[part 12 of 22: package /Cluster]
AUTOSAR XML (schema 4-3-0)
package /Cluster  (continued)
  can cluster E3V_K2CANFD: baudrate=500000, protocol-name=CAN, protocol-version=2.0, bus-off-recovery={bor-counter-l-1-to-l-2=1, bor-time-l-1=0.05, bor-time-l-2=0.2}, can-fd-baudrate=500000  (continued)
    can physical channel CHNL: comm-connectors=CN_E3V_K2CANFD  (continued)
      frame ZV_01_XIX_E3V_K2CANFD: id 0x184, to SAM, frame-length=8, can-addressing-mode=STANDARD, can-frame-rx-behavior=CAN-FD, can-frame-tx-behavior=CAN-FD
        pdu ZV_01_XIX_E3V_K2CANFD: length=8, transmission-mode-false-timing={cyclic-timing={time-offset=0.0, time-period=1.0}, event-controlled-timing={number-of-repetitions=5, repetition-period=0.02}}, transmission-mode-true-timing=cyclic-timing={time-offset=0.0, time-period=0.02}, unused-bit-pattern=0
          transmission-mode-conditions:
            {data-filter={data-filter-type=MASKED-NEW-DIFFERS-X, mask=1, x=0}, i-signal-in-i-pdu=ZV_01_XIX_E3V_K2CANFD/ZV_FT_verriegeln}
            {data-filter={data-filter-type=MASKED-NEW-DIFFERS-X, mask=1, x=0}, i-signal-in-i-pdu=ZV_01_XIX_E3V_K2CANFD/ZV_FT_entriegeln}
            {data-filter={data-filter-type=MASKED-NEW-DIFFERS-X, mask=1, x=0}, i-signal-in-i-pdu=ZV_01_XIX_E3V_K2CANFD/ZV_BT_verriegeln}
            {data-filter={data-filter-type=MASKED-NEW-DIFFERS-X, mask=1, x=0}, i-signal-in-i-pdu=ZV_01_XIX_E3V_K2CANFD/ZV_BT_entriegeln}
            {data-filter={data-filter-type=MASKED-NEW-DIFFERS-X, mask=1, x=0}, i-signal-in-i-pdu=ZV_01_XIX_E3V_K2CANFD/ZV_HFS_verriegeln}
            {data-filter={data-filter-type=MASKED-NEW-DIFFERS-X, mask=1, x=0}, i-signal-in-i-pdu=ZV_01_XIX_E3V_K2CANFD/ZV_HFS_entriegeln}
            {data-filter={data-filter-type=MASKED-NEW-DIFFERS-X, mask=1, x=0}, i-signal-in-i-pdu=ZV_01_XIX_E3V_K2CANFD/ZV_HBFS_verriegeln}
            {data-filter={data-filter-type=MASKED-NEW-DIFFERS-X, mask=1, x=0}, i-signal-in-i-pdu=ZV_01_XIX_E3V_K2CANFD/ZV_HBFS_entriegeln}
            {data-filter={data-filter-type=MASKED-NEW-DIFFERS-X, mask=1, x=0}, i-signal-in-i-pdu=ZV_01_XIX_E3V_K2CANFD/ZV_zentral_safen}
            {data-filter={data-filter-type=MASKED-NEW-DIFFERS-X, mask=1, x=0}, i-signal-in-i-pdu=ZV_01_XIX_E3V_K2CANFD/ZV_zentral_entsafen}
            {data-filter={data-filter-type=MASKED-NEW-DIFFERS-X, mask=1, x=0}, i-signal-in-i-pdu=ZV_01_XIX_E3V_K2CANFD/ZV_Spg_Anklappen}
            {data-filter={data-filter-type=MASKED-NEW-DIFFERS-X, mask=1, x=0}, i-signal-in-i-pdu=ZV_Softtouch_betaetigt}
            {data-filter={data-filter-type=MASKED-NEW-DIFFERS-X, mask=1, x=0}, i-signal-in-i-pdu=ZV_01_XIX_E3V_K2CANFD/ZV_LED_Steuerung}
            {data-filter={data-filter-type=MASKED-NEW-DIFFERS-X, mask=1, x=0}, i-signal-in-i-pdu=ZV_01_XIX_E3V_K2CANFD/ZV_LED_Uebernahme}
            {data-filter={data-filter-type=MASKED-NEW-DIFFERS-X, mask=1, x=0}, i-signal-in-i-pdu=ZV_auf_FT}
            {data-filter={data-filter-type=MASKED-NEW-DIFFERS-X, mask=1, x=0}, i-signal-in-i-pdu=ZV_zu_FT}
            {data-filter={data-filter-type=MASKED-NEW-DIFFERS-X, mask=1, x=0}, i-signal-in-i-pdu=ZV_auf_BT}
            {data-filter={data-filter-type=MASKED-NEW-DIFFERS-X, mask=1, x=0}, i-signal-in-i-pdu=ZV_zu_BT}
            {data-filter={data-filter-type=MASKED-NEW-DIFFERS-X, mask=1, x=0}, i-signal-in-i-pdu=ZV_auf_Kessy}
            {data-filter={data-filter-type=MASKED-NEW-DIFFERS-X, mask=1, x=0}, i-signal-in-i-pdu=ZV_zu_Kessy}
            {data-filter={data-filter-type=MASKED-NEW-DIFFERS-X, mask=1, x=0}, i-signal-in-i-pdu=ZV_01_XIX_E3V_K2CANFD/ZV_auf_Funk}
            {data-filter={data-filter-type=MASKED-NEW-DIFFERS-X, mask=1, x=0}, i-signal-in-i-pdu=ZV_zu_Funk}
            {data-filter={data-filter-type=MASKED-NEW-DIFFERS-X, mask=1, x=0}, i-signal-in-i-pdu=VIP_Sensor_betaetigt}
            {data-filter={data-filter-type=MASKED-NEW-DIFFERS-X, mask=1, x=0}, i-signal-in-i-pdu=ZV_01_XIX_E3V_K2CANFD/ZV_zu_Zeitl_Nachverr}
            {data-filter={data-filter-type=MASKED-NEW-DIFFERS-X, mask=1, x=0}, i-signal-in-i-pdu=ZV_HSK_entriegeln}
            {data-filter={data-filter-type=MASKED-NEW-DIFFERS-X, mask=1, x=0}, i-signal-in-i-pdu=ZV_HSK_verriegeln}
            {data-filter={data-filter-type=MASKED-NEW-DIFFERS-X, mask=1, x=0}, i-signal-in-i-pdu=ZV_Verdeck_zu}
            {data-filter={data-filter-type=MASKED-NEW-DIFFERS-X, mask=1, x=0}, i-signal-in-i-pdu=ZV_Verdeck_auf}
            {data-filter={data-filter-type=MASKED-NEW-DIFFERS-X, mask=1, x=0}, i-signal-in-i-pdu=FH_FT_hoch}
            {data-filter={data-filter-type=MASKED-NEW-DIFFERS-X, mask=1, x=0}, i-signal-in-i-pdu=FH_FT_tief}
            {data-filter={data-filter-type=MASKED-NEW-DIFFERS-X, mask=1, x=0}, i-signal-in-i-pdu=FH_BT_hoch}
            {data-filter={data-filter-type=MASKED-NEW-DIFFERS-X, mask=1, x=0}, i-signal-in-i-pdu=FH_BT_tief}
            {data-filter={data-filter-type=MASKED-NEW-DIFFERS-X, mask=1, x=0}, i-signal-in-i-pdu=FH_HFS_hoch}
            {data-filter={data-filter-type=MASKED-NEW-DIFFERS-X, mask=1, x=0}, i-signal-in-i-pdu=FH_HFS_tief}
            {data-filter={data-filter-type=MASKED-NEW-DIFFERS-X, mask=1, x=0}, i-signal-in-i-pdu=FH_HBFS_hoch}
            {data-filter={data-filter-type=MASKED-NEW-DIFFERS-X, mask=1, x=0}, i-signal-in-i-pdu=FH_HBFS_tief}
            {data-filter={data-filter-type=MASKED-NEW-DIFFERS-X, mask=65535, x=0}, i-signal-in-i-pdu=ZV_01_XIX_E3V_K2CANFD/ZV_Signatur}
            {data-filter={data-filter-type=MASKED-NEW-DIFFERS-X, mask=1, x=0}, i-signal-in-i-pdu=ZV_entriegeln_Anf}
            {data-filter={data-filter-type=MASKED-NEW-DIFFERS-X, mask=1, x=0}, i-signal-in-i-pdu=ZV_01_XIX_E3V_K2CANFD/ZV_auto_Ansteuerung}
          signal ZV_01_CRC_XIX_ZV_01_XIX_E3V_K2CANFD: start 0, 8 bit, little-endian, data-type-policy=OVERRIDE, i-signal-type=PRIMITIVE, init-value=0, base-type=BT_ZV_01_CRC, compu {phys=raw for raw 0..255}, range phys 0..255, raw 0..255, transfer-property=PENDING  # Für MLB: "Berechnung siehe Lastenheft "Kommunikationsabsicherung für FlexRay und CAN"" Ab MQB und MLBevo: "Berechnung siehe Lastenheft "End-to-End Kommunikationsabsicherung"" Endwerte siehe Begleitdokument "S-PDU Kennungsfolgen"
          signal ZV_01_BZ_XIX_ZV_01_XIX_E3V_K2CANFD: start 8, 4 bit, little-endian, data-type-policy=OVERRIDE, i-signal-type=PRIMITIVE, init-value=0, base-type=BT_ZV_01_BZ, compu {phys=raw for raw 0..15}, range phys 0..15, raw 0..15, transfer-property=PENDING
          signal ZV_FT_verriegeln_XIX_ZV_01_XIX_E3V_K2CANFD: start 12, 1 bit, little-endian, data-type-policy=OVERRIDE, i-signal-type=PRIMITIVE, init-value=0, base-type=BT_ZV_FT_verriegeln, compu {0=Cx0_FT_nicht_verriegeln (CM_ZV_FT_verriegeln_Cx0_FT_nicht_verriegeln), 1=Cx1_FT_verriegeln (CM_ZV_FT_verriegeln_Cx1_FT_verriegeln)}, range raw 0..1, transfer-property=PENDING  # Verriegelungsanforderung ZV für FT
          signal ZV_FT_entriegeln_XIX_ZV_01_XIX_E3V_K2CANFD: start 13, 1 bit, little-endian, data-type-policy=OVERRIDE, i-signal-type=PRIMITIVE, init-value=0, base-type=BT_ZV_FT_entriegeln, compu {0=Cx0_FT_nicht_entriegeln (CM_ZV_FT_entriegeln_Cx0_FT_nicht_entriegeln), 1=Cx1_FT_entriegeln (CM_ZV_FT_entriegeln_Cx1_FT_entriegeln)}, range raw 0..1, transfer-property=PENDING  # Entriegelungsanforderung ZV für FT
          signal ZV_BT_verriegeln_XIX_ZV_01_XIX_E3V_K2CANFD: start 14, 1 bit, little-endian, data-type-policy=OVERRIDE, i-signal-type=PRIMITIVE, init-value=0, base-type=BT_ZV_BT_verriegeln, compu {0=Cx0_BT_nicht_verriegeln (CM_ZV_BT_verriegeln_Cx0_BT_nicht_verriegeln), 1=Cx1_BT_verriegeln (CM_ZV_BT_verriegeln_Cx1_BT_verriegeln)}, range raw 0..1, transfer-property=PENDING  # Verriegelungsanforderung ZV für BT
          signal ZV_BT_entriegeln_XIX_ZV_01_XIX_E3V_K2CANFD: start 15, 1 bit, little-endian, data-type-policy=OVERRIDE, i-signal-type=PRIMITIVE, init-value=0, base-type=BT_ZV_BT_entriegeln, compu {0=Cx0_BT_nicht_entriegeln (CM_ZV_BT_entriegeln_Cx0_BT_nicht_entriegeln), 1=Cx1_BT_ist_zu_entriegeln (CM_ZV_BT_entriegeln_Cx1_BT_ist_zu_entriegeln)}, range raw 0..1, transfer-property=PENDING  # Beifahrertür entriegeln (Anforderung ZV)
          signal ZV_HFS_verriegeln_XIX_ZV_01_XIX_E3V_K2CANFD: start 16, 1 bit, little-endian, data-type-policy=OVERRIDE, i-signal-type=PRIMITIVE, init-value=0, base-type=BT_ZV_HFS_verriegeln, compu {0=Cx0_inaktiv (CM_ZV_HFS_verriegeln_Cx0_inaktiv), 1=Cx1_aktiv (CM_ZV_HFS_verriegeln_Cx1_aktiv)}, range raw 0..1, transfer-property=PENDING, to SAM(timeout 5 s)  # Verriegelungsanforderung ZV für HFS
          signal ZV_HFS_entriegeln_XIX_ZV_01_XIX_E3V_K2CANFD: start 17, 1 bit, little-endian, data-type-policy=OVERRIDE, i-signal-type=PRIMITIVE, init-value=0, base-type=BT_ZV_HFS_entriegeln, compu {0=Cx0_inaktiv (CM_ZV_HFS_entriegeln_Cx0_inaktiv), 1=Cx1_aktiv (CM_ZV_HFS_entriegeln_Cx1_aktiv)}, range raw 0..1, transfer-property=PENDING, to SAM(timeout 5 s)  # Entriegelungsanforderung ZV für HFS
          signal ZV_HBFS_verriegeln_XIX_ZV_01_XIX_E3V_K2CANFD: start 18, 1 bit, little-endian, data-type-policy=OVERRIDE, i-signal-type=PRIMITIVE, init-value=0, base-type=BT_ZV_HBFS_verriegeln, compu {0=Cx0_inaktiv (CM_ZV_HBFS_verriegeln_Cx0_inaktiv), 1=Cx1_aktiv (CM_ZV_HBFS_verriegeln_Cx1_aktiv)}, range raw 0..1, transfer-property=PENDING, to SAM(timeout 5 s)  # Verriegelungsanforderung ZV für HBFS
          signal ZV_HBFS_entriegeln_XIX_ZV_01_XIX_E3V_K2CANFD: start 19, 1 bit, little-endian, data-type-policy=OVERRIDE, i-signal-type=PRIMITIVE, init-value=0, base-type=BT_ZV_HBFS_entriegeln, compu {0=Cx0_inaktiv (CM_ZV_HBFS_entriegeln_Cx0_inaktiv), 1=Cx1_aktiv (CM_ZV_HBFS_entriegeln_Cx1_aktiv)}, range raw 0..1, transfer-property=PENDING, to SAM(timeout 5 s)  # Entriegelungsanforderung ZV für HBFS
          signal ZV_zentral_safen_XIX_ZV_01_XIX_E3V_K2CANFD: start 20, 1 bit, little-endian, data-type-policy=OVERRIDE, i-signal-type=PRIMITIVE, init-value=0, base-type=BT_ZV_zentral_safen, compu {0=Cx0_nicht_safen (CM_ZV_zentral_safen_Cx0_nicht_safen), 1=Cx1_Befehl_zentral_safen (CM_ZV_zentral_safen_Cx1_Befehl_zentral_safen)}, range raw 0..1, transfer-property=PENDING, to SAM(timeout 5 s)  # Zentral safen
          signal ZV_zentral_entsafen_XIX_ZV_01_XIX_E3V_K2CANFD: start 21, 1 bit, little-endian, data-type-policy=OVERRIDE, i-signal-type=PRIMITIVE, init-value=0, base-type=BT_ZV_zentral_entsafen, compu {0=Cx0_Init (CM_ZV_zentral_entsafen_Cx0_Init), 1=Cx1_Befehl_zentral_entsafen (CM_ZV_zentral_entsafen_Cx1_Befehl_zentral_entsafen)}, range raw 0..1, transfer-property=PENDING, to SAM(timeout 5 s)  # Zentral entsafen
          signal ZV_Spg_Anklappen_XIX_ZV_01_XIX_E3V_K2CANFD: start 22, 1 bit, little-endian, data-type-policy=OVERRIDE, i-signal-type=PRIMITIVE, init-value=0, base-type=BT_ZV_Spg_Anklappen, compu {0=Cx0_inaktiv (CM_ZV_Spg_Anklappen_Cx0_inaktiv), 1=Cx1_aktiv (CM_ZV_Spg_Anklappen_Cx1_aktiv)}, range raw 0..1, transfer-property=PENDING  # Anforderung über ZV: Spiegel sind anzuklappen
          signal ZV_Softtouch_betaetigt_XIX_ZV_01_XIX_E3V_K2CANFD: start 23, 1 bit, little-endian, data-type-policy=OVERRIDE, i-signal-type=PRIMITIVE, init-value=0, base-type=BT_ZV_Softtouch_betaetigt, compu {0=Cx0_Softtouch_nicht_betaetigt (CM_ZV_Softtouch_betaetigt_Cx0_Softtouch_nicht_betaetigt), 1=Cx1_Softtouch_betaetigt (CM_ZV_Softtouch_betaetigt_Cx1_Softtouch_betaetigt)}, range raw 0..1, transfer-property=PENDING  # Betätigung Softtouch
          signal ZV_LED_Steuerung_XIX_ZV_01_XIX_E3V_K2CANFD: start 24, 1 bit, little-endian, data-type-policy=OVERRIDE, i-signal-type=PRIMITIVE, init-value=0, base-type=BT_ZV_LED_Steuerung, compu {0=Cx0_LED_aus (CM_ZV_LED_Steuerung_Cx0_LED_aus), 1=Cx1_LED_ein (CM_ZV_LED_Steuerung_Cx1_LED_ein)}, range raw 0..1, transfer-property=PENDING  # Ansteuerung der LED's in den Tueren; BAF gilt nicht für dieses Bit
          signal ZV_LED_Uebernahme_XIX_ZV_01_XIX_E3V_K2CANFD: start 25, 1 bit, little-endian, data-type-policy=OVERRIDE, i-signal-type=PRIMITIVE, init-value=0, base-type=BT_ZV_LED_Uebernahme, compu {0=Cx0_Init (CM_ZV_LED_Uebernahme_Cx0_Init), 1=Cx1_TSG_uebernimmt_LED_Steuerung (CM_ZV_LED_Uebernahme_Cx1_TSG_uebernimmt_LED_Steuerung)}, range raw 0..1, transfer-property=PENDING  # Uebernahme der LED Steuerung durch das TSG FT
          signal ZV_auf_FT_XIX_ZV_01_XIX_E3V_K2CANFD: start 26, 1 bit, little-endian, data-type-policy=OVERRIDE, i-signal-type=PRIMITIVE, init-value=0, base-type=BT_ZV_auf_FT, compu {0=Cx0_nicht_betaetigt (CM_ZV_auf_FT_Cx0_nicht_betaetigt), 1=Cx1_betaetigt (CM_ZV_auf_FT_Cx1_betaetigt)}, range raw 0..1, transfer-property=PENDING, to SAM(timeout 5 s)  # ZV Schliessstelle
          signal ZV_zu_FT_XIX_ZV_01_XIX_E3V_K2CANFD: start 27, 1 bit, little-endian, data-type-policy=OVERRIDE, i-signal-type=PRIMITIVE, init-value=0, base-type=BT_ZV_zu_FT, compu {0=Cx0_nicht_betaetigt (CM_ZV_zu_FT_Cx0_nicht_betaetigt), 1=Cx1_betaetigt (CM_ZV_zu_FT_Cx1_betaetigt)}, range raw 0..1, transfer-property=PENDING  # ZV Schliessstelle
          signal ZV_auf_BT_XIX_ZV_01_XIX_E3V_K2CANFD: start 28, 1 bit, little-endian, data-type-policy=OVERRIDE, i-signal-type=PRIMITIVE, init-value=0, base-type=BT_ZV_auf_BT, compu {0=Cx0_nicht_betaetigt (CM_ZV_auf_BT_Cx0_nicht_betaetigt), 1=Cx1_betaetigt (CM_ZV_auf_BT_Cx1_betaetigt)}, range raw 0..1, transfer-property=PENDING, to SAM(timeout 5 s)  # ZV Schliessstelle
          signal ZV_zu_BT_XIX_ZV_01_XIX_E3V_K2CANFD: start 29, 1 bit, little-endian, data-type-policy=OVERRIDE, i-signal-type=PRIMITIVE, init-value=0, base-type=BT_ZV_zu_BT, compu {0=Cx0_nicht_betaetigt (CM_ZV_zu_BT_Cx0_nicht_betaetigt), 1=Cx1_betaetigt (CM_ZV_zu_BT_Cx1_betaetigt)}, range raw 0..1, transfer-property=PENDING  # ZV Schliessstelle
          signal ZV_auf_Kessy_XIX_ZV_01_XIX_E3V_K2CANFD: start 30, 1 bit, little-endian, data-type-policy=OVERRIDE, i-signal-type=PRIMITIVE, init-value=0, base-type=BT_ZV_auf_Kessy, transfer-property=PENDING, to SAM(timeout 5 s)  # ZV Schliessstelle
          signal ZV_zu_Kessy_XIX_ZV_01_XIX_E3V_K2CANFD: start 31, 1 bit, little-endian, data-type-policy=OVERRIDE, i-signal-type=PRIMITIVE, init-value=0, base-type=BT_ZV_zu_Kessy, transfer-property=PENDING, to SAM(timeout 5 s)  # ZV Schliessstelle
          signal ZV_auf_Funk_XIX_ZV_01_XIX_E3V_K2CANFD: start 32, 1 bit, little-endian, data-type-policy=OVERRIDE, i-signal-type=PRIMITIVE, init-value=0, base-type=BT_ZV_auf_Funk, compu {0=Cx0_nicht_betaetigt (CM_ZV_auf_Funk_Cx0_nicht_betaetigt), 1=Cx1_betaetigt (CM_ZV_auf_Funk_Cx1_betaetigt)}, range raw 0..1, transfer-property=PENDING, to SAM(timeout 5 s)  # ZV Schliessstelle
          signal ZV_zu_Funk_XIX_ZV_01_XIX_E3V_K2CANFD: start 33, 1 bit, little-endian, data-type-policy=OVERRIDE, i-signal-type=PRIMITIVE, init-value=0, base-type=BT_ZV_zu_Funk, compu {0=Cx0_nicht_betaetigt (CM_ZV_zu_Funk_Cx0_nicht_betaetigt), 1=Cx1_betaetigt (CM_ZV_zu_Funk_Cx1_betaetigt)}, range raw 0..1, transfer-property=PENDING, to SAM(timeout 5 s)  # ZV Schliessstelle
          signal VIP_Sensor_betaetigt_XIX_ZV_01_XIX_E3V_K2CANFD: start 34, 1 bit, little-endian, data-type-policy=OVERRIDE, i-signal-type=PRIMITIVE, init-value=0, base-type=BT_VIP_Sensor_betaetigt, compu {0=Cx0_Heckentr_VIP_nicht_angefordert (CM_VIP_Sensor_betaetigt_Cx0_Heckentr_VIP_nicht_angefordert), 1=Cx1_Heckentr_VIP_angefordert (CM_VIP_Sensor_betaetigt_Cx1_Heckentr_VIP_angefordert)}, range raw 0..1, transfer-property=PENDING, to SAM(timeout 5 s)  # Heckentriegelung durch die Bedienstelle Virtuelles Pedal(VIP) erkannt. Der VIP Sensor hat eine Fusskickbewegung erkannt und es wurde ein Kessy - Schlüssel im Heckaussenbereich erkannt.
          signal VIP_Freigabe_XIX_ZV_01_XIX_E3V_K2CANFD: start 35, 1 bit, little-endian, data-type-policy=OVERRIDE, i-signal-type=PRIMITIVE, init-value=0, base-type=BT_VIP_Freigabe, compu {0=Cx0_keine_Freigabe (CM_VIP_Freigabe_Cx0_keine_Freigabe), 1=Cx1_Freigabe (CM_VIP_Freigabe_Cx1_Freigabe)}, range raw 0..1, transfer-property=PENDING  # Vituelles Pedal ist über HMI freigeschaltet.
          signal ZV_zu_Zeitl_Nachverr_XIX_ZV_01_XIX_E3V_K2CANFD: start 36, 1 bit, little-endian, data-type-policy=OVERRIDE, i-signal-type=PRIMITIVE, init-value=0, base-type=BT_ZV_zu_Zeitl_Nachverr, compu {0=Cx0_Init (CM_ZV_zu_Zeitl_Nachverr_Cx0_Init), 1=Cx1_Nachverriegeln (CM_ZV_zu_Zeitl_Nachverr_Cx1_Nachverriegeln)}, range raw 0..1, transfer-property=PENDING  # ZV Schliessstelle
          signal ZV_HSK_entriegeln_XIX_ZV_01_XIX_E3V_K2CANFD: start 37, 1 bit, little-endian, data-type-policy=OVERRIDE, i-signal-type=PRIMITIVE, init-value=0, base-type=BT_ZV_HSK_entriegeln, compu {0=Cx0_Handschuhkasten_nicht_entriegeln (CM_ZV_HSK_entriegeln_Cx0_Handschuhkasten_nicht_entriegeln) (Handschuhkasten nicht entriegeln), 1=Cx1_Handschuhkasten_entriegeln (CM_ZV_HSK_entriegeln_Cx1_Handschuhkasten_entriegeln) (Handschuhkasten entriegeln)}, range raw 0..1, transfer-property=PENDING  # Anforderungssignal zur Ansteuerung des Handschuhkastenmotors in Richtung Entriegeln.
          signal ZV_HSK_verriegeln_XIX_ZV_01_XIX_E3V_K2CANFD: start 38, 1 bit, little-endian, data-type-policy=OVERRIDE, i-signal-type=PRIMITIVE, init-value=0, base-type=BT_ZV_HSK_verriegeln, compu {0=Cx0_Handschuhkasten_nicht_verriegeln (CM_ZV_HSK_verriegeln_Cx0_Handschuhkasten_nicht_verriegeln) (Handschuhkasten nicht verriegeln), 1=Cx1_Handschuhkasten_verriegelt (CM_ZV_HSK_verriegeln_Cx1_Handschuhkasten_verriegelt)}, range raw 0..1, transfer-property=PENDING  # Anforderungssignal zur Ansteuerung des Handschuhkastenmotors in Richtung Verriegeln.
          signal ZV_Verdeck_zu_XIX_ZV_01_XIX_E3V_K2CANFD: start 39, 1 bit, little-endian, data-type-policy=OVERRIDE, i-signal-type=PRIMITIVE, init-value=0, base-type=BT_ZV_Verdeck_zu, compu {0=Cx0_inaktiv (CM_ZV_Verdeck_zu_Cx0_inaktiv), 1=Cx1_aktiv (CM_ZV_Verdeck_zu_Cx1_aktiv)}, range raw 0..1, transfer-property=PENDING  # Anforderungssignal für ein Komfortschließen des Verdecks. Signal wird angefordert wenn SKontakt = 0 und eine Doppelbetätigung Schließzylinder_Zu oder Funkfernbedienung_Taste_zu innerhalb zwei Sekunden empfangen wird. Signal wird auch angefordert wenn SKontakt = 0 und das Verdeck sich in Zwischenposition befindet und eine Einfachbetätigung Schließzylinder_Zu oder Taste _Funkfernbedienung_Zu erkannt wird.
          signal ZV_Verdeck_auf_XIX_ZV_01_XIX_E3V_K2CANFD: start 40, 1 bit, little-endian, data-type-policy=OVERRIDE, i-signal-type=PRIMITIVE, init-value=0, base-type=BT_ZV_Verdeck_auf, compu {0=Cx0_inaktiv (CM_ZV_Verdeck_auf_Cx0_inaktiv), 1=Cx1_aktiv (CM_ZV_Verdeck_auf_Cx1_aktiv)}, range raw 0..1, transfer-property=PENDING  # Anforderungssignal für ein Komfortöffnen des Verdecks. Signal wird angefordert wenn SKontakt = 0 und eine Doppelbetätigung Schließzylinder_auf oder Funkfernbedienung_Taste_auf innerhalb zwei Sekunden empfangen wird. Signal wird auch angefordert wenn SKontakt = 0 und das Verdeck sich in Zwischenposition befindet und eine Einfachbetätigung Schließzylinder_Auf oder Taste _Funkfernbedienung_auf erkannt wird.
          signal FH_FT_hoch_XIX_ZV_01_XIX_E3V_K2CANFD: start 41, 1 bit, little-endian, data-type-policy=OVERRIDE, i-signal-type=PRIMITIVE, init-value=0, base-type=BT_FH_FT_hoch, compu {0=Cx0_keine_Anforderung (CM_FH_FT_hoch_Cx0_keine_Anforderung), 1=Cx1_FT_hoch (CM_FH_FT_hoch_Cx1_FT_hoch)}, range raw 0..1, transfer-property=PENDING  # Freigabeinformation fuer die FH-Komfortfunktion
          signal FH_FT_tief_XIX_ZV_01_XIX_E3V_K2CANFD: start 42, 1 bit, little-endian, data-type-policy=OVERRIDE, i-signal-type=PRIMITIVE, init-value=0, base-type=BT_FH_FT_tief, compu {0=Cx0_keine_Anforderung (CM_FH_FT_tief_Cx0_keine_Anforderung), 1=Cx1_FT_tief (CM_FH_FT_tief_Cx1_FT_tief)}, range raw 0..1, transfer-property=PENDING  # Freigabeinformation fuer die FH-Komfortfunktion
          signal FH_BT_hoch_XIX_ZV_01_XIX_E3V_K2CANFD: start 43, 1 bit, little-endian, data-type-policy=OVERRIDE, i-signal-type=PRIMITIVE, init-value=0, base-type=BT_FH_BT_hoch, compu {0=Cx0_keine_Anforderung (CM_FH_BT_hoch_Cx0_keine_Anforderung), 1=Cx1_BT_hoch (CM_FH_BT_hoch_Cx1_BT_hoch)}, range raw 0..1, transfer-property=PENDING  # Freigabeinformation fuer die FH-Komfortfunktion
          signal FH_BT_tief_XIX_ZV_01_XIX_E3V_K2CANFD: start 44, 1 bit, little-endian, data-type-policy=OVERRIDE, i-signal-type=PRIMITIVE, init-value=0, base-type=BT_FH_BT_tief, compu {0=Cx0_keine_Anforderung (CM_FH_BT_tief_Cx0_keine_Anforderung), 1=Cx1_BT_tief (CM_FH_BT_tief_Cx1_BT_tief)}, range raw 0..1, transfer-property=PENDING  # Freigabeinformation fuer die FH-Komfortfunktion
          signal FH_HFS_hoch_XIX_ZV_01_XIX_E3V_K2CANFD: start 45, 1 bit, little-endian, data-type-policy=OVERRIDE, i-signal-type=PRIMITIVE, init-value=0, base-type=BT_FH_HFS_hoch, compu {0=Cx0_inaktiv (CM_FH_HFS_hoch_Cx0_inaktiv), 1=Cx1_aktiv (CM_FH_HFS_hoch_Cx1_aktiv)}, range raw 0..1, transfer-property=PENDING, to SAM(timeout 5 s)  # Freigabeinformation fuer die FH-Komfortfunktion
          signal FH_HFS_tief_XIX_ZV_01_XIX_E3V_K2CANFD: start 46, 1 bit, little-endian, data-type-policy=OVERRIDE, i-signal-type=PRIMITIVE, init-value=0, base-type=BT_FH_HFS_tief, compu {0=Cx0_inaktiv (CM_FH_HFS_tief_Cx0_inaktiv), 1=Cx1_aktiv (CM_FH_HFS_tief_Cx1_aktiv)}, range raw 0..1, transfer-property=PENDING, to SAM(timeout 5 s)  # Freigabeinformation fuer die FH-Komfortfunktion
          signal FH_HBFS_hoch_XIX_ZV_01_XIX_E3V_K2CANFD: start 47, 1 bit, little-endian, data-type-policy=OVERRIDE, i-signal-type=PRIMITIVE, init-value=0, base-type=BT_FH_HBFS_hoch, compu {0=Cx0_inaktiv (CM_FH_HBFS_hoch_Cx0_inaktiv), 1=Cx1_aktiv (CM_FH_HBFS_hoch_Cx1_aktiv)}, range raw 0..1, transfer-property=PENDING, to SAM(timeout 5 s)  # Freigabeinformation fuer die FH-Komfortfunktion
          signal FH_HBFS_tief_XIX_ZV_01_XIX_E3V_K2CANFD: start 48, 1 bit, little-endian, data-type-policy=OVERRIDE, i-signal-type=PRIMITIVE, init-value=0, base-type=BT_FH_HBFS_tief, compu {0=Cx0_inaktiv (CM_FH_HBFS_tief_Cx0_inaktiv), 1=Cx1_aktiv (CM_FH_HBFS_tief_Cx1_aktiv)}, range raw 0..1, transfer-property=PENDING, to SAM(timeout 5 s)  # Freigabeinformation fuer die FH-Komfortfunktion
          signal BCM_Spg_Synchron_XIX_ZV_01_XIX_E3V_K2CANFD: start 49, 1 bit, little-endian, data-type-policy=OVERRIDE, i-signal-type=PRIMITIVE, init-value=0, base-type=BT_BCM_Spg_Synchron, compu {0=Cx0_inaktiv (CM_BCM_Spg_Synchron_Cx0_inaktiv), 1=Cx1_aktiv (CM_BCM_Spg_Synchron_Cx1_aktiv)}, range raw 0..1, transfer-property=PENDING  # Anforderung zur Aktivierung der synchronen Spiegelverstellung
          signal BCM_BF_Spg_Absenkung_XIX_ZV_01_XIX_E3V_K2CANFD: start 50, 1 bit, little-endian, data-type-policy=OVERRIDE, i-signal-type=PRIMITIVE, init-value=0, base-type=BT_BCM_BF_Spg_Absenkung, compu {0=Cx0_inaktiv (CM_BCM_BF_Spg_Absenkung_Cx0_inaktiv), 1=Cx1_aktiv (CM_BCM_BF_Spg_Absenkung_Cx1_aktiv)}, range raw 0..1, transfer-property=PENDING  # Spiegelabsenkung Beifahrerseite
          signal ZV_Signatur_XIX_ZV_01_XIX_E3V_K2CANFD: start 51, 11 bit, little-endian, data-type-policy=OVERRIDE, i-signal-type=PRIMITIVE, init-value=0, base-type=BT_ZV_Signatur, compu {phys=raw for raw 0..2047}, range phys 0..2047, raw 0..2047, transfer-property=PENDING  # Signatur der ZV
          signal ZV_entriegeln_Anf_XIX_ZV_01_XIX_E3V_K2CANFD: start 62, 1 bit, little-endian, data-type-policy=OVERRIDE, i-signal-type=PRIMITIVE, init-value=0, base-type=BT_ZV_entriegeln_Anf, compu {0=Cx0_nicht_betaetigt (CM_ZV_entriegeln_Anf_Cx0_nicht_betaetigt), 1=Cx1_betaetigt (CM_ZV_entriegeln_Anf_Cx1_betaetigt)}, range raw 0..1, transfer-property=PENDING  # Bei ZV Anforderung erfolgt die Entriegelung des Ladesteckers
          signal ZV_auto_Ansteuerung_XIX_ZV_01_XIX_E3V_K2CANFD: start 63, 1 bit, little-endian, data-type-policy=OVERRIDE, i-signal-type=PRIMITIVE, init-value=0, base-type=BT_ZV_auto_Ansteuerung, compu {0=Cx0_Kein_Autolock_Unlock (CM_ZV_auto_Ansteuerung_Cx0_Kein_Autolock_Unlock), 1=Cx1_Autolock_Unlock (CM_ZV_auto_Ansteuerung_Cx1_Autolock_Unlock)}, range raw 0..1, transfer-property=PENDING  # Kennung für die automatische Ansteuerung der Zentralverriegelung (Autolock/Autounlock)
      frame ZV_02_XIX_E3V_K2CANFD: id 0x583, to SAM, frame-length=8, can-addressing-mode=STANDARD, can-frame-rx-behavior=CAN-FD, can-frame-tx-behavior=CAN-FD
        pdu ZV_02_XIX_E3V_K2CANFD: length=8, minimum-delay=0.02, transmission-mode-false-timing={cyclic-timing={time-offset=0.0, time-period=0.2}, event-controlled-timing={number-of-repetitions=3, repetition-period=0.05}}, transmission-mode-true-timing={cyclic-timing={time-offset=0.0, time-period=0.05}, event-controlled-timing={number-of-repetitions=0, repetition-period=0.0}}, unused-bit-pattern=0
          transmission-mode-conditions:
            {data-filter={data-filter-type=MASKED-NEW-DIFFERS-X, mask=1, x=0}, i-signal-in-i-pdu=ZV_verriegeln_Anf}
            {data-filter={data-filter-type=MASKED-NEW-DIFFERS-X, mask=1, x=0}, i-signal-in-i-pdu=ZV_Anf_Challenge_Auth}
            {data-filter={data-filter-type=MASKED-NEW-DIFFERS-X, mask=1, x=0}, i-signal-in-i-pdu=ZV_eRWK_Umfeld_Pruefung}
            {data-filter={data-filter-type=MASKED-NEW-DIFFERS-X, mask=1, x=0}, i-signal-in-i-pdu=VIP_Sensor_STSG_HFS_betaetigt}
            {data-filter={data-filter-type=MASKED-NEW-DIFFERS-X, mask=1, x=0}, i-signal-in-i-pdu=VIP_Sensor_STSG_HBFS_betaetigt}
            {data-filter={data-filter-type=MASKED-NEW-DIFFERS-X, mask=1, x=0}, i-signal-in-i-pdu=FFB_HDF_Taste}
            {data-filter={data-filter-type=MASKED-NEW-DIFFERS-X, mask=1, x=0}, i-signal-in-i-pdu=FFB_Panik_Taste}
            {data-filter={data-filter-type=MASKED-NEW-DIFFERS-X, mask=1, x=0}, i-signal-in-i-pdu=FFB_Auf_Taste}
            {data-filter={data-filter-type=MASKED-NEW-DIFFERS-X, mask=1, x=0}, i-signal-in-i-pdu=FFB_Zu_Taste}
            {data-filter={data-filter-type=MASKED-NEW-DIFFERS-X, mask=1, x=0}, i-signal-in-i-pdu=FFB_CarFinder}
            {data-filter={data-filter-type=MASKED-NEW-DIFFERS-X, mask=1, x=0}, i-signal-in-i-pdu=FFB_Komfortoeffnen}
            {data-filter={data-filter-type=MASKED-NEW-DIFFERS-X, mask=1, x=0}, i-signal-in-i-pdu=FFB_Komfortschliessen}
            {data-filter={data-filter-type=MASKED-NEW-DIFFERS-X, mask=1, x=0}, i-signal-in-i-pdu=FBS_IDG_in_Reichweite}
          signal ZV_verriegeln_Anf_XIX_ZV_02_XIX_E3V_K2CANFD: start 0, 1 bit, little-endian, data-type-policy=OVERRIDE, i-signal-type=PRIMITIVE, init-value=0, base-type=BT_ZV_verriegeln_Anf, compu {0=Cx0_nicht_betaetigt (CM_ZV_verriegeln_Anf_Cx0_nicht_betaetigt), 1=Cx1_betaetigt (CM_ZV_verriegeln_Anf_Cx1_betaetigt)}, range raw 0..1, transfer-property=PENDING  # Gesammelte externe ZV-Verriegelungsanforderung des Kunden (z. B. zur Aktivierung der Anzeige des Ladezustands über Aussenlicht).
          signal ZV_STSG_HFS_Anf_XIX_ZV_02_XIX_E3V_K2CANFD: start 1, 1 bit, little-endian, data-type-policy=OVERRIDE, i-signal-type=PRIMITIVE, init-value=0, base-type=BT_ZV_STSG_HFS_Anf, compu {0=Cx0_keine_Anforderung (CM_ZV_STSG_HFS_Anf_Cx0_keine_Anforderung), 1=Cx1_Anforderung (CM_ZV_STSG_HFS_Anf_Cx1_Anforderung)}, range raw 0..1, transfer-property=TRIGGERED-ON-CHANGE-WITHOUT-REPETITION, to SAM(timeout 2 s)  # Die ZV fordert einen Lauf bzw. Stopp der Schiebetür an.
          signal ZV_STSG_HBFS_Anf_XIX_ZV_02_XIX_E3V_K2CANFD: start 2, 1 bit, little-endian, data-type-policy=OVERRIDE, i-signal-type=PRIMITIVE, init-value=0, base-type=BT_ZV_STSG_HBFS_Anf, compu {0=Cx0_keine_Anforderung (CM_ZV_STSG_HBFS_Anf_Cx0_keine_Anforderung), 1=Cx1_Anforderung (CM_ZV_STSG_HBFS_Anf_Cx1_Anforderung)}, range raw 0..1, transfer-property=TRIGGERED-ON-CHANGE-WITHOUT-REPETITION, to SAM(timeout 2 s)  # Die ZV fordert einen Lauf bzw. Stopp der Schiebetür an.
          signal ZV_Anf_Challenge_Auth_XIX_ZV_02_XIX_E3V_K2CANFD: start 3, 1 bit, little-endian, data-type-policy=OVERRIDE, i-signal-type=PRIMITIVE, init-value=0, base-type=BT_ZV_Anf_Challenge_Auth, compu {0=Cx0_nicht_aktiv (CM_ZV_Anf_Challenge_Auth_Cx0_nicht_aktiv), 1=Cx1_aktiv (CM_ZV_Anf_Challenge_Auth_Cx1_aktiv)}, range raw 0..1, transfer-property=PENDING, to SAM(timeout 2 s)  # Anforderung an alle beteiligten Steuergeräte die Challenge an den ZV-Master zu senden.
          signal ZV_eRWK_Umfeld_Pruefung_XIX_ZV_02_XIX_E3V_K2CANFD: start 6, 1 bit, little-endian, data-type-policy=OVERRIDE, i-signal-type=PRIMITIVE, init-value=0, base-type=BT_ZV_eRWK_Umfeld_Pruefung, compu {0=Cx0_nicht_aktiv (CM_ZV_eRWK_Umfeld_Pruefung_Cx0_nicht_aktiv), 1=Cx1_aktiv (CM_ZV_eRWK_Umfeld_Pruefung_Cx1_aktiv)}, range raw 0..1, transfer-property=PENDING  # Anforderung an PDC/PLA im eRWK-Modus eine Umfeldprüfung durchzuführen
          signal VIP_Sensor_STSG_HFS_betaetigt_XIX_ZV_02_XIX_E3V_K2CANFD: start 10, 1 bit, little-endian, data-type-policy=OVERRIDE, i-signal-type=PRIMITIVE, init-value=0, base-type=BT_VIP_Sensor_STSG_HFS_betaetigt, compu {0=Cx0_keine_VIP_Anforderung_STSG_HFS (CM_VIP_Sensor_STSG_HFS_betaetigt_Cx0_keine_VIP_Anforderung_STSG_HFS), 1=Cx1_VIP_Anforderung_STSG_HFS (CM_VIP_Sensor_STSG_HFS_betaetigt_Cx1_VIP_Anforderung_STSG_HFS)}, range raw 0..1, transfer-property=PENDING, to SAM(timeout 2 s)  # Schiebetürlauf HFS wurde durch VIP angefordert und als berechtigt eingestuft.
          signal VIP_Sensor_STSG_HBFS_betaetigt_XIX_ZV_02_XIX_E3V_K2CANFD: start 11, 1 bit, little-endian, data-type-policy=OVERRIDE, i-signal-type=PRIMITIVE, init-value=0, base-type=BT_VIP_Sensor_STSG_HBFS_betaetigt, compu {0=Cx0_keine_VIP_Anforderung_STSG_HBFS (CM_VIP_Sensor_STSG_HBFS_betaetigt_Cx0_keine_VIP_Anforderung_STSG_HBFS), 1=Cx1_VIP_Anforderung_STSG_HBFS (CM_VIP_Sensor_STSG_HBFS_betaetigt_Cx1_VIP_Anforderung_STSG_HBFS)}, range raw 0..1, transfer-property=PENDING, to SAM(timeout 2 s)  # Schiebetürlauf HBFS wurde durch VIP angefordert und als berechtigt eingestuft.
          signal BCM_FH_Freigabe_XIX_ZV_02_XIX_E3V_K2CANFD: start 12, 1 bit, little-endian, data-type-policy=OVERRIDE, i-signal-type=PRIMITIVE, init-value=0, base-type=BT_BCM_FH_Freigabe, compu {1=Cx1_Funktionsfreigabe_Fensterheber (CM_BCM_FH_Freigabe_Cx1_Funktionsfreigabe_Fensterheber) (Funktionsfreigabe Fensterheber)}, range raw 1, transfer-property=TRIGGERED-ON-CHANGE-WITHOUT-REPETITION, to SAM(timeout 2 s)  # Funktionsfreigabe Fensterheber
          signal BCM_Komfortfkt_Freigabe_XIX_ZV_02_XIX_E3V_K2CANFD: start 13, 1 bit, little-endian, data-type-policy=OVERRIDE, i-signal-type=PRIMITIVE, init-value=0, base-type=BT_BCM_Komfortfkt_Freigabe, compu {0=Cx0_Komfortfunktion_gesperrt (CM_BCM_Komfortfkt_Freigabe_Cx0_Komfortfunktion_gesperrt) (Komfortfunktion gesperrt), 1=Cx1_globale_Freigabe_der_Komfortfunktion_erteilt (CM_BCM_Komfortfkt_Freigabe_Cx1_globale_Freigabe_der_Komfortfunktion_erteilt) (globale Freigabe der Komfortfunktion erteilt)}, range raw 0..1, transfer-property=TRIGGERED-ON-CHANGE-WITHOUT-REPETITION, to SAM(timeout 2 s)  # globale Freigabe der Komfortfunktion
          signal BCM_HSK_Freigabe_XIX_ZV_02_XIX_E3V_K2CANFD: start 14, 1 bit, little-endian, data-type-policy=OVERRIDE, i-signal-type=PRIMITIVE, init-value=0, base-type=BT_BCM_HSK_Freigabe, compu {0=Cx0_erlauben (CM_BCM_HSK_Freigabe_Cx0_erlauben), 1=Cx1_sperren (CM_BCM_HSK_Freigabe_Cx1_sperren)}, range raw 0..1, transfer-property=TRIGGERED-ON-CHANGE-WITHOUT-REPETITION  # Handschuhkastenfreigabe
          signal BCM_Verdeck_Freigabe_XIX_ZV_02_XIX_E3V_K2CANFD: start 15, 1 bit, little-endian, data-type-policy=OVERRIDE, i-signal-type=PRIMITIVE, init-value=0, base-type=BT_BCM_Verdeck_Freigabe, compu {0=Cx0_Verdeckbetrieb_nicht_erlaubt (CM_BCM_Verdeck_Freigabe_Cx0_Verdeckbetrieb_nicht_erlaubt) (Verdeckbetrieb nicht erlaubt), 1=Cx1_Verdeckbetrieb_erlaubt (CM_BCM_Verdeck_Freigabe_Cx1_Verdeckbetrieb_erlaubt) (Verdeckbetrieb erlaubt)}, range raw 0..1, transfer-property=TRIGGERED-ON-CHANGE-WITHOUT-REPETITION  # Freigabe Verdeckbetrieb
          signal ZV_verriegelt_intern_ist_XIX_ZV_02_XIX_E3V_K2CANFD: start 16, 1 bit, little-endian, data-type-policy=OVERRIDE, i-signal-type=PRIMITIVE, init-value=0, base-type=BT_ZV_verriegelt_intern_ist, compu {1=Cx1_Fahrzeug_innen_verriegelt_Istzustand (CM_ZV_verriegelt_intern_ist_Cx1_Fahrzeug_innen_verriegelt_Istzustand) (Fahrzeug innen verriegelt; Istzustand)}, range raw 1, transfer-property=TRIGGERED-ON-CHANGE-WITHOUT-REPETITION, to SAM(timeout 2 s)  # Istzustand: Verriegelung Fahrzeug innen
          signal ZV_verriegelt_extern_ist_XIX_ZV_02_XIX_E3V_K2CANFD: start 17, 1 bit, little-endian, data-type-policy=OVERRIDE, i-signal-type=PRIMITIVE, init-value=0, base-type=BT_ZV_verriegelt_extern_ist, compu {1=Cx1_Fahrzeug_aussen_verriegelt_Istzustand (CM_ZV_verriegelt_extern_ist_Cx1_Fahrzeug_aussen_verriegelt_Istzustand)}, range raw 1, transfer-property=TRIGGERED-ON-CHANGE-WITHOUT-REPETITION, to SAM(timeout 2 s)  # Istzustand: Verriegelung Fahrzeug aussen
          signal ZV_verriegelt_intern_soll_XIX_ZV_02_XIX_E3V_K2CANFD: start 18, 1 bit, little-endian, data-type-policy=OVERRIDE, i-signal-type=PRIMITIVE, init-value=0, base-type=BT_ZV_verriegelt_intern_soll, compu {1=Cx1_Fahrzeug_verriegelt_intern_Sollzusstand (CM_ZV_verriegelt_intern_soll_Cx1_Fahrzeug_verriegelt_intern_Sollzusstand) (Fahrzeug verriegelt intern; Sollzusstand)}, range raw 1, transfer-property=TRIGGERED-ON-CHANGE-WITHOUT-REPETITION, to SAM(timeout 2 s)  # Sollzustand: Verriegelung Fahrzeug innen
          signal ZV_verriegelt_extern_soll_XIX_ZV_02_XIX_E3V_K2CANFD: start 19, 1 bit, little-endian, data-type-policy=OVERRIDE, i-signal-type=PRIMITIVE, init-value=0, base-type=BT_ZV_verriegelt_extern_soll, compu {1=Cx1_Fahrzeug_verriegelt_extern_Sollzusstand (CM_ZV_verriegelt_extern_soll_Cx1_Fahrzeug_verriegelt_extern_Sollzusstand) (Fahrzeug verriegelt extern; Sollzusstand)}, range raw 1, transfer-property=TRIGGERED-ON-CHANGE-WITHOUT-REPETITION, to SAM(timeout 2 s)  # Sollzustand: Verriegelung Fahrzeug aussen
          signal ZV_gesafet_extern_ist_XIX_ZV_02_XIX_E3V_K2CANFD: start 20, 1 bit, little-endian, data-type-policy=OVERRIDE, i-signal-type=PRIMITIVE, init-value=0, base-type=BT_ZV_gesafet_extern_ist, compu {1=Cx1_Fahrzeug_aussen_gesafet_Istzustand (CM_ZV_gesafet_extern_ist_Cx1_Fahrzeug_aussen_gesafet_Istzustand) (Fahrzeug aussen gesafet; Istzustand)}, range raw 1, transfer-property=TRIGGERED-ON-CHANGE-WITHOUT-REPETITION, to SAM(timeout 2 s)  # Istzustand: Fahrzeug aussen gesafet
          signal ZV_gesafet_extern_soll_XIX_ZV_02_XIX_E3V_K2CANFD: start 21, 1 bit, little-endian, data-type-policy=OVERRIDE, i-signal-type=PRIMITIVE, init-value=0, base-type=BT_ZV_gesafet_extern_soll, compu {1=Cx1_Fahrzeug_aussen_gesafet_Sollzustand (CM_ZV_gesafet_extern_soll_Cx1_Fahrzeug_aussen_gesafet_Sollzustand)}, range raw 1, transfer-property=TRIGGERED-ON-CHANGE-WITHOUT-REPETITION, to SAM(timeout 2 s)  # Sollzustand: Fahrzeug gesafet extern
          signal ZV_Einzeltuerentriegelung_XIX_ZV_02_XIX_E3V_K2CANFD: start 22, 1 bit, little-endian, data-type-policy=OVERRIDE, i-signal-type=PRIMITIVE, init-value=0, base-type=BT_ZV_Einzeltuerentriegelung, compu {1=Cx1_Fahrzeug_an_Einzeltuer_entriegelt (CM_ZV_Einzeltuerentriegelung_Cx1_Fahrzeug_an_Einzeltuer_entriegelt) (Fahrzeug an Einzeltuer entriegelt)}, range raw 1, transfer-property=TRIGGERED-ON-CHANGE-WITHOUT-REPETITION  # Einzeltürentriegelung ZV
          signal ZV_Heckeinzelentriegelung_XIX_ZV_02_XIX_E3V_K2CANFD: start 23, 1 bit, little-endian, data-type-policy=OVERRIDE, i-signal-type=PRIMITIVE, init-value=0, base-type=BT_ZV_Heckeinzelentriegelung, compu {1=Cx1_Heckdeckeleinzelentriegelung (CM_ZV_Heckeinzelentriegelung_Cx1_Heckdeckeleinzelentriegelung)}, range raw 1, transfer-property=TRIGGERED-ON-CHANGE-WITHOUT-REPETITION, to SAM(timeout 2 s)  # Heckdeckeleinzelentriegelung
          signal ZV_FT_offen_XIX_ZV_02_XIX_E3V_K2CANFD: start 24, 1 bit, little-endian, data-type-policy=OVERRIDE, i-signal-type=PRIMITIVE, init-value=0, base-type=BT_ZV_FT_offen, compu {0=Cx0_FT_geschlossen (CM_ZV_FT_offen_Cx0_FT_geschlossen), 1=Cx1_FT_geoeffnet (CM_ZV_FT_offen_Cx1_FT_geoeffnet)}, range raw 0..1, transfer-property=TRIGGERED-ON-CHANGE-WITHOUT-REPETITION, to SAM(timeout 2 s)  # gespiegeltes Bit FT_Tuer_geoeffnet TSG_FT_1 Botschaft
          signal ZV_BT_offen_XIX_ZV_02_XIX_E3V_K2CANFD: start 25, 1 bit, little-endian, data-type-policy=OVERRIDE, i-signal-type=PRIMITIVE, init-value=0, base-type=BT_ZV_BT_offen, compu {0=Cx0_BT_geschlossen (CM_ZV_BT_offen_Cx0_BT_geschlossen), 1=Cx1_BT_geoeffnet (CM_ZV_BT_offen_Cx1_BT_geoeffnet)}, range raw 0..1, transfer-property=TRIGGERED-ON-CHANGE-WITHOUT-REPETITION, to SAM(timeout 2 s)  # gespiegeltes Bit BT_Tuer_geoeffnet TSG_BT_1 Botschaft
          signal ZV_HFS_offen_XIX_ZV_02_XIX_E3V_K2CANFD: start 26, 1 bit, little-endian, data-type-policy=OVERRIDE, i-signal-type=PRIMITIVE, init-value=0, base-type=BT_ZV_HFS_offen, compu {0=Cx0_geschlossen (CM_ZV_HFS_offen_Cx0_geschlossen), 1=Cx1_offen (CM_ZV_HFS_offen_Cx1_offen)}, range raw 0..1, transfer-property=TRIGGERED-ON-CHANGE-WITHOUT-REPETITION, to SAM(timeout 2 s)  # gespiegeltes Bit HFS_Tuer_geoeffnet TSG_HFS_1 Botschaft
          signal ZV_HBFS_offen_XIX_ZV_02_XIX_E3V_K2CANFD: start 27, 1 bit, little-endian, data-type-policy=OVERRIDE, i-signal-type=PRIMITIVE, init-value=0, base-type=BT_ZV_HBFS_offen, compu {0=Cx0_geschlossen (CM_ZV_HBFS_offen_Cx0_geschlossen), 1=Cx1_offen (CM_ZV_HBFS_offen_Cx1_offen)}, range raw 0..1, transfer-property=TRIGGERED-ON-CHANGE-WITHOUT-REPETITION, to SAM(timeout 2 s)  # gespiegeltes Bit HBFS_Tuer_geoeffnet TSG_HBFS_1 Botschaft
          signal ZV_HD_offen_XIX_ZV_02_XIX_E3V_K2CANFD: start 28, 1 bit, little-endian, data-type-policy=OVERRIDE, i-signal-type=PRIMITIVE, init-value=0, base-type=BT_ZV_HD_offen, compu {1=Cx1_Heckdeckel_auf (CM_ZV_HD_offen_Cx1_Heckdeckel_auf)}, range raw 1, transfer-property=TRIGGERED-ON-CHANGE-WITHOUT-REPETITION, to SAM(timeout 2 s)  # Status Heckdeckel
          signal ZV_HS_offen_XIX_ZV_02_XIX_E3V_K2CANFD: start 29, 1 bit, little-endian, data-type-policy=OVERRIDE, i-signal-type=PRIMITIVE, init-value=0, base-type=BT_ZV_HS_offen, compu {0=Cx0_Heckscheibe_geschlossen (CM_ZV_HS_offen_Cx0_Heckscheibe_geschlossen), 1=Cx1_Heckscheibe_auf (CM_ZV_HS_offen_Cx1_Heckscheibe_auf) (Heckscheibe auf)}, range raw 0..1, transfer-property=TRIGGERED-ON-CHANGE-WITHOUT-REPETITION  # Status Heckscheibe
          signal IRUE_aktiv_XIX_ZV_02_XIX_E3V_K2CANFD: start 30, 1 bit, little-endian, data-type-policy=OVERRIDE, i-signal-type=PRIMITIVE, init-value=0, base-type=BT_IRUE_aktiv, compu {0=Cx0_unscharf (CM_IRUE_aktiv_Cx0_unscharf), 1=Cx1_scharf (CM_IRUE_aktiv_Cx1_scharf)}, range raw 0..1, transfer-property=TRIGGERED-ON-CHANGE-WITHOUT-REPETITION  # Status Innenraumüberwachung
          signal DWA_aktiv_XIX_ZV_02_XIX_E3V_K2CANFD: start 31, 1 bit, little-endian, data-type-policy=OVERRIDE, i-signal-type=PRIMITIVE, init-value=0, base-type=BT_DWA_aktiv, compu {0=Cx0_unscharf (CM_DWA_aktiv_Cx0_unscharf), 1=Cx1_scharf (CM_DWA_aktiv_Cx1_scharf)}, range raw 0..1, transfer-property=TRIGGERED-ON-CHANGE-WITHOUT-REPETITION  # Status DWA aktiv
          signal FFB_HDF_Taste_XIX_ZV_02_XIX_E3V_K2CANFD: start 34, 1 bit, little-endian, data-type-policy=OVERRIDE, i-signal-type=PRIMITIVE, init-value=0, base-type=BT_FFB_HDF_Taste, compu {0=Cx0_Taste_nicht_betaetigt (CM_FFB_HDF_Taste_Cx0_Taste_nicht_betaetigt), 1=Cx1_HDF_Taste_am_Funkschluessel_betaetigt (CM_FFB_HDF_Taste_Cx1_HDF_Taste_am_Funkschluessel_betaetigt)}, range raw 0..1, transfer-property=PENDING, to SAM(timeout 2 s)  # HDF Taste am Funkschluessel
          signal FFB_Panik_Taste_XIX_ZV_02_XIX_E3V_K2CANFD: start 35, 1 bit, little-endian, data-type-policy=OVERRIDE, i-signal-type=PRIMITIVE, init-value=0, base-type=BT_FFB_Panik_Taste, compu {0=Cx0_Taste_nicht_betaetigt (CM_FFB_Panik_Taste_Cx0_Taste_nicht_betaetigt), 1=Cx1_Panik_Taste_am_Funkschluessel_betaetigt (CM_FFB_Panik_Taste_Cx1_Panik_Taste_am_Funkschluessel_betaetigt)}, range raw 0..1, transfer-property=PENDING  # Panik Taste Funkschluessel
          signal FFB_Auf_Taste_XIX_ZV_02_XIX_E3V_K2CANFD: start 36, 1 bit, little-endian, data-type-policy=OVERRIDE, i-signal-type=PRIMITIVE, init-value=0, base-type=BT_FFB_Auf_Taste, compu {0=Cx0_Taste_nicht_betaetigt (CM_FFB_Auf_Taste_Cx0_Taste_nicht_betaetigt), 1=Cx1_Oeffnentaste_betaetigt (CM_FFB_Auf_Taste_Cx1_Oeffnentaste_betaetigt)}, range raw 0..1, transfer-property=PENDING  # Auf-Taste Funkschluessel
          signal FFB_Zu_Taste_XIX_ZV_02_XIX_E3V_K2CANFD: start 37, 1 bit, little-endian, data-type-policy=OVERRIDE, i-signal-type=PRIMITIVE, init-value=0, base-type=BT_FFB_Zu_Taste, compu {0=Cx0_Taste_nicht_betaetigt (CM_FFB_Zu_Taste_Cx0_Taste_nicht_betaetigt), 1=Cx1_Zu_Taste_am_Funkschluessel_betaetigt (CM_FFB_Zu_Taste_Cx1_Zu_Taste_am_Funkschluessel_betaetigt)}, range raw 0..1, transfer-property=PENDING  # Zu-Taste Funkschluessel
          signal FFB_CarFinder_XIX_ZV_02_XIX_E3V_K2CANFD: start 38, 1 bit, little-endian, data-type-policy=OVERRIDE, i-signal-type=PRIMITIVE, init-value=0, base-type=BT_FFB_CarFinder, compu {0=Cx0_nicht_aktiv (CM_FFB_CarFinder_Cx0_nicht_aktiv) (nicht aktiv), 1=Cx1_aktiv (CM_FFB_CarFinder_Cx1_aktiv)}, range raw 0..1, transfer-property=PENDING  # Car Finder Funktion (Blinken ohne zu entriegeln)
          signal FFB_Komfortoeffnen_XIX_ZV_02_XIX_E3V_K2CANFD: start 39, 1 bit, little-endian, data-type-policy=OVERRIDE, i-signal-type=PRIMITIVE, init-value=0, base-type=BT_FFB_Komfortoeffnen, compu {0=Cx0_kein_Komfortoeffnen_empfangen (CM_FFB_Komfortoeffnen_Cx0_kein_Komfortoeffnen_empfangen), 1=Cx1_Komfortoeffnen_ueber_Funk_empfangen (CM_FFB_Komfortoeffnen_Cx1_Komfortoeffnen_ueber_Funk_empfangen) (Komfortoeffnen ueber Funk empfangen)}, range raw 0..1, transfer-property=PENDING  # Komfortoeffnen Funk
          signal FFB_Komfortschliessen_XIX_ZV_02_XIX_E3V_K2CANFD: start 40, 1 bit, little-endian, data-type-policy=OVERRIDE, i-signal-type=PRIMITIVE, init-value=0, base-type=BT_FFB_Komfortschliessen, compu {0=Cx0_kein_Komfortschliessen_empfangen (CM_FFB_Komfortschliessen_Cx0_kein_Komfortschliessen_empfangen), 1=Cx1_Komfortschliessen_ueber_Funk_empfangen (CM_FFB_Komfortschliessen_Cx1_Komfortschliessen_ueber_Funk_empfangen) (Komfortschliessen ueber Funk empfangen)}, range raw 0..1, transfer-property=PENDING  # Komfortschliessen Funk
          signal FBS_IDG_in_Reichweite_XIX_ZV_02_XIX_E3V_K2CANFD: start 41, 1 bit, little-endian, data-type-policy=OVERRIDE, i-signal-type=PRIMITIVE, init-value=0, base-type=BT_FBS_IDG_in_Reichweite, compu {0=Cx0_ausser_Reichweite_bzw_nicht_ermittelbar (CM_FBS_IDG_in_Reichweite_Cx0_ausser_Reichweite_bzw_nicht_ermittelbar), 1=Cx1_innerhalb_Reichweite (CM_FBS_IDG_in_Reichweite_Cx1_innerhalb_Reichweite)}, range raw 0..1, transfer-property=PENDING  # Für elektrisch betätigte Türen und Klappen muss für eine Betätigung über Funk eine Reichweitenbegrenzung eingeführt werden. Diese Bit zeigt an, dass sich der Funkschlüssel innerhalb der geforderten Reichweite befindet
          signal ZV_Schluessel_Zugang_XIX_ZV_02_XIX_E3V_K2CANFD: start 42, 4 bit, little-endian, data-type-policy=OVERRIDE, i-signal-type=PRIMITIVE, init-value=0, base-type=BT_ZV_Schluessel_Zugang, compu {0=Cx0_kein_auth_Schluessel_erkannt (CM_ZV_Schluessel_Zugang_Cx0_kein_auth_Schluessel_erkannt), 1=Cx1_aktive_Funkschluessel_Nr_01 (CM_ZV_Schluessel_Zugang_Cx1_aktive_Funkschluessel_Nr_01), 2=Cx2_aktive_Funkschluessel_Nr_02 (CM_ZV_Schluessel_Zugang_Cx2_aktive_Funkschluessel_Nr_02), 3=Cx3_aktive_Funkschluessel_Nr_03 (CM_ZV_Schluessel_Zugang_Cx3_aktive_Funkschluessel_Nr_03), 4=Cx4_aktive_Funkschluessel_Nr_04 (CM_ZV_Schluessel_Zugang_Cx4_aktive_Funkschluessel_Nr_04), 5=Cx5_aktive_Funkschluessel_Nr_05 (CM_ZV_Schluessel_Zugang_Cx5_aktive_Funkschluessel_Nr_05), 6=Cx6_aktive_Funkschluessel_Nr_06 (CM_ZV_Schluessel_Zugang_Cx6_aktive_Funkschluessel_Nr_06), 7=Cx7_aktive_Funkschluessel_Nr_07 (CM_ZV_Schluessel_Zugang_Cx7_aktive_Funkschluessel_Nr_07), 8=Cx8_aktive_Funkschluessel_Nr_08 (CM_ZV_Schluessel_Zugang_Cx8_aktive_Funkschluessel_Nr_08), 9=Cx9_aktive_SmartDevice_Nr_09 (CM_ZV_Schluessel_Zugang_Cx9_aktive_SmartDevice_Nr_09), 10=Cxa_ungueltig_10 (CM_ZV_Schluessel_Zugang_Cxa_ungueltig_10), 11=Cxb_ungueltig_11 (CM_ZV_Schluessel_Zugang_Cxb_ungueltig_11), 12=Cxc_ungueltig_12 (CM_ZV_Schluessel_Zugang_Cxc_ungueltig_12), 13=Cxd_ungueltig_13 (CM_ZV_Schluessel_Zugang_Cxd_ungueltig_13), 14=Cxe_ungueltig_14 (CM_ZV_Schluessel_Zugang_Cxe_ungueltig_14), 15=Cxf_ungueltig_15 (CM_ZV_Schluessel_Zugang_Cxf_ungueltig_15)}, range raw 0..15, transfer-property=TRIGGERED-ON-CHANGE-WITHOUT-REPETITION, to SAM(timeout 2 s)  # aktuelle Funkschlüsselnummer
          signal ZV_SafeFunktion_aktiv_XIX_ZV_02_XIX_E3V_K2CANFD: start 46, 1 bit, little-endian, data-type-policy=OVERRIDE, i-signal-type=PRIMITIVE, init-value=0, base-type=BT_ZV_SafeFunktion_aktiv, compu {0=Cx0_inaktiv (CM_ZV_SafeFunktion_aktiv_Cx0_inaktiv), 1=Cx1_aktiv (CM_ZV_SafeFunktion_aktiv_Cx1_aktiv)}, range raw 0..1, transfer-property=TRIGGERED-ON-CHANGE-WITHOUT-REPETITION  # Statusübermittlung ob die Safe Funktion im Fzg. aktiv ist. Das Kombi benötigt das Signal, um den Text Safelock aktiv anzuzeigen.
          signal FBS_Warn_Schluessel_Batt_XIX_ZV_02_XIX_E3V_K2CANFD: start 47, 1 bit, little-endian, data-type-policy=OVERRIDE, i-signal-type=PRIMITIVE, init-value=0, base-type=BT_FBS_Warn_Schluessel_Batt, compu {0=Cx0_i_O (CM_FBS_Warn_Schluessel_Batt_Cx0_i_O) (i.O.), 1=Cx1_defekt (CM_FBS_Warn_Schluessel_Batt_Cx1_defekt)}, range raw 0..1, transfer-property=TRIGGERED-ON-CHANGE-WITHOUT-REPETITION  # Kombi Prio Warnung Schluessel Batterie "Bitte Schlüsselbatterie wechseln!"
          signal ZV_Oeffnungsmodus_XIX_ZV_02_XIX_E3V_K2CANFD: start 48, 2 bit, little-endian, data-type-policy=OVERRIDE, i-signal-type=PRIMITIVE, init-value=0, base-type=BT_ZV_Oeffnungsmodus, compu {0=Cx0_globale_Oeffnung (CM_ZV_Oeffnungsmodus_Cx0_globale_Oeffnung), 1=Cx1_ZV_mit_Einzeltuerentr (CM_ZV_Oeffnungsmodus_Cx1_ZV_mit_Einzeltuerentr), 2=Cx2_ZV_individuell_selektiv (CM_ZV_Oeffnungsmodus_Cx2_ZV_individuell_selektiv), 3=Cx3_ZV_seitenselektiv (CM_ZV_Oeffnungsmodus_Cx3_ZV_seitenselektiv)}, range raw 0..3, transfer-property=TRIGGERED-ON-CHANGE-WITHOUT-REPETITION  # Konfigurierter Oeffnungsmodus fuer ZV: 0 = globale Oeffnung (alle Tueren) 1 = ZV mit Einzeltuerentriegelung (FFB - nur Fahrertuer, Kessy - nur bediente Tuer) 2 = ZV individuell selektive Oeffnung (FFB - Fahrerseite, Kessy - bediente Tuer + Fahrertuer) 3 = ZV seitenselektive Oeffnung
          signal ZV_ist_Zustand_verfuegbar_XIX_ZV_02_XIX_E3V_K2CANFD: start 54, 1 bit, little-endian, data-type-policy=OVERRIDE, i-signal-type=PRIMITIVE, init-value=0, base-type=BT_ZV_ist_Zustand_verfuegbar, compu {0=Cx0_nicht_verfuegbar (CM_ZV_ist_Zustand_verfuegbar_Cx0_nicht_verfuegbar), 1=Cx1_verfuegbar_alle_TSGs_am_Bus (CM_ZV_ist_Zustand_verfuegbar_Cx1_verfuegbar_alle_TSGs_am_Bus)}, range raw 0..1, transfer-property=TRIGGERED-ON-CHANGE-WITHOUT-REPETITION, to SAM(timeout 2 s)  # Verfügbarkeit IST-Zustand ZV
          signal IRUE_Taster_Fkts_LED_XIX_ZV_02_XIX_E3V_K2CANFD: start 55, 1 bit, little-endian, data-type-policy=OVERRIDE, i-signal-type=PRIMITIVE, init-value=0, base-type=BT_IRUE_Taster_Fkts_LED, compu {0=Cx0_LED_aus (CM_IRUE_Taster_Fkts_LED_Cx0_LED_aus), 1=Cx1_LED_ein (CM_IRUE_Taster_Fkts_LED_Cx1_LED_ein)}, range raw 0..1, transfer-property=TRIGGERED-ON-CHANGE-WITHOUT-REPETITION  # Anforderung Funktions-LED IRUE-Taster (LED wird vom TSG angesteuert) MQB: Bei Verbau eines einzelnen Taster zur Deaktivierung von IRUE und NGS wird dieses Signal zur Ansteuerung der Funktions-LED gesendet.
          signal ZV_Tankklappe_offen_XIX_ZV_02_XIX_E3V_K2CANFD: start 56, 1 bit, little-endian, data-type-policy=OVERRIDE, i-signal-type=PRIMITIVE, init-value=0, base-type=BT_ZV_Tankklappe_offen, compu {0=Cx0_Tankklappe_geschlossen (CM_ZV_Tankklappe_offen_Cx0_Tankklappe_geschlossen), 1=Cx1_Tankklappe_offen (CM_ZV_Tankklappe_offen_Cx1_Tankklappe_offen)}, range raw 0..1, transfer-property=PENDING  # Öffnungsstatus der Tankklappe
          signal ZV_Rollo_auf_XIX_ZV_02_XIX_E3V_K2CANFD: start 57, 1 bit, little-endian, data-type-policy=OVERRIDE, i-signal-type=PRIMITIVE, init-value=0, base-type=BT_ZV_Rollo_auf, compu {0=Cx0_inaktiv (CM_ZV_Rollo_auf_Cx0_inaktiv), 1=Cx1_aktiv (CM_ZV_Rollo_auf_Cx1_aktiv)}, range raw 0..1, transfer-property=TRIGGERED-ON-CHANGE-WITHOUT-REPETITION  # Komfortöffnen des Dachrollos
          signal ZV_Rollo_zu_XIX_ZV_02_XIX_E3V_K2CANFD: start 58, 1 bit, little-endian, data-type-policy=OVERRIDE, i-signal-type=PRIMITIVE, init-value=0, base-type=BT_ZV_Rollo_zu, compu {0=Cx0_inaktiv (CM_ZV_Rollo_zu_Cx0_inaktiv), 1=Cx1_aktiv (CM_ZV_Rollo_zu_Cx1_aktiv)}, range raw 0..1, transfer-property=TRIGGERED-ON-CHANGE-WITHOUT-REPETITION  # Komfortschließen des Dachrollos
          signal ZV_SAD_auf_XIX_ZV_02_XIX_E3V_K2CANFD: start 59, 1 bit, little-endian, data-type-policy=OVERRIDE, i-signal-type=PRIMITIVE, init-value=0, base-type=BT_ZV_SAD_auf, compu {0=Cx0_inaktiv (CM_ZV_SAD_auf_Cx0_inaktiv), 1=Cx1_aktiv (CM_ZV_SAD_auf_Cx1_aktiv)}, range raw 0..1, transfer-property=TRIGGERED-ON-CHANGE-WITHOUT-REPETITION  # Komfortöffnen des Schiebeausstelldaches
          signal ZV_SAD_zu_XIX_ZV_02_XIX_E3V_K2CANFD: start 60, 1 bit, little-endian, data-type-policy=OVERRIDE, i-signal-type=PRIMITIVE, init-value=0, base-type=BT_ZV_SAD_zu, compu {0=Cx0_inaktiv (CM_ZV_SAD_zu_Cx0_inaktiv), 1=Cx1_aktiv (CM_ZV_SAD_zu_Cx1_aktiv)}, range raw 0..1, transfer-property=TRIGGERED-ON-CHANGE-WITHOUT-REPETITION  # Komfortschließen des Schiebeausstelldaches
          signal ZV_verriegelt_soll_XIX_ZV_02_XIX_E3V_K2CANFD: start 62, 2 bit, little-endian, data-type-policy=OVERRIDE, i-signal-type=PRIMITIVE, init-value=0, base-type=BT_ZV_verriegelt_soll, compu {0=Cx0_Init (CM_ZV_verriegelt_soll_Cx0_Init), 1=Cx1_nicht_verriegelt (CM_ZV_verriegelt_soll_Cx1_nicht_verriegelt), 2=Cx2_verriegelt (CM_ZV_verriegelt_soll_Cx2_verriegelt)}, range raw 0..2, transfer-property=TRIGGERED-ON-CHANGE-WITHOUT-REPETITION  # Fahrzeug Gesamtverriegelungsstatus Sollzustand für Ladestecker- und Ladeklappenverriegelung.
      frame ZV_04_XIX_E3V_K2CANFD: id 0x2C4, to SAM, frame-length=8, can-addressing-mode=STANDARD, can-frame-rx-behavior=CAN-FD, can-frame-tx-behavior=CAN-FD
        pdu ZV_04_XIX_E3V_K2CANFD_E2E: length=8, minimum-delay=0.01, transmission-mode-true-timing=event-controlled-timing={number-of-repetitions=0, repetition-period=0.0}, unused-bit-pattern=0  # Fuer die Botschaft ist das Cyclic-Timing 0.5 zu verwenden.
          transmission-mode-conditions:
            {data-filter={data-filter-type=MASKED-NEW-DIFFERS-X, mask=1, x=0}, i-signal-in-i-pdu=ZV_Crashfall_erkannt}
            {data-filter={data-filter-type=MASKED-NEW-DIFFERS-X, mask=1, x=0}, i-signal-in-i-pdu=ZV_HW_Motor_Safe_Hinten}
            {data-filter={data-filter-type=MASKED-NEW-DIFFERS-X, mask=1, x=0}, i-signal-in-i-pdu=ZV_HW_Motor_Lock_HK}
          signal ZV_04_CRC_XIX_ZV_04_XIX_E3V_K2CANFD: start 0, 8 bit, little-endian, data-type-policy=OVERRIDE, i-signal-type=PRIMITIVE, base-type=BT_ZV_04_CRC, compu {phys=raw for raw 0..255}, range phys 0..255, raw 0..255, to SAM(timeout 5 s)  # Für MLB: Berechnung siehe Lastenheft "Kommunikationsabsicherung für FlexRay und CAN" Ab MQB und MLBevo: Berechnung siehe Lastenheft "End-to-End Kommunikationsabsicherung" Endwerte siehe Begleitdokument "S-PDU Kennungsfolgen"
          signal ZV_04_BZ_XIX_ZV_04_XIX_E3V_K2CANFD: start 8, 4 bit, little-endian, data-type-policy=OVERRIDE, i-signal-type=PRIMITIVE, base-type=BT_ZV_04_BZ, compu {phys=raw for raw 0..15}, range phys 0..15, raw 0..15, to SAM(timeout 5 s)  # 4bit Botschaftszähler, wird mit jeder Sendebotschaft inkrementiert
          signal ZV_HFS_Status_KiSi_XIX_ZV_04_XIX_E3V_K2CANFD: start 12, 1 bit, little-endian, data-type-policy=OVERRIDE, i-signal-type=PRIMITIVE, init-value=0, base-type=BT_ZV_HFS_Status_KiSi, compu {0=Cx0_inaktiv (CM_ZV_HFS_Status_KiSi_Cx0_inaktiv), 1=Cx1_aktiv (CM_ZV_HFS_Status_KiSi_Cx1_aktiv)}, range raw 0..1  # Status der Kindersicherung: aktiv-inaktiv hinten Fahrerseite
          signal ZV_HFS_TAG_betaetigt_XIX_ZV_04_XIX_E3V_K2CANFD: start 13, 1 bit, little-endian, data-type-policy=OVERRIDE, i-signal-type=PRIMITIVE, init-value=0, base-type=BT_ZV_HFS_TAG_betaetigt, compu {0=Cx0_nicht_betaetigt (CM_ZV_HFS_TAG_betaetigt_Cx0_nicht_betaetigt), 1=Cx1_betaetigt (CM_ZV_HFS_TAG_betaetigt_Cx1_betaetigt)}, range raw 0..1  # Status des Türaußengriffs, betatigt-nicht betaetigt hinten Fahrerseite
          signal ZV_HFS_TIG_oeffnen_betaetigt_XIX_ZV_04_XIX_E3V_K2CANFD: start 14, 1 bit, little-endian, data-type-policy=OVERRIDE, i-signal-type=PRIMITIVE, init-value=0, base-type=BT_ZV_HFS_TIG_oeffnen_betaetigt, compu {0=Cx0_nicht_betaetigt (CM_ZV_HFS_TIG_oeffnen_betaetigt_Cx0_nicht_betaetigt), 1=Cx1_betaetigt (CM_ZV_HFS_TIG_oeffnen_betaetigt_Cx1_betaetigt)}, range raw 0..1  # Status des Türinnengriffs_oeffnen, betaetigt-nicht betaetigt hinten Fahrerseite
          signal ZV_HFS_TIG_schliessen_betaetigt_XIX_ZV_04_XIX_E3V_K2CANFD: start 15, 1 bit, little-endian, data-type-policy=OVERRIDE, i-signal-type=PRIMITIVE, init-value=0, base-type=BT_ZV_HFS_TIG_schliessen_betaetigt, compu {0=Cx0_nicht_betaetigt (CM_ZV_HFS_TIG_schliessen_betaetigt_Cx0_nicht_betaetigt), 1=Cx1_betaetigt (CM_ZV_HFS_TIG_schliessen_betaetigt_Cx1_betaetigt)}, range raw 0..1  # Status des Türinnengriffs_schliessen, betaetigt-nicht betaetigt hinten Fahrerseite
          signal ZV_HBFS_Status_KiSi_XIX_ZV_04_XIX_E3V_K2CANFD: start 16, 1 bit, little-endian, data-type-policy=OVERRIDE, i-signal-type=PRIMITIVE, init-value=0, base-type=BT_ZV_HBFS_Status_KiSi, compu {0=Cx0_inaktiv (CM_ZV_HBFS_Status_KiSi_Cx0_inaktiv), 1=Cx1_aktiv (CM_ZV_HBFS_Status_KiSi_Cx1_aktiv)}, range raw 0..1  # Status der Kindersicherung: aktiv-inaktiv hinten Beifahrerseite
          signal ZV_HBFS_TAG_betaetigt_XIX_ZV_04_XIX_E3V_K2CANFD: start 17, 1 bit, little-endian, data-type-policy=OVERRIDE, i-signal-type=PRIMITIVE, init-value=0, base-type=BT_ZV_HBFS_TAG_betaetigt, compu {0=Cx0_nicht_betaetigt (CM_ZV_HBFS_TAG_betaetigt_Cx0_nicht_betaetigt), 1=Cx1_betaetigt (CM_ZV_HBFS_TAG_betaetigt_Cx1_betaetigt)}, range raw 0..1  # Status des Türaußengriffs, betatigt-nicht betaetigt hinten Beifahrerseite
          signal ZV_HBFS_TIG_oeffnen_betaetigt_XIX_ZV_04_XIX_E3V_K2CANFD: start 18, 1 bit, little-endian, data-type-policy=OVERRIDE, i-signal-type=PRIMITIVE, init-value=0, base-type=BT_ZV_HBFS_TIG_oeffnen_betaetigt, compu {0=Cx0_nicht_betaetigt (CM_ZV_HBFS_TIG_oeffnen_betaetigt_Cx0_nicht_betaetigt), 1=Cx1_betaetigt (CM_ZV_HBFS_TIG_oeffnen_betaetigt_Cx1_betaetigt)}, range raw 0..1  # Status des Türinnengriffs_oeffnen, betaetigt-nicht betaetigt hinten Beifahrerseite
          signal ZV_HBFS_TIG_schliessen_betaetigt_XIX_ZV_04_XIX_E3V_K2CANFD: start 19, 1 bit, little-endian, data-type-policy=OVERRIDE, i-signal-type=PRIMITIVE, init-value=0, base-type=BT_ZV_HBFS_TIG_schliessen_betaetigt, compu {0=Cx0_nicht_betaetigt (CM_ZV_HBFS_TIG_schliessen_betaetigt_Cx0_nicht_betaetigt), 1=Cx1_betaetigt (CM_ZV_HBFS_TIG_schliessen_betaetigt_Cx1_betaetigt)}, range raw 0..1  # Status des Türinnengriffs_schliessen, betaetigt-nicht betaetigt hinten Beifahrerseite
          signal ZV_TAG_FT_verfahren_XIX_ZV_04_XIX_E3V_K2CANFD: start 20, 2 bit, little-endian, data-type-policy=OVERRIDE, i-signal-type=PRIMITIVE, init-value=0, base-type=BT_ZV_TAG_FT_verfahren, invalid-value=Invalid_ZV_TAG_FT_verfahren_XIX_ZV_04_XIX_E3V_K2CANFD:3, compu {0=Cx0_Init (CM_ZV_TAG_FT_verfahren_Cx0_Init), 1=Cx1_TAG_ausfahren (CM_ZV_TAG_FT_verfahren_Cx1_TAG_ausfahren), 2=Cx2_TAG_einfahren (CM_ZV_TAG_FT_verfahren_Cx2_TAG_einfahren), 3=Cx3_Fehler (CM_ZV_TAG_FT_verfahren_Cx3_Fehler)}, range raw 0..3  # Türaussengriff FT Trigger zum Aus- und Einfahren
          signal ZV_TAG_BT_verfahren_XIX_ZV_04_XIX_E3V_K2CANFD: start 22, 2 bit, little-endian, data-type-policy=OVERRIDE, i-signal-type=PRIMITIVE, init-value=0, base-type=BT_ZV_TAG_BT_verfahren, compu {0=Cx0_Init (CM_ZV_TAG_BT_verfahren_Cx0_Init), 1=Cx1_TAG_ausfahren (CM_ZV_TAG_BT_verfahren_Cx1_TAG_ausfahren), 2=Cx2_TAG_einfahren (CM_ZV_TAG_BT_verfahren_Cx2_TAG_einfahren)}, range raw 0..2  # Türaussengriff BT Trigger zum Aus- und Einfahren
          signal ZV_TAG_HFS_verfahren_XIX_ZV_04_XIX_E3V_K2CANFD: start 24, 2 bit, little-endian, data-type-policy=OVERRIDE, i-signal-type=PRIMITIVE, init-value=0, base-type=BT_ZV_TAG_HFS_verfahren, compu {0=Cx0_Init (CM_ZV_TAG_HFS_verfahren_Cx0_Init), 1=Cx1_TAG_ausfahren (CM_ZV_TAG_HFS_verfahren_Cx1_TAG_ausfahren), 2=Cx2_TAG_einfahren (CM_ZV_TAG_HFS_verfahren_Cx2_TAG_einfahren)}, range raw 0..2  # Türaussengriff HFS Trigger zum Aus- und Einfahren
          signal ZV_TAG_HBFS_verfahren_XIX_ZV_04_XIX_E3V_K2CANFD: start 26, 2 bit, little-endian, data-type-policy=OVERRIDE, i-signal-type=PRIMITIVE, init-value=0, base-type=BT_ZV_TAG_HBFS_verfahren, compu {0=Cx0_Init (CM_ZV_TAG_HBFS_verfahren_Cx0_Init), 1=Cx1_TAG_ausfahren (CM_ZV_TAG_HBFS_verfahren_Cx1_TAG_ausfahren), 2=Cx2_TAG_einfahren (CM_ZV_TAG_HBFS_verfahren_Cx2_TAG_einfahren)}, range raw 0..2  # Türaussengriff HBFS Trigger zum Aus- und Einfahren
          signal ISignalVoid_ZV_04_XIX_E3V_K2CANFD_0: start 28, 4 bit, little-endian, system signal SignalVoid_ZV_04_0, data-type-policy=OVERRIDE, i-signal-type=PRIMITIVE, base-type=BT_SignalVoid
          signal ISignalVoid_ZV_04_XIX_E3V_K2CANFD_1: start 32, 8 bit, little-endian, system signal SignalVoid_ZV_04_1, data-type-policy=OVERRIDE, i-signal-type=PRIMITIVE, base-type=BT_SignalVoid
          signal ZV_Crashfall_erkannt_XIX_ZV_04_XIX_E3V_K2CANFD: start 40, 1 bit, little-endian, data-type-policy=OVERRIDE, i-signal-type=PRIMITIVE, init-value=0, base-type=BT_ZV_Crashfall_erkannt, compu {0=Cx0_kein_Crashfall_erkannt (CM_ZV_Crashfall_erkannt_Cx0_kein_Crashfall_erkannt), 1=Cx1_Crashfall_erkannt (CM_ZV_Crashfall_erkannt_Cx1_Crashfall_erkannt)}, range raw 0..1
          signal ZV_Hupe_Takt_XIX_ZV_04_XIX_E3V_K2CANFD: start 41, 1 bit, little-endian, data-type-policy=OVERRIDE, i-signal-type=PRIMITIVE, init-value=0, base-type=BT_ZV_Hupe_Takt, compu {0=Cx0_Horn_aus (CM_ZV_Hupe_Takt_Cx0_Horn_aus), 1=Cx1_Horn_an (CM_ZV_Hupe_Takt_Cx1_Horn_an)}, range raw 0..1, to SAM(timeout 5 s)  # Takt für die Ansteuerung des Signalhorns über SWC-ZV
          signal ZV_Hupe_Anf_XIX_ZV_04_XIX_E3V_K2CANFD: start 42, 1 bit, little-endian, data-type-policy=OVERRIDE, i-signal-type=PRIMITIVE, init-value=0, base-type=BT_ZV_Hupe_Anf, compu {0=Cx0_Keine_Anforderung (CM_ZV_Hupe_Anf_Cx0_Keine_Anforderung), 1=Cx1_Anforderung (CM_ZV_Hupe_Anf_Cx1_Anforderung)}, range raw 0..1, to SAM(timeout 5 s)  # Anforderung zur Ansteuerung des Signalhorns (statisches Signal) durch die ZV
          signal ZV_Status_Cargolock_XIX_ZV_04_XIX_E3V_K2CANFD: start 43, 1 bit, little-endian, data-type-policy=OVERRIDE, i-signal-type=PRIMITIVE, init-value=0, base-type=BT_ZV_Status_Cargolock, compu {0=Cx0_nicht_aktiv (CM_ZV_Status_Cargolock_Cx0_nicht_aktiv), 1=Cx1_aktiv (CM_ZV_Status_Cargolock_Cx1_aktiv)}, range raw 0..1, to SAM(timeout 5 s)  # Status der CargoLock-Funktion
          signal ZV_verriegelt_extern_soll_03_XIX_ZV_04_XIX_E3V_K2CANFD: start 44, 2 bit, little-endian, data-type-policy=OVERRIDE, i-signal-type=PRIMITIVE, init-value=0, base-type=BT_ZV_verriegelt_extern_soll_03, invalid-value=Invalid_ZV_verriegelt_extern_soll_03_XIX_ZV_04_XIX_E3V_K2CANFD:3, compu {0=Cx0_Fahrzeug_nicht_extern_verriegelt (CM_ZV_verriegelt_extern_soll_03_Cx0_Fahrzeug_nicht_extern_verriegelt), 1=Cx1_Fahrzeug_extern_verriegelt_Sollz (CM_ZV_verriegelt_extern_soll_03_Cx1_Fahrzeug_extern_verriegelt_Sollz), 2=Cx2_Init (CM_ZV_verriegelt_extern_soll_03_Cx2_Init), 3=Cx3_Fehler (CM_ZV_verriegelt_extern_soll_03_Cx3_Fehler)}, range raw 0..3  # Sollzustand: Verriegelung Fahrzeug aussen
          signal ZV_HW_TKL_mot_verr_XIX_ZV_04_XIX_E3V_K2CANFD: start 46, 1 bit, little-endian, data-type-policy=OVERRIDE, i-signal-type=PRIMITIVE, init-value=0, base-type=BT_ZV_HW_TKL_mot_verr, compu {0=Cx0_nicht_aktiv (CM_ZV_HW_TKL_mot_verr_Cx0_nicht_aktiv), 1=Cx1_aktiv (CM_ZV_HW_TKL_mot_verr_Cx1_aktiv)}, range raw 0..1  # Ansteuerung des Tankklappenmotors für die Verriegelung
          signal ZV_HW_TKL_mot_entr_XIX_ZV_04_XIX_E3V_K2CANFD: start 47, 1 bit, little-endian, data-type-policy=OVERRIDE, i-signal-type=PRIMITIVE, init-value=0, base-type=BT_ZV_HW_TKL_mot_entr, compu {0=Cx0_nicht_aktiv (CM_ZV_HW_TKL_mot_entr_Cx0_nicht_aktiv), 1=Cx1_aktiv (CM_ZV_HW_TKL_mot_entr_Cx1_aktiv)}, range raw 0..1  # Ansteuerung des Tankklappenmotors für die Entriegelung
          signal ZV_Status_KiSi_CargoLock_XIX_ZV_04_XIX_E3V_K2CANFD: start 48, 3 bit, little-endian, data-type-policy=OVERRIDE, i-signal-type=PRIMITIVE, init-value=0, base-type=BT_ZV_Status_KiSi_CargoLock, invalid-value=Invalid_ZV_Status_KiSi_CargoLock_XIX_ZV_04_XIX_E3V_K2CANFD:7, compu {0=Cx0_inaktiv (CM_ZV_Status_KiSi_CargoLock_Cx0_inaktiv), 1=Cx1_KiSi_aktiv (CM_ZV_Status_KiSi_CargoLock_Cx1_KiSi_aktiv), 2=Cx2_CargoLock_aktiv (CM_ZV_Status_KiSi_CargoLock_Cx2_CargoLock_aktiv), 3=Cx3_KiSi_gesperrt (CM_ZV_Status_KiSi_CargoLock_Cx3_KiSi_gesperrt), 7=Cx7_Fehler (CM_ZV_Status_KiSi_CargoLock_Cx7_Fehler)}, range raw 0..7  # Status Kindersicherung oder Status des CargoLock (abhängig von der Austattungsvariante)
          signal ZV_HD_Parkbremse_Hinweis_XIX_ZV_04_XIX_E3V_K2CANFD: start 51, 1 bit, little-endian, data-type-policy=OVERRIDE, i-signal-type=PRIMITIVE, init-value=0, base-type=BT_ZV_HD_Parkbremse_Hinweis, compu {0=Cx0_inaktiv (CM_ZV_HD_Parkbremse_Hinweis_Cx0_inaktiv), 1=Cx1_aktiv (CM_ZV_HD_Parkbremse_Hinweis_Cx1_aktiv)}, range raw 0..1  # Infotext NAR für die Vorbedingung "Parkbremse aktiv" für Öffnen der Heckklappe über den Fahrerrauminnentaster.
          signal BCM_Waehlhebel_P_Hinweis_XIX_ZV_04_XIX_E3V_K2CANFD: start 52, 1 bit, little-endian, data-type-policy=OVERRIDE, i-signal-type=PRIMITIVE, init-value=0, base-type=BT_BCM_Waehlhebel_P_Hinweis, compu {0=Cx0_inaktiv (CM_BCM_Waehlhebel_P_Hinweis_Cx0_inaktiv), 1=Cx1_aktiv (CM_BCM_Waehlhebel_P_Hinweis_Cx1_aktiv)}, range raw 0..1  # Infotext NAR für die Vorbedingung "Waehlhebel in P" für Öffnen der Heckklappe über den Fahrerrauminnentaster.
          signal ZV_Laderaumabd_elektr_aktiviert_XIX_ZV_04_XIX_E3V_K2CANFD: start 53, 1 bit, little-endian, data-type-policy=OVERRIDE, i-signal-type=PRIMITIVE, init-value=0, base-type=BT_ZV_Laderaumabd_elektr_aktiviert, compu {0=Cx0_inaktiv (CM_ZV_Laderaumabd_elektr_aktiviert_Cx0_inaktiv), 1=Cx1_aktiv (CM_ZV_Laderaumabd_elektr_aktiviert_Cx1_aktiv)}, range raw 0..1, to SAM(timeout 5 s)  # Komfortöffnen Elektrische Laderaumabdeckung aktiviert
          signal ZV_Einfachhorn_Takt_XIX_ZV_04_XIX_E3V_K2CANFD: start 54, 1 bit, little-endian, data-type-policy=OVERRIDE, i-signal-type=PRIMITIVE, init-value=0, base-type=BT_ZV_Einfachhorn_Takt, compu {0=Cx0_Horn_aus (CM_ZV_Einfachhorn_Takt_Cx0_Horn_aus), 1=Cx1_Horn_an (CM_ZV_Einfachhorn_Takt_Cx1_Horn_an)}, range raw 0..1, to SAM(timeout 5 s)  # Takt für die Ansteuerung des Einfachhorns über SWC-ZV
          signal ZV_Einfachhorn_Anf_XIX_ZV_04_XIX_E3V_K2CANFD: start 55, 1 bit, little-endian, data-type-policy=OVERRIDE, i-signal-type=PRIMITIVE, init-value=0, base-type=BT_ZV_Einfachhorn_Anf, compu {0=Cx0_Keine_Anforderung (CM_ZV_Einfachhorn_Anf_Cx0_Keine_Anforderung), 1=Cx1_Anforderung (CM_ZV_Einfachhorn_Anf_Cx1_Anforderung)}, range raw 0..1, to SAM(timeout 5 s)  # Anforderung zur Ansteuerung der Einfachhorns (statisches Signal) durch die ZV
          signal ZV_DWA_Einfachhorn_Takt_XIX_ZV_04_XIX_E3V_K2CANFD: start 56, 1 bit, little-endian, data-type-policy=OVERRIDE, i-signal-type=PRIMITIVE, init-value=0, base-type=BT_ZV_DWA_Einfachhorn_Takt, compu {0=Cx0_Horn_aus (CM_ZV_DWA_Einfachhorn_Takt_Cx0_Horn_aus), 1=Cx1_Horn_an (CM_ZV_DWA_Einfachhorn_Takt_Cx1_Horn_an)}, range raw 0..1, to SAM(timeout 5 s)  # Takt für die Ansteuerung des Einfachhorns über SWC-QTG
          signal ZV_DWA_Einfachhorn_Anf_XIX_ZV_04_XIX_E3V_K2CANFD: start 57, 1 bit, little-endian, data-type-policy=OVERRIDE, i-signal-type=PRIMITIVE, init-value=0, base-type=BT_ZV_DWA_Einfachhorn_Anf, compu {0=Cx0_Keine_Anforderung (CM_ZV_DWA_Einfachhorn_Anf_Cx0_Keine_Anforderung), 1=Cx1_Anforderung (CM_ZV_DWA_Einfachhorn_Anf_Cx1_Anforderung)}, range raw 0..1, to SAM(timeout 5 s)  # Anforderung zur Ansteuerung der Einfachhorns (statisches Signal)
          signal UHF_FFB_Funkschluesseltyp_XIX_ZV_04_XIX_E3V_K2CANFD: start 58, 3 bit, little-endian, data-type-policy=OVERRIDE, i-signal-type=PRIMITIVE, init-value=0, base-type=BT_UHF_FFB_Funkschluesseltyp, compu {0=Cx0_kein_Funk (CM_UHF_FFB_Funkschluesseltyp_Cx0_kein_Funk), 1=Cx1_Funk_315MHz_Japan_2_Kanalig (CM_UHF_FFB_Funkschluesseltyp_Cx1_Funk_315MHz_Japan_2_Kanalig), 2=Cx2_Funk_434MHz_RdW_NAR_2_Kanalig (CM_UHF_FFB_Funkschluesseltyp_Cx2_Funk_434MHz_RdW_NAR_2_Kanalig), 3=Cx3_Funk_434MHz_Suedkorea_1_Kanalig (CM_UHF_FFB_Funkschluesseltyp_Cx3_Funk_434MHz_Suedkorea_1_Kanalig)}, range raw 0..3, to SAM(timeout 5 s)  # Typ des Funkschluessels und Funkfrequenzen
          signal UHF_FFB_SKC_anlernen_XIX_ZV_04_XIX_E3V_K2CANFD: start 61, 1 bit, little-endian, data-type-policy=OVERRIDE, i-signal-type=PRIMITIVE, init-value=0, base-type=BT_UHF_FFB_SKC_anlernen, compu {0=Cx0_nicht_aktiv (CM_UHF_FFB_SKC_anlernen_Cx0_nicht_aktiv), 1=Cx1_aktiv (CM_UHF_FFB_SKC_anlernen_Cx1_aktiv)}, range raw 0..1, to SAM(timeout 5 s)  # Neuer FFB_SKC von der WFS-Applikation
          signal ZV_HW_Motor_Safe_Hinten_XIX_ZV_04_XIX_E3V_K2CANFD: start 62, 1 bit, little-endian, data-type-policy=OVERRIDE, i-signal-type=PRIMITIVE, init-value=0, base-type=BT_ZV_HW_Motor_Safe_Hinten, compu {0=Cx0_Schloss_nicht_ansteuern (CM_ZV_HW_Motor_Safe_Hinten_Cx0_Schloss_nicht_ansteuern), 1=Cx1_Schloss_ansteuern (CM_ZV_HW_Motor_Safe_Hinten_Cx1_Schloss_ansteuern)}, range raw 0..1, to SAM(timeout 5 s)  # Ansteuervorgabe für die Safemotoren Hinten
          signal ZV_HW_Motor_Lock_HK_XIX_ZV_04_XIX_E3V_K2CANFD: start 63, 1 bit, little-endian, data-type-policy=OVERRIDE, i-signal-type=PRIMITIVE, init-value=0, base-type=BT_ZV_HW_Motor_Lock_HK, compu {0=Cx0_Schloss_nicht_ansteuern (CM_ZV_HW_Motor_Lock_HK_Cx0_Schloss_nicht_ansteuern), 1=Cx1_Schloss_ansteuern (CM_ZV_HW_Motor_Lock_HK_Cx1_Schloss_ansteuern)}, range raw 0..1, to SAM(timeout 5 s)  # Ansteuervorgabe für den Schlossmotor der Heckklappe
          mapping SG_ZV_04_XIX_E3V_K2CANFD: i-signal-group=SG_ZV_04_XIX_E3V_K2CANFD, transfer-property=TRIGGERED-WITHOUT-REPETITION
      pdu triggering PT_E3V_K2CANFD_XIX_TPCHType_CANFD_ISO_Diagnose_XIX_0x1C40000E_XIX_0x1C42000E_XIX_Physical: pdu=DCM_E3V_K2CANFD_XIX_TPCHType_CANFD_ISO_Diagnose_XIX_0x1C40000E_XIX_0x1C42000E_XIX_Physical, to SAM
      pdu triggering PT_E3V_K2CANFD_XIX_TPCHType_CANFD_ISO_Diagnose_XIX_0x1C410000_XIX_Functional: pdu=DCM_E3V_K2CANFD_XIX_TPCHType_CANFD_ISO_Diagnose_XIX_0x1C410000_XIX_Functional, to SAM
      pdu triggering PT_E3V_K2CANFD_XIX_TPCHType_CANFD_ISO_Diagnose_XIX_0x1C42000E_XIX_0x1C40000E_XIX_Physical: pdu=DCM_E3V_K2CANFD_XIX_TPCHType_CANFD_ISO_Diagnose_XIX_0x1C42000E_XIX_0x1C40000E_XIX_Physical, from SAM
      pdu triggering PT_E3V_K2CANFD_XIX_TPCHType_CANFD_OBDC_Diagnose_XIX_0x1C40020E_XIX_0x1C42020E_XIX_Physical: pdu=DCM_E3V_K2CANFD_XIX_TPCHType_CANFD_OBDC_Diagnose_XIX_0x1C40020E_XIX_0x1C42020E_XIX_Physical, to SAM
      pdu triggering PT_E3V_K2CANFD_XIX_TPCHType_CANFD_OBDC_Diagnose_XIX_0x1C410200_XIX_Functional: pdu=DCM_E3V_K2CANFD_XIX_TPCHType_CANFD_OBDC_Diagnose_XIX_0x1C410200_XIX_Functional, to SAM
      pdu triggering PT_E3V_K2CANFD_XIX_TPCHType_CANFD_OBDC_Diagnose_XIX_0x1C42020E_XIX_0x1C40020E_XIX_Physical: pdu=DCM_E3V_K2CANFD_XIX_TPCHType_CANFD_OBDC_Diagnose_XIX_0x1C42020E_XIX_0x1C40020E_XIX_Physical, from SAM
      pdu triggering PT_E3V_K2CANFD_XIX_TPCHType_CANHS_Flash_DIA_XIX_0x17FC1601_XIX_0x17FE1601_XIX_Physical: pdu=DCM_E3V_K2CANFD_XIX_TPCHType_CANHS_Flash_DIA_XIX_0x17FC1601_XIX_0x17FE1601_XIX_Physical, to SAM
      pdu triggering PT_E3V_K2CANFD_XIX_TPCHType_CANHS_Flash_DIA_XIX_0x17FC176E_XIX_0x17FE176E_XIX_Physical: pdu=DCM_E3V_K2CANFD_XIX_TPCHType_CANHS_Flash_DIA_XIX_0x17FC176E_XIX_0x17FE176E_XIX_Physical, to SAM
      pdu triggering PT_E3V_K2CANFD_XIX_TPCHType_CANHS_Flash_DIA_XIX_0x17FE1601_XIX_0x17FC1601_XIX_Physical: pdu=DCM_E3V_K2CANFD_XIX_TPCHType_CANHS_Flash_DIA_XIX_0x17FE1601_XIX_0x17FC1601_XIX_Physical, from SAM
      pdu triggering PT_E3V_K2CANFD_XIX_TPCHType_CANHS_Flash_DIA_XIX_0x17FE176E_XIX_0x17FC176E_XIX_Physical: pdu=DCM_E3V_K2CANFD_XIX_TPCHType_CANHS_Flash_DIA_XIX_0x17FE176E_XIX_0x17FC176E_XIX_Physical, from SAM
      pdu triggering PT_E3V_K2CANFD_XIX_TPCHType_CANHS_FoD_Master_XIX_0x17FC030E_XIX_0x17FE030E_XIX_Physical: pdu=CDD_E3V_K2CANFD_XIX_TPCHType_CANHS_FoD_Master_XIX_0x17FC030E_XIX_0x17FE030E_XIX_Physical, to SAM
      pdu triggering PT_E3V_K2CANFD_XIX_TPCHType_CANHS_FoD_Master_XIX_0x17FE030E_XIX_0x17FC030E_XIX_Physical: pdu=CDD_E3V_K2CANFD_XIX_TPCHType_CANHS_FoD_Master_XIX_0x17FE030E_XIX_0x17FC030E_XIX_Physical, from SAM
      pdu triggering PT_E3V_K2CANFD_XIX_TPCHType_CANHS_ISO_Diagnose_XIX_0x700_XIX_Functional: pdu=DCM_E3V_K2CANFD_XIX_TPCHType_CANHS_ISO_Diagnose_XIX_0x700_XIX_Functional, to SAM
      pdu triggering PT_E3V_K2CANFD_XIX_TPCHType_CANHS_ISO_Diagnose_XIX_0x70E_XIX_0x778_XIX_Physical: pdu=DCM_E3V_K2CANFD_XIX_TPCHType_CANHS_ISO_Diagnose_XIX_0x70E_XIX_0x778_XIX_Physical, to SAM
      pdu triggering PT_E3V_K2CANFD_XIX_TPCHType_CANHS_ISO_Diagnose_XIX_0x778_XIX_0x70E_XIX_Physical: pdu=DCM_E3V_K2CANFD_XIX_TPCHType_CANHS_ISO_Diagnose_XIX_0x778_XIX_0x70E_XIX_Physical, from SAM
      pdu triggering PT_SOK_E3V_K2CANFD_XIX_TPCHType_CANHS_FoD_Master_XIX_0x17FC030E_XIX_0x17FE030E_XIX_Physical: pdu=SOK_E3V_K2CANFD_XIX_TPCHType_CANHS_FoD_Master_XIX_0x17FC030E_XIX_0x17FE030E_XIX_Physical, to SAM
      pdu triggering PT_SOK_E3V_K2CANFD_XIX_TPCHType_CANHS_FoD_Master_XIX_0x17FE030E_XIX_0x17FC030E_XIX_Physical: pdu=SOK_E3V_K2CANFD_XIX_TPCHType_CANHS_FoD_Master_XIX_0x17FE030E_XIX_0x17FC030E_XIX_Physical, from SAM
      pdu triggering PT_SOK_KST_BCM_Resp_05: pdu=SOK_KST_BCM_Resp_05_XIX_E3V_K2CANFD, to SAM
      pdu triggering PT_SOK_ZV_HBFS_BCM_Resp_04: pdu=SOK_ZV_HBFS_BCM_Resp_04_XIX_E3V_K2CANFD, to SAM
      pdu triggering PT_SOK_ZV_HFS_BCM_Resp_03: pdu=SOK_ZV_HFS_BCM_Resp_03_XIX_E3V_K2CANFD, to SAM
      pdu triggering PT_SOK_ZV_HW_BCM_Resp_02: pdu=SOK_ZV_HW_BCM_Resp_02_XIX_E3V_K2CANFD, to SAM
      pdu triggering PT_SOK_ZV_Rueck_HW_Gateway_Resp_01: pdu=SOK_ZV_Rueck_HW_Gateway_Resp_01_XIX_E3V_K2CANFD, from SAM
      pdu triggering PT_VIN_01_Mx{00..02}: pdu=VIN_01_Mx{00..02}_XIX_E3V_K2CANFD, to SAM
  9 x lin cluster, all with baudrate=19200, protocol-name=LIN, protocol-version=2.0:
    E3V_SAM_LIN1
      lin physical channel CHNL: comm-connectors=CN_E3V_SAM_LIN1
        frame BCM1_LIN1_01_XIX_E3V_SAM_LIN1: id 0x31, from SAM, frame-length=8, lin-checksum=ENHANCED  # Verwendung im D4
          pdu BCM1_LIN1_01_XIX_E3V_SAM_LIN1: length=8, unused-bit-pattern=0  # Verwendung im D4
            signal Master_Zaehler_XIX_BCM1_LIN1_01_XIX_E3V_SAM_LIN1: start 0, 4 bit, little-endian, data-type-policy=OVERRIDE, i-signal-type=PRIMITIVE, init-value=0, base-type=BT_Master_Zaehler, compu {phys=raw for raw 0..15; unit Unit_None}, range phys 0..15 Unit_None, raw 0..15, unit=Unit_None, transfer-property=PENDING  # Der Master_Botschaftszähler (überlaufend) wird mit jeder Botschaft inkrementiert. Durch eine Auswertung des vom Slave zurückgesendeten Zählers (muss identisch sein) kann der korrekte Empfang der Botschaft festgestellt werden.
            signal Klemme_15_XIX_BCM1_LIN1_01_XIX_E3V_SAM_LIN1: start 4, 1 bit, little-endian, data-type-policy=OVERRIDE, i-signal-type=PRIMITIVE, init-value=0, base-type=BT_Klemme_15, compu {0=Cx0_Aus (CM_Klemme_15_Cx0_Aus), 1=Cx1_Ein (CM_Klemme_15_Cx1_Ein)}, range raw 0..1, transfer-property=PENDING
            signal Klemme_X_WWS_XIX_BCM1_LIN1_01_XIX_E3V_SAM_LIN1: start 5, 1 bit, little-endian, data-type-policy=OVERRIDE, i-signal-type=PRIMITIVE, init-value=0, base-type=BT_Klemme_X_WWS, compu {0=Cx0_Aus (CM_Klemme_X_WWS_Cx0_Aus), 1=Cx1_Ein (CM_Klemme_X_WWS_Cx1_Ein)}, range raw 0..1, transfer-property=PENDING  # Klemme X für Wischwinkelsteuererung
            signal Verglasung_offen_XIX_BCM1_LIN1_01_XIX_E3V_SAM_LIN1: start 6, 1 bit, little-endian, data-type-policy=OVERRIDE, i-signal-type=PRIMITIVE, init-value=0, base-type=BT_Verglasung_offen, compu {0=Cx0_geschlossen (CM_Verglasung_offen_Cx0_geschlossen), 1=Cx1_geoeffnet (CM_Verglasung_offen_Cx1_geoeffnet)}, range raw 0..1, transfer-property=PENDING  # Information über den Status der Verglasung
            signal Fronthaube_geoeffnet_XIX_BCM1_LIN1_01_XIX_E3V_SAM_LIN1: start 7, 1 bit, little-endian, data-type-policy=OVERRIDE, i-signal-type=PRIMITIVE, init-value=0, base-type=BT_Fronthaube_geoeffnet, compu {0=Cx0_geschlossen (CM_Fronthaube_geoeffnet_Cx0_geschlossen), 1=Cx1_geoeffnet (CM_Fronthaube_geoeffnet_Cx1_geoeffnet)}, range raw 0..1, transfer-property=PENDING  # Information über den Status der Fronthaube
            signal WH_Intervallstufen_XIX_BCM1_LIN1_01_XIX_E3V_SAM_LIN1: start 8, 4 bit, little-endian, data-type-policy=OVERRIDE, i-signal-type=PRIMITIVE, init-value=0, base-type=BT_WH_Intervallstufen, invalid-value=Invalid_WH_Intervallstufen_XIX_BCM1_LIN1_01_XIX_E3V_SAM_LIN1:15, compu {0=Cx0_Init_Default (CM_WH_Intervallstufen_Cx0_Init_Default) (Init / Default), 1=Cx1_Intervallstufe_1 (CM_WH_Intervallstufen_Cx1_Intervallstufe_1) (Intervallstufe 1), 5=Cx5_Intervallstufe_2 (CM_WH_Intervallstufen_Cx5_Intervallstufe_2) (Intervallstufe 2), 9=Cx9_Intervallstufe_3 (CM_WH_Intervallstufen_Cx9_Intervallstufe_3) (Intervallstufe 3), 13=Cxd_Intervallstufe_4 (CM_WH_Intervallstufen_Cxd_Intervallstufe_4) (Intervallstufe 4), 15=Cxf_Fehler (CM_WH_Intervallstufen_Cxf_Fehler)}, range raw 0..15, transfer-property=PENDING  # Wischerhebel: Stellung Intervallstufen
            signal WH_Tippwischen_XIX_BCM1_LIN1_01_XIX_E3V_SAM_LIN1: start 12, 1 bit, little-endian, data-type-policy=OVERRIDE, i-signal-type=PRIMITIVE, init-value=0, base-type=BT_WH_Tippwischen, compu {0=Cx0_Aus (CM_WH_Tippwischen_Cx0_Aus), 1=Cx1_Ein (CM_WH_Tippwischen_Cx1_Ein)}, range raw 0..1, transfer-property=PENDING
            signal WH_Intervall_XIX_BCM1_LIN1_01_XIX_E3V_SAM_LIN1: start 13, 1 bit, little-endian, data-type-policy=OVERRIDE, i-signal-type=PRIMITIVE, init-value=0, base-type=BT_WH_Intervall, compu {0=Cx0_aus (CM_WH_Intervall_Cx0_aus), 1=Cx1_Wischerhebel_in_Stellung_Intervall (CM_WH_Intervall_Cx1_Wischerhebel_in_Stellung_Intervall) (Wischerhebel in Stellung Intervall)}, range raw 0..1, transfer-property=PENDING  # Wischerhebel: Stellung Intervall
            signal WH_WischerStufe1_XIX_BCM1_LIN1_01_XIX_E3V_SAM_LIN1: start 14, 1 bit, little-endian, data-type-policy=OVERRIDE, i-signal-type=PRIMITIVE, init-value=0, base-type=BT_WH_WischerStufe1, compu {0=Cx0_aus (CM_WH_WischerStufe1_Cx0_aus), 1=Cx1_Wischerhebel_in_Stufe_Wischen_1 (CM_WH_WischerStufe1_Cx1_Wischerhebel_in_Stufe_Wischen_1) (Wischerhebel in Stufe Wischen 1)}, range raw 0..1, transfer-property=PENDING  # Wischerhebel: Stufe Wischen 1
            signal WH_WischerStufe2_XIX_BCM1_LIN1_01_XIX_E3V_SAM_LIN1: start 15, 1 bit, little-endian, data-type-policy=OVERRIDE, i-signal-type=PRIMITIVE, init-value=0, base-type=BT_WH_WischerStufe2, compu {0=Cx0_aus (CM_WH_WischerStufe2_Cx0_aus), 1=Cx1_Wischerhebel_in_Stufe_Wischen_2 (CM_WH_WischerStufe2_Cx1_Wischerhebel_in_Stufe_Wischen_2) (Wischerhebel in Stufe Wischen 2)}, range raw 0..1, transfer-property=PENDING  # Wischerhebel: Stufe Wischen 2
            signal WH_Frontwaschen_XIX_BCM1_LIN1_01_XIX_E3V_SAM_LIN1: start 16, 1 bit, little-endian, data-type-policy=OVERRIDE, i-signal-type=PRIMITIVE, init-value=0, base-type=BT_WH_Frontwaschen, compu {0=Cx0_aus (CM_WH_Frontwaschen_Cx0_aus), 1=Cx1_Wischerhebel_in_Stellung_Wisch_Wasch_vorne (CM_WH_Frontwaschen_Cx1_Wischerhebel_in_Stellung_Wisch_Wasch_vorne) (Wischerhebel in Stellung Wisch Wasch vorne)}, range raw 0..1, transfer-property=PENDING  # Wischerhebel: Stellung Wisch Wasch vorne
            signal Servicestellung_Wischer_XIX_BCM1_LIN1_01_XIX_E3V_SAM_LIN1: start 17, 1 bit, little-endian, data-type-policy=OVERRIDE, i-signal-type=PRIMITIVE, init-value=0, base-type=BT_Servicestellung_Wischer, compu {0=Cx0_Aus (CM_Servicestellung_Wischer_Cx0_Aus), 1=Cx1_Ein (CM_Servicestellung_Wischer_Cx1_Ein)}, range raw 0..1, transfer-property=PENDING  # Anforderung Serviceposition Frontwischermotor
            signal FT_Tuer_geoeffnet_XIX_BCM1_LIN1_01_XIX_E3V_SAM_LIN1: start 18, 1 bit, little-endian, data-type-policy=OVERRIDE, i-signal-type=PRIMITIVE, init-value=0, base-type=BT_FT_Tuer_geoeffnet, compu {0=Cx0_geschlossen (CM_FT_Tuer_geoeffnet_Cx0_geschlossen), 1=Cx1_Tuer_offen (CM_FT_Tuer_geoeffnet_Cx1_Tuer_offen)}, range raw 0..1, transfer-property=PENDING  # Zeigt eine geöffnete Tür an
            signal Wendelage_unten_Wischer_XIX_BCM1_LIN1_01_XIX_E3V_SAM_LIN1: start 19, 1 bit, little-endian, data-type-policy=OVERRIDE, i-signal-type=PRIMITIVE, init-value=0, base-type=BT_Wendelage_unten_Wischer, compu {0=Cx0_Aus (CM_Wendelage_unten_Wischer_Cx0_Aus), 1=Cx1_Ein (CM_Wendelage_unten_Wischer_Cx1_Ein)}, range raw 0..1, transfer-property=PENDING  # Anforderung Frontwischermotor Wendelage unten
            signal Wendelage_oben_Wischer_XIX_BCM1_LIN1_01_XIX_E3V_SAM_LIN1: start 20, 1 bit, little-endian, data-type-policy=OVERRIDE, i-signal-type=PRIMITIVE, init-value=0, base-type=BT_Wendelage_oben_Wischer, compu {0=Cx0_Aus (CM_Wendelage_oben_Wischer_Cx0_Aus), 1=Cx1_Ein (CM_Wendelage_oben_Wischer_Cx1_Ein)}, range raw 0..1, transfer-property=PENDING  # Anforderung Frontwischermotor Wendelage oben
            signal SMLS_alt_XIX_BCM1_LIN1_01_XIX_E3V_SAM_LIN1: start 21, 1 bit, little-endian, data-type-policy=OVERRIDE, i-signal-type=PRIMITIVE, init-value=1, base-type=BT_SMLS_alt, compu {0=Cx0_aktuell (CM_SMLS_alt_Cx0_aktuell), 1=Cx1_veraltet (CM_SMLS_alt_Cx1_veraltet)}, range raw 0..1, transfer-property=PENDING  # Signale vom SMLS sind veraltet/fehlerhaft
            signal BT_Tuer_geoeffnet_XIX_BCM1_LIN1_01_XIX_E3V_SAM_LIN1: start 22, 1 bit, little-endian, data-type-policy=OVERRIDE, i-signal-type=PRIMITIVE, init-value=0, base-type=BT_BT_Tuer_geoeffnet, compu {0=Cx0_geschlossen (CM_BT_Tuer_geoeffnet_Cx0_geschlossen), 1=Cx1_offen (CM_BT_Tuer_geoeffnet_Cx1_offen)}, range raw 0..1, transfer-property=PENDING  # Zeigt eine geöffnete Tür an
            signal SRA_Sequenz_Status_XIX_BCM1_LIN1_01_XIX_E3V_SAM_LIN1: start 23, 1 bit, little-endian, data-type-policy=OVERRIDE, i-signal-type=PRIMITIVE, init-value=0, base-type=BT_SRA_Sequenz_Status, compu {0=Cx0_Aus (CM_SRA_Sequenz_Status_Cx0_Aus), 1=Cx1_Ein (CM_SRA_Sequenz_Status_Cx1_Ein)}, range raw 0..1, transfer-property=PENDING  # BCM meldet den Aktivierungsstatus der SRA
            signal WWS_Produktionsmodus_XIX_BCM1_LIN1_01_XIX_E3V_SAM_LIN1: start 24, 1 bit, little-endian, data-type-policy=OVERRIDE, i-signal-type=PRIMITIVE, base-type=BT_WWS_Produktionsmodus, compu {0=Cx0_Produktionsmodus_wird_seitens_Master_SG_BCM_nicht_angefordert (CM_WWS_Produktionsmodus_Cx0_Produktionsmodus_wird_seitens_Master_SG_BCM_nicht_angefordert) (Produktionsmodus wird seitens Master-SG (BCM) nicht angefordert), 1=Cx1_Produktionsmodus_wird_seitens_Master_SG_BCM_angefordert (CM_WWS_Produktionsmodus_Cx1_Produktionsmodus_wird_seitens_Master_SG_BCM_angefordert) (Produktionsmodus wird seitens Master-SG (BCM) angefordert)}, range raw 0..1, transfer-property=PENDING  # Anforderungssignal Mastersteuergerät zur Anforderung Produktionsmodus im LIN Frontwischer. LIN Signal in der BCM Masterbotschaft auf LIN1 => BCM1::LIN1 0 := keine Anforderung Produktionsmodus seitens BCM 1 := aktive Produktionsmodusanforderung seitens BCM
            signal MO_Fahrbereitschaft_XIX_BCM1_LIN1_01_XIX_E3V_SAM_LIN1: start 25, 2 bit, little-endian, data-type-policy=OVERRIDE, i-signal-type=PRIMITIVE, init-value=0, base-type=BT_MO_Fahrbereitschaft, compu {0=Cx0_Fahrzykl_inaktiv_kein_Antrieb (CM_MO_Fahrbereitschaft_Cx0_Fahrzykl_inaktiv_kein_Antrieb) (Fahrzykl_inaktiv__kein_Antrieb), 1=Cx1_Fahrzykl_aktiv_kein_Antrieb (CM_MO_Fahrbereitschaft_Cx1_Fahrzykl_aktiv_kein_Antrieb) (Fahrzykl_aktiv__kein_Antrieb), 2=Cx2_Fahrzykl_aktiv_Antrieb_moeglich (CM_MO_Fahrbereitschaft_Cx2_Fahrzykl_aktiv_Antrieb_moeglich) (Fahrzykl_aktiv__Antrieb_moeglich)}, range raw 0..2, transfer-property=PENDING  # Das Signal MO_Fahrbereitschaft zeigt in mehreren Stufen an, ob der Motor in einem anfahrbereiten Zustand ist.
            signal Motor_35_alt_XIX_BCM1_LIN1_01_XIX_E3V_SAM_LIN1: start 27, 1 bit, little-endian, data-type-policy=OVERRIDE, i-signal-type=PRIMITIVE, init-value=1, base-type=BT_Motor_35_alt, compu {0=Cx0_aktuell (CM_Motor_35_alt_Cx0_aktuell), 1=Cx1_veraltet (CM_Motor_35_alt_Cx1_veraltet)}, range raw 0..1, transfer-property=PENDING  # Veraltet-Bit für die Singale aus Quell-Botschaft Motor_35 MLBevo_Signale: MO_Heckspoiler_Anf Das Alt-Bit wird vom LIN-Master gesetzt und sobald die betreffende CAN-Botschaft ausbleibt.
            signal BCM_Wischer_Parklage_XIX_BCM1_LIN1_01_XIX_E3V_SAM_LIN1: start 29, 1 bit, little-endian, data-type-policy=OVERRIDE, i-signal-type=PRIMITIVE, init-value=0, base-type=BT_BCM_Wischer_Parklage, compu {0=Cx0_inaktiv (CM_BCM_Wischer_Parklage_Cx0_inaktiv), 1=Cx1_aktiv (CM_BCM_Wischer_Parklage_Cx1_aktiv)}, range raw 0..1, transfer-property=PENDING  # Signal wird vom Mastersteuergerät gesetzt. Parklageninformation wird bei inaktiven Wischer in der Parklage gesetzt.
            signal ESP_v_Signal_8Bit_XIX_BCM1_LIN1_01_XIX_E3V_SAM_LIN1: start 32, 8 bit, little-endian, data-type-policy=OVERRIDE, i-signal-type=PRIMITIVE, init-value=254, base-type=BT_ESP_v_Signal_8Bit, compu {phys=raw*2.56 for raw 0..253, 254=Cxfe_Init (CM_ESP_v_Signal_8Bit_Cxfe_Init), 255=Cxff_Fehler (CM_ESP_v_Signal_8Bit_Cxff_Fehler); unit Unit_KiloMeterPerHour}, range phys 0..647.68 Unit_KiloMeterPerHour, raw 0..255, unit=Unit_KiloMeterPerHour, transfer-property=PENDING
            signal Aussentemp_gef_XIX_BCM1_LIN1_01_XIX_E3V_SAM_LIN1: start 40, 8 bit, little-endian, data-type-policy=OVERRIDE, i-signal-type=PRIMITIVE, init-value=254, base-type=BT_Aussentemp_gef, compu {phys=raw*0.5-50 for raw 0..252, 253=Cxfd_nicht_verbaut (CM_Aussentemp_gef_Cxfd_nicht_verbaut) (nicht verbaut), 254=Cxfe_Init (CM_Aussentemp_gef_Cxfe_Init), 255=Cxff_Fehler (CM_Aussentemp_gef_Cxff_Fehler); unit Unit_DegreCelsi}, range phys -50..76 Unit_DegreCelsi, raw 0..255, unit=Unit_DegreCelsi, transfer-property=PENDING
            signal Empfindlichkeit_LS_XIX_BCM1_LIN1_01_XIX_E3V_SAM_LIN1: start 48, 3 bit, little-endian, data-type-policy=OVERRIDE, i-signal-type=PRIMITIVE, init-value=3, base-type=BT_Empfindlichkeit_LS, compu {0=Cx0_45 (CM_Empfindlichkeit_LS_Cx0_45) (-45%), 1=Cx1_30 (CM_Empfindlichkeit_LS_Cx1_30) (-30%), 2=Cx2_15 (CM_Empfindlichkeit_LS_Cx2_15) (-15%), 3=Cx3_normal (CM_Empfindlichkeit_LS_Cx3_normal), 4=Cx4_20 (CM_Empfindlichkeit_LS_Cx4_20) (+20%), 5=Cx5_40 (CM_Empfindlichkeit_LS_Cx5_40) (+40%), 6=Cx6_60 (CM_Empfindlichkeit_LS_Cx6_60) (+60%)}, range raw 0..6, transfer-property=PENDING  # Einstellung der Empfindlichkeit des Lichtsensors
            signal Deaktivierung_RS_XIX_BCM1_LIN1_01_XIX_E3V_SAM_LIN1: start 51, 1 bit, little-endian, data-type-policy=OVERRIDE, i-signal-type=PRIMITIVE, init-value=0, base-type=BT_Deaktivierung_RS, compu {0=Cx0_normal (CM_Deaktivierung_RS_Cx0_normal), 1=Cx1_deaktiv (CM_Deaktivierung_RS_Cx1_deaktiv)}, range raw 0..1, transfer-property=PENDING  # Deaktivierung Regensensor
            signal Empfindlichkeit_RS_XIX_BCM1_LIN1_01_XIX_E3V_SAM_LIN1: start 52, 3 bit, little-endian, data-type-policy=OVERRIDE, i-signal-type=PRIMITIVE, init-value=3, base-type=BT_Empfindlichkeit_RS, compu {0=Cx0_am_unempfindlichsten (CM_Empfindlichkeit_RS_Cx0_am_unempfindlichsten) (am unempfindlichsten), 1=Cx1_unempfindlicher (CM_Empfindlichkeit_RS_Cx1_unempfindlicher), 2=Cx2_unempfindlich (CM_Empfindlichkeit_RS_Cx2_unempfindlich), 3=Cx3_normal (CM_Empfindlichkeit_RS_Cx3_normal), 4=Cx4_empfindlich (CM_Empfindlichkeit_RS_Cx4_empfindlich), 5=Cx5_empfindlicher (CM_Empfindlichkeit_RS_Cx5_empfindlicher), 6=Cx6_am_empfindlichsten (CM_Empfindlichkeit_RS_Cx6_am_empfindlichsten) (am empfindlichsten)}, range raw 0..6, transfer-property=PENDING  # Einstellung der Empfindlichkeit des Regensensors
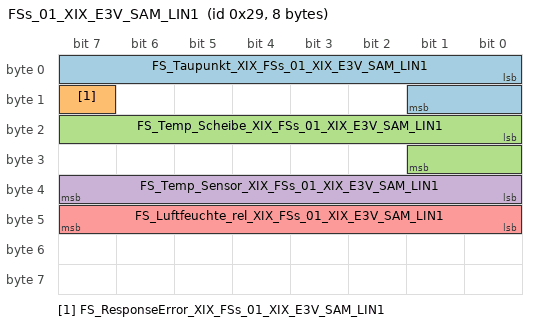
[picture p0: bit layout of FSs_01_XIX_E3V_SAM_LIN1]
        frame FSs_01_XIX_E3V_SAM_LIN1: id 0x29, to SAM, frame-length=8, lin-checksum=ENHANCED
          pdu FSs_01_XIX_E3V_SAM_LIN1: length=8, unused-bit-pattern=0
            signal FS_Taupunkt_XIX_FSs_01_XIX_E3V_SAM_LIN1: start 0, 10 bit, little-endian, data-type-policy=OVERRIDE, i-signal-type=PRIMITIVE, init-value=0, base-type=BT_FS_Taupunkt, invalid-value=Invalid_FS_Taupunkt_XIX_FSs_01_XIX_E3V_SAM_LIN1:1023, compu {0=Cx0_nicht_verfuegbar (CM_FS_Taupunkt_Cx0_nicht_verfuegbar) (nicht verfuegbar), phys=raw*0.1-39.6 for raw 1..1000, 1023=Cx3ff_Fehler (CM_FS_Taupunkt_Cx3ff_Fehler); unit Unit_DegreCelsi}, range phys -39.5..60.4 Unit_DegreCelsi, raw 0..1023, unit=Unit_DegreCelsi, transfer-property=PENDING, to SAM(timeout 3.5 s)  # berechneter Taupunkt
            signal FS_ResponseError_XIX_FSs_01_XIX_E3V_SAM_LIN1: start 15, 1 bit, little-endian, data-type-policy=OVERRIDE, i-signal-type=PRIMITIVE, init-value=0, base-type=BT_FS_ResponseError, invalid-value=Invalid_FS_ResponseError_XIX_FSs_01_XIX_E3V_SAM_LIN1:1, compu {0=Cx0_normal (CM_FS_ResponseError_Cx0_normal), 1=Cx1_Fehler (CM_FS_ResponseError_Cx1_Fehler)}, range raw 0..1, transfer-property=PENDING, to SAM(timeout 3.5 s)  # siehe LIN2.0-Specification (Darf nicht über ein Fehlergueltigkeitsbit abgesichtert werden!)
            signal FS_Temp_Scheibe_XIX_FSs_01_XIX_E3V_SAM_LIN1: start 16, 10 bit, little-endian, data-type-policy=OVERRIDE, i-signal-type=PRIMITIVE, init-value=0, base-type=BT_FS_Temp_Scheibe, invalid-value=Invalid_FS_Temp_Scheibe_XIX_FSs_01_XIX_E3V_SAM_LIN1:1023, compu {0=Cx0_nicht_verfuegbar (CM_FS_Temp_Scheibe_Cx0_nicht_verfuegbar) (nicht verfuegbar), phys=raw*0.1-39.6 for raw 1..1000, 1023=Cx3ff_Fehler (CM_FS_Temp_Scheibe_Cx3ff_Fehler); unit Unit_DegreCelsi}, range phys -39.5..60.4 Unit_DegreCelsi, raw 0..1023, unit=Unit_DegreCelsi, transfer-property=PENDING, to SAM(timeout 3.5 s)  # gemessene Frontscheibentemperatur
            signal FS_Temp_Sensor_XIX_FSs_01_XIX_E3V_SAM_LIN1: start 32, 8 bit, little-endian, data-type-policy=OVERRIDE, i-signal-type=PRIMITIVE, init-value=0, base-type=BT_FS_Temp_Sensor, invalid-value=Invalid_FS_Temp_Sensor_XIX_FSs_01_XIX_E3V_SAM_LIN1:255, compu {0=Cx0_nicht_verfuegbar (CM_FS_Temp_Sensor_Cx0_nicht_verfuegbar) (nicht verfuegbar), phys=raw*0.5-40 for raw 1..254, 255=Cxff_Fehler (CM_FS_Temp_Sensor_Cxff_Fehler); unit Unit_DegreCelsi}, range phys -39.5..87 Unit_DegreCelsi, raw 0..255, unit=Unit_DegreCelsi, transfer-property=PENDING, to SAM(timeout 3.5 s)  # gemessene Sensortemperatur
            signal FS_Luftfeuchte_rel_XIX_FSs_01_XIX_E3V_SAM_LIN1: start 40, 8 bit, little-endian, data-type-policy=OVERRIDE, i-signal-type=PRIMITIVE, init-value=0, base-type=BT_FS_Luftfeuchte_rel, invalid-value=Invalid_FS_Luftfeuchte_rel_XIX_FSs_01_XIX_E3V_SAM_LIN1:255, compu {0=Cx0_nicht_verfuegbar (CM_FS_Luftfeuchte_rel_Cx0_nicht_verfuegbar) (nicht verfuegbar), phys=raw*0.5-0.5 for raw 1..201, 255=Cxff_Fehler (CM_FS_Luftfeuchte_rel_Cxff_Fehler); unit Unit_PerCent}, range phys 0..100 Unit_PerCent, raw 0..255, unit=Unit_PerCent, transfer-property=PENDING, to SAM(timeout 3.5 s)  # gemessene relative Luftfeuchte
        frame MasterReq_XIX_E3V_SAM_LIN1: id 0x3C, from SAM, frame-length=8, lin-checksum=CLASSIC
          n pdu MasterReq_XIX_E3V_SAM_LIN1: length=8
        frame RLSs_01_XIX_E3V_SAM_LIN1: id 0x23, to SAM, frame-length=8, lin-checksum=ENHANCED
          pdu RLSs_01_XIX_E3V_SAM_LIN1_E2E: length=8, unused-bit-pattern=0  # Fuer die Botschaft ist das Cyclic-Timing 0.08 zu verwenden.
            signal RLS_Zaehler_XIX_RLSs_01_XIX_E3V_SAM_LIN1: start 0, 4 bit, little-endian, data-type-policy=OVERRIDE, i-signal-type=PRIMITIVE, base-type=BT_RLS_Zaehler, compu {phys=raw for raw 0..15}, range phys 0..15, raw 0..15, to SAM(timeout 3.5 s)
            signal RLS_Qualifizierungsbit_XIX_RLSs_01_XIX_E3V_SAM_LIN1: start 4, 1 bit, little-endian, data-type-policy=OVERRIDE, i-signal-type=PRIMITIVE, init-value=0, base-type=BT_RLS_Qualifizierungsbit, compu {0=Cx0_ungueltig (CM_RLS_Qualifizierungsbit_Cx0_ungueltig), 1=Cx1_gueltig (CM_RLS_Qualifizierungsbit_Cx1_gueltig)}, range raw 0..1, to SAM(timeout 3.5 s)  # Qualifizierungsbit für die Signale "LS_Licht_ein" und "LS_Licht_ein_invers"
            signal RS_Wischergeschwindigkeit_XIX_RLSs_01_XIX_E3V_SAM_LIN1: start 5, 3 bit, little-endian, data-type-policy=OVERRIDE, i-signal-type=PRIMITIVE, init-value=0, base-type=BT_RS_Wischergeschwindigkeit, compu {0=Cx0_kein_Wischen (CM_RS_Wischergeschwindigkeit_Cx0_kein_Wischen) (kein Wischen), 1=Cx1_42_Huebe_min (CM_RS_Wischergeschwindigkeit_Cx1_42_Huebe_min) (42 Huebe/min), 2=Cx2_45_Huebe_min (CM_RS_Wischergeschwindigkeit_Cx2_45_Huebe_min) (45 Huebe/min), 3=Cx3_48_Huebe_min (CM_RS_Wischergeschwindigkeit_Cx3_48_Huebe_min) (48 Huebe/min), 4=Cx4_51_Huebe_min (CM_RS_Wischergeschwindigkeit_Cx4_51_Huebe_min) (51 Huebe/min), 5=Cx5_54_Huebe_min (CM_RS_Wischergeschwindigkeit_Cx5_54_Huebe_min) (54 Huebe/min), 6=Cx6_57_Huebe_min (CM_RS_Wischergeschwindigkeit_Cx6_57_Huebe_min) (57 Huebe/min), 7=Cx7_60_Huebe_min (CM_RS_Wischergeschwindigkeit_Cx7_60_Huebe_min) (60 Huebe/min)}, range raw 0..7, to SAM(timeout 3.5 s)  # Wischergeschwindigkeit (Hübe/min)
            signal RS_Schwall_XIX_RLSs_01_XIX_E3V_SAM_LIN1: start 8, 1 bit, little-endian, data-type-policy=OVERRIDE, i-signal-type=PRIMITIVE, init-value=0, base-type=BT_RS_Schwall, compu {0=Cx0_Aus (CM_RS_Schwall_Cx0_Aus), 1=Cx1_Ein (CM_RS_Schwall_Cx1_Ein)}, range raw 0..1, to SAM(timeout 3.5 s)  # Schwallereignis
            signal RS_Verglasung_schliessen_XIX_RLSs_01_XIX_E3V_SAM_LIN1: start 9, 1 bit, little-endian, data-type-policy=OVERRIDE, i-signal-type=PRIMITIVE, init-value=0, base-type=BT_RS_Verglasung_schliessen, compu {0=Cx0_Verglasung_nicht_schliessen (CM_RS_Verglasung_schliessen_Cx0_Verglasung_nicht_schliessen) (Verglasung nicht schliessen), 1=Cx1_Verglasung_schliessen (CM_RS_Verglasung_schliessen_Cx1_Verglasung_schliessen) (Verglasung schliessen)}, range raw 0..1, to SAM(timeout 3.5 s)  # Anforderung: Verglasung schliessen
            signal RS_versParklage_Wischer_XIX_RLSs_01_XIX_E3V_SAM_LIN1: start 10, 1 bit, little-endian, data-type-policy=OVERRIDE, i-signal-type=PRIMITIVE, init-value=0, base-type=BT_RS_versParklage_Wischer, compu {0=Cx0_Aus (CM_RS_versParklage_Wischer_Cx0_Aus), 1=Cx1_Ein (CM_RS_versParklage_Wischer_Cx1_Ein)}, range raw 0..1, to SAM(timeout 3.5 s)  # versenkte Parklage Wischer
            signal LS_Licht_ein_XIX_RLSs_01_XIX_E3V_SAM_LIN1: start 11, 1 bit, little-endian, data-type-policy=OVERRIDE, i-signal-type=PRIMITIVE, init-value=0, base-type=BT_LS_Licht_ein, compu {0=Cx0_Aus (CM_LS_Licht_ein_Cx0_Aus), 1=Cx1_Ein (CM_LS_Licht_ein_Cx1_Ein)}, range raw 0..1, to SAM(timeout 3.5 s)  # Anfoderung Fahrlicht
            signal LS_Licht_ein_invers_XIX_RLSs_01_XIX_E3V_SAM_LIN1: start 12, 1 bit, little-endian, data-type-policy=OVERRIDE, i-signal-type=PRIMITIVE, init-value=1, base-type=BT_LS_Licht_ein_invers, compu {0=Cx0_Aus (CM_LS_Licht_ein_invers_Cx0_Aus), 1=Cx1_Ein (CM_LS_Licht_ein_invers_Cx1_Ein)}, range raw 0..1, to SAM(timeout 3.5 s)  # Inversbit Anforderung Fahrlicht
            signal LS_Dunkel_XIX_RLSs_01_XIX_E3V_SAM_LIN1: start 13, 1 bit, little-endian, data-type-policy=OVERRIDE, i-signal-type=PRIMITIVE, init-value=0, base-type=BT_LS_Dunkel, compu {0=Cx0_Hell (CM_LS_Dunkel_Cx0_Hell), 1=Cx1_Dunkel (CM_LS_Dunkel_Cx1_Dunkel)}, range raw 0..1, to SAM(timeout 3.5 s)  # Regen- / Lichtsensor
            signal LS_TFL_mit_SL_ein_XIX_RLSs_01_XIX_E3V_SAM_LIN1: start 14, 1 bit, little-endian, data-type-policy=OVERRIDE, i-signal-type=PRIMITIVE, init-value=1, base-type=BT_LS_TFL_mit_SL_ein, compu {0=Cx0_TFL_mit_SL_aus (CM_LS_TFL_mit_SL_ein_Cx0_TFL_mit_SL_aus), 1=Cx1_TFL_mit_SL_ein (CM_LS_TFL_mit_SL_ein_Cx1_TFL_mit_SL_ein)}, range raw 0..1, to SAM(timeout 3.5 s)  # Anforderung Tagfahrlich mit Schlusslicht
            signal RS_Regenfahrlicht_XIX_RLSs_01_XIX_E3V_SAM_LIN1: start 15, 1 bit, little-endian, data-type-policy=OVERRIDE, i-signal-type=PRIMITIVE, init-value=0, base-type=BT_RS_Regenfahrlicht, compu {0=Cx0_Aus (CM_RS_Regenfahrlicht_Cx0_Aus), 1=Cx1_Ein (CM_RS_Regenfahrlicht_Cx1_Ein)}, range raw 0..1, to SAM(timeout 3.5 s)  # Regenlicht Anforderung
            signal RS_AdaptierungError_XIX_RLSs_01_XIX_E3V_SAM_LIN1: start 16, 1 bit, little-endian, data-type-policy=OVERRIDE, i-signal-type=PRIMITIVE, init-value=0, base-type=BT_RS_AdaptierungError, invalid-value=Invalid_RS_AdaptierungError_XIX_RLSs_01_XIX_E3V_SAM_LIN1:1, compu {0=Cx0_normal (CM_RS_AdaptierungError_Cx0_normal), 1=Cx1_Fehler (CM_RS_AdaptierungError_Cx1_Fehler)}, range raw 0..1, to SAM(timeout 3.5 s)  # Adaptierungsfehler Regensensor
            signal RS_Error_XIX_RLSs_01_XIX_E3V_SAM_LIN1: start 17, 1 bit, little-endian, data-type-policy=OVERRIDE, i-signal-type=PRIMITIVE, init-value=0, base-type=BT_RS_Error, invalid-value=Invalid_RS_Error_XIX_RLSs_01_XIX_E3V_SAM_LIN1:1, compu {0=Cx0_normal (CM_RS_Error_Cx0_normal), 1=Cx1_Fehler (CM_RS_Error_Cx1_Fehler)}, range raw 0..1, to SAM(timeout 3.5 s)  # Fehler/Defekt Regensensorik
            signal LS_Error_XIX_RLSs_01_XIX_E3V_SAM_LIN1: start 18, 1 bit, little-endian, data-type-policy=OVERRIDE, i-signal-type=PRIMITIVE, init-value=0, base-type=BT_LS_Error, invalid-value=Invalid_LS_Error_XIX_RLSs_01_XIX_E3V_SAM_LIN1:1, compu {0=Cx0_normal (CM_LS_Error_Cx0_normal), 1=Cx1_Fehler (CM_LS_Error_Cx1_Fehler)}, range raw 0..1, to SAM(timeout 3.5 s)  # Fehler/Defekt Lichtsensorik
            signal RLS_ResponseError_XIX_RLSs_01_XIX_E3V_SAM_LIN1: start 19, 1 bit, little-endian, data-type-policy=OVERRIDE, i-signal-type=PRIMITIVE, init-value=0, base-type=BT_RLS_ResponseError, invalid-value=Invalid_RLS_ResponseError_XIX_RLSs_01_XIX_E3V_SAM_LIN1:1, compu {0=Cx0_normal (CM_RLS_ResponseError_Cx0_normal), 1=Cx1_Fehler (CM_RLS_ResponseError_Cx1_Fehler)}, range raw 0..1, to SAM(timeout 3.5 s)  # siehe LIN2.0-Specification (Darf nicht über ein Fehlergueltigkeitsbit abgesichtert werden!)
            signal RLS_Vorfeldhelligkeit_Boost_XIX_RLSs_01_XIX_E3V_SAM_LIN1: start 20, 4 bit, little-endian, data-type-policy=OVERRIDE, i-signal-type=PRIMITIVE, init-value=15, base-type=BT_RLS_Vorfeldhelligkeit_Boost, compu {0=Cx0_groesser_24413_Lux (CM_RLS_Vorfeldhelligkeit_Boost_Cx0_groesser_24413_Lux), 1=Cx1_bis_24413_Lux (CM_RLS_Vorfeldhelligkeit_Boost_Cx1_bis_24413_Lux), 2=Cx2_bis_22193_Lux (CM_RLS_Vorfeldhelligkeit_Boost_Cx2_bis_22193_Lux), 3=Cx3_bis_20176_Lux (CM_RLS_Vorfeldhelligkeit_Boost_Cx3_bis_20176_Lux), 4=Cx4_bis_18342_Lux (CM_RLS_Vorfeldhelligkeit_Boost_Cx4_bis_18342_Lux), 5=Cx5_bis_16647_Lux (CM_RLS_Vorfeldhelligkeit_Boost_Cx5_bis_16647_Lux), 6=Cx6_bis_15158_Lux (CM_RLS_Vorfeldhelligkeit_Boost_Cx6_bis_15158_Lux), 7=Cx7_bis_13780_Lux (CM_RLS_Vorfeldhelligkeit_Boost_Cx7_bis_13780_Lux), 8=Cx8_bis_12527_Lux (CM_RLS_Vorfeldhelligkeit_Boost_Cx8_bis_12527_Lux), 9=Cx9_bis_11388_Lux (CM_RLS_Vorfeldhelligkeit_Boost_Cx9_bis_11388_Lux), 10=Cxa_bis_10353_Lux (CM_RLS_Vorfeldhelligkeit_Boost_Cxa_bis_10353_Lux), 11=Cxb_bis_9412_Lux (CM_RLS_Vorfeldhelligkeit_Boost_Cxb_bis_9412_Lux), 12=Cxc_bis_8556_Lux (CM_RLS_Vorfeldhelligkeit_Boost_Cxc_bis_8556_Lux), 13=Cxd_bis_7778_Lux (CM_RLS_Vorfeldhelligkeit_Boost_Cxd_bis_7778_Lux), 14=Cxe_bis_7071_Lux (CM_RLS_Vorfeldhelligkeit_Boost_Cxe_bis_7071_Lux), 15=Cxf_bis_6428_Lux (CM_RLS_Vorfeldhelligkeit_Boost_Cxf_bis_6428_Lux)}, range raw 0..15, to SAM(timeout 3.5 s)  # erweiterte Helligkeitssensierung für HUD
            signal LS_Helligkeit_IR_XIX_RLSs_01_XIX_E3V_SAM_LIN1: start 24, 8 bit, little-endian, data-type-policy=OVERRIDE, i-signal-type=PRIMITIVE, init-value=254, base-type=BT_LS_Helligkeit_IR, invalid-value=Invalid_LS_Helligkeit_IR_XIX_RLSs_01_XIX_E3V_SAM_LIN1:255, compu {phys=raw*400 for raw 0..253, 254=Cxfe_Init (CM_LS_Helligkeit_IR_Cxfe_Init), 255=Cxff_Fehler (CM_LS_Helligkeit_IR_Cxff_Fehler); unit Unit_Lux}, range phys 0..101200 Unit_Lux, raw 0..255, unit=Unit_Lux, to SAM(timeout 3.5 s)  # Globalfeldhelligkeit
            signal LS_Helligkeit_FW_XIX_RLSs_01_XIX_E3V_SAM_LIN1: start 32, 10 bit, little-endian, data-type-policy=OVERRIDE, i-signal-type=PRIMITIVE, init-value=1022, base-type=BT_LS_Helligkeit_FW, invalid-value=Invalid_LS_Helligkeit_FW_XIX_RLSs_01_XIX_E3V_SAM_LIN1:1023, compu {phys=raw*6 for raw 0..1021, 1022=Cx3fe_Init (CM_LS_Helligkeit_FW_Cx3fe_Init), 1023=Cx3ff_Fehler (CM_LS_Helligkeit_FW_Cx3ff_Fehler); unit Unit_Lux}, range phys 0..6126 Unit_Lux, raw 0..1023, unit=Unit_Lux, to SAM(timeout 3.5 s)  # Vorfeldhelligkeit
            signal ISignalVoid_RLSs_01_XIX_E3V_SAM_LIN1_0: start 42, 2 bit, little-endian, system signal SignalVoid_RLSs_01_0, data-type-policy=OVERRIDE, i-signal-type=PRIMITIVE, base-type=BT_SignalVoid
            signal RS_Regenmenge_XIX_RLSs_01_XIX_E3V_SAM_LIN1: start 44, 4 bit, little-endian, data-type-policy=OVERRIDE, i-signal-type=PRIMITIVE, init-value=14, base-type=BT_RS_Regenmenge, invalid-value=Invalid_RS_Regenmenge_XIX_RLSs_01_XIX_E3V_SAM_LIN1:15, compu {0=Cx0_0 (CM_RS_Regenmenge_Cx0_0), 1=Cx1_0_0_bis_0_3 (CM_RS_Regenmenge_Cx1_0_0_bis_0_3) (0,0_bis_0,3), 2=Cx2_0_31_bis_1_4 (CM_RS_Regenmenge_Cx2_0_31_bis_1_4) (0,31_bis_1,4), 3=Cx3_1_41_bis_2_0 (CM_RS_Regenmenge_Cx3_1_41_bis_2_0) (1,41_bis_2,0), 4=Cx4_2_01_bis_2_8 (CM_RS_Regenmenge_Cx4_2_01_bis_2_8) (2,01_bis_2,8), 5=Cx5_2_81_bis_3_3 (CM_RS_Regenmenge_Cx5_2_81_bis_3_3) (2,81_bis_3,3), 6=Cx6_3_31_bis_4_0 (CM_RS_Regenmenge_Cx6_3_31_bis_4_0) (3,31_bis_4,0), 7=Cx7_4_01_bis_5_0 (CM_RS_Regenmenge_Cx7_4_01_bis_5_0) (4,01_bis_5,0), 8=Cx8_5_01_bis_7_0 (CM_RS_Regenmenge_Cx8_5_01_bis_7_0) (5,01_bis_7,0), 9=Cx9_7_01_bis_9_0 (CM_RS_Regenmenge_Cx9_7_01_bis_9_0) (7,01_bis_9,0), 10=Cxa_9_01_bis_11_0 (CM_RS_Regenmenge_Cxa_9_01_bis_11_0) (9,01_bis_11,0), 11=Cxb_11_01_bis_15_0 (CM_RS_Regenmenge_Cxb_11_01_bis_15_0) (11,01_bis_15,0), 12=Cxc_15_01_bis_22_0 (CM_RS_Regenmenge_Cxc_15_01_bis_22_0) (15,01_bis_22,0), 13=Cxd_22_01 (CM_RS_Regenmenge_Cxd_22_01) (>22,01), 14=Cxe_Init (CM_RS_Regenmenge_Cxe_Init), 15=Cxf_Fehler (CM_RS_Regenmenge_Cxf_Fehler)}, range raw 0..15, to SAM(timeout 3.5 s)  # Regenmenge
            signal ISignalVoid_RLSs_01_XIX_E3V_SAM_LIN1_1: start 48, 8 bit, little-endian, system signal SignalVoid_RLSs_01_1, data-type-policy=OVERRIDE, i-signal-type=PRIMITIVE, base-type=BT_SignalVoid
            signal RLS_CRC_XIX_RLSs_01_XIX_E3V_SAM_LIN1: start 56, 8 bit, little-endian, data-type-policy=OVERRIDE, i-signal-type=PRIMITIVE, base-type=BT_RLS_CRC, compu {phys=raw for raw 0..255}, range phys 0..255, raw 0..255, to SAM(timeout 3.5 s)  # Für MLB: Berechnung siehe Lastenheft "Kommunikationsabsicherung für FlexRay und CAN" Ab MQB und MLBevo: Berechnung siehe Lastenheft "End-to-End Kommunikationsabsicherung" Endwerte siehe Begleitdokument "S-PDU Kennungsfolgen"
            mapping SG_RLSs_01_XIX_E3V_SAM_LIN1: i-signal-group=SG_RLSs_01_XIX_E3V_SAM_LIN1, transfer-property=TRIGGERED-WITHOUT-REPETITION
        frame SlaveResp_XIX_E3V_SAM_LIN1: id 0x3D, to SAM, frame-length=8, lin-checksum=CLASSIC
          n pdu SlaveResp_XIX_E3V_SAM_LIN1: length=8
        frame SoSes_01_XIX_E3V_SAM_LIN1: id 0x30, to SAM, frame-length=8, lin-checksum=ENHANCED
          pdu SoSes_01_XIX_E3V_SAM_LIN1: length=8, unused-bit-pattern=0
            signal SoSe_SunInt_2D_Li_XIX_SoSes_01_XIX_E3V_SAM_LIN1: start 0, 8 bit, little-endian, data-type-policy=OVERRIDE, i-signal-type=PRIMITIVE, init-value=254, base-type=BT_SoSe_SunInt_2D_Li, invalid-value=Invalid_SoSe_SunInt_2D_Li_XIX_SoSes_01_XIX_E3V_SAM_LIN1:255, compu {phys=raw*5 for raw 0..240, 254=Cxfe_Init (CM_SoSe_SunInt_2D_Li_Cxfe_Init), 255=Cxff_Fehler (CM_SoSe_SunInt_2D_Li_Cxff_Fehler); unit Unit_WattPerMeterSquar}, range phys 0..1200 Unit_WattPerMeterSquar, raw 0..255, unit=Unit_WattPerMeterSquar, transfer-property=PENDING, to SAM(timeout 3.5 s)  # Sonnenintensität links (2D Sensor)
            signal SoSe_SunInt_2D_Re_XIX_SoSes_01_XIX_E3V_SAM_LIN1: start 8, 8 bit, little-endian, data-type-policy=OVERRIDE, i-signal-type=PRIMITIVE, init-value=254, base-type=BT_SoSe_SunInt_2D_Re, invalid-value=Invalid_SoSe_SunInt_2D_Re_XIX_SoSes_01_XIX_E3V_SAM_LIN1:255, compu {phys=raw*5 for raw 0..240, 254=Cxfe_Init (CM_SoSe_SunInt_2D_Re_Cxfe_Init), 255=Cxff_Fehler (CM_SoSe_SunInt_2D_Re_Cxff_Fehler); unit Unit_WattPerMeterSquar}, range phys 0..1200 Unit_WattPerMeterSquar, raw 0..255, unit=Unit_WattPerMeterSquar, transfer-property=PENDING, to SAM(timeout 3.5 s)  # Sonnenintensität rechts (2D Sensor)
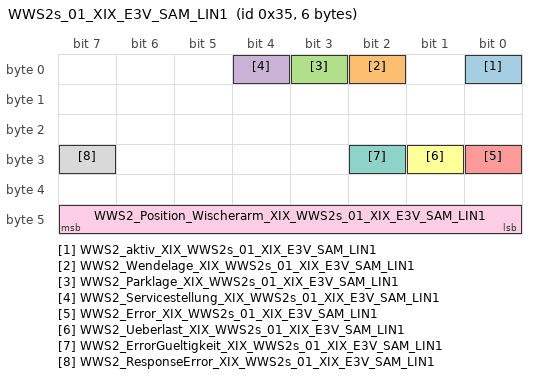
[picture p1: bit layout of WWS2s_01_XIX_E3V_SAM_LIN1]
        frame WWS2s_01_XIX_E3V_SAM_LIN1: id 0x35, to SAM, frame-length=6, lin-checksum=ENHANCED
          pdu WWS2s_01_XIX_E3V_SAM_LIN1: length=6, unused-bit-pattern=0
            signal WWS2_aktiv_XIX_WWS2s_01_XIX_E3V_SAM_LIN1: start 0, 1 bit, little-endian, data-type-policy=OVERRIDE, i-signal-type=PRIMITIVE, init-value=0, base-type=BT_WWS2_aktiv, compu {0=Cx0_inaktiv (CM_WWS2_aktiv_Cx0_inaktiv), 1=Cx1_aktiv (CM_WWS2_aktiv_Cx1_aktiv)}, range raw 0..1, transfer-property=PENDING, to SAM(timeout 3.5 s)  # Wischer 2 ist aktiv
            signal WWS2_Wendelage_XIX_WWS2s_01_XIX_E3V_SAM_LIN1: start 2, 1 bit, little-endian, data-type-policy=OVERRIDE, i-signal-type=PRIMITIVE, init-value=0, base-type=BT_WWS2_Wendelage, compu {0=Cx0_inaktiv (CM_WWS2_Wendelage_Cx0_inaktiv), 1=Cx1_aktiv (CM_WWS2_Wendelage_Cx1_aktiv)}, range raw 0..1, transfer-property=PENDING, to SAM(timeout 3.5 s)  # Wischer 2 in Wendelage
            signal WWS2_Parklage_XIX_WWS2s_01_XIX_E3V_SAM_LIN1: start 3, 1 bit, little-endian, data-type-policy=OVERRIDE, i-signal-type=PRIMITIVE, init-value=0, base-type=BT_WWS2_Parklage, compu {0=Cx0_inaktiv (CM_WWS2_Parklage_Cx0_inaktiv), 1=Cx1_aktiv (CM_WWS2_Parklage_Cx1_aktiv)}, range raw 0..1, transfer-property=PENDING, to SAM(timeout 3.5 s)  # Wischer 2 in Parklage
            signal WWS2_Servicestellung_XIX_WWS2s_01_XIX_E3V_SAM_LIN1: start 4, 1 bit, little-endian, data-type-policy=OVERRIDE, i-signal-type=PRIMITIVE, init-value=0, base-type=BT_WWS2_Servicestellung, compu {0=Cx0_inaktiv (CM_WWS2_Servicestellung_Cx0_inaktiv), 1=Cx1_aktiv (CM_WWS2_Servicestellung_Cx1_aktiv)}, range raw 0..1, transfer-property=PENDING, to SAM(timeout 3.5 s)  # Wischer 2 befindet sich in Servicestellung
            signal WWS2_Error_XIX_WWS2s_01_XIX_E3V_SAM_LIN1: start 24, 1 bit, little-endian, data-type-policy=OVERRIDE, i-signal-type=PRIMITIVE, init-value=0, base-type=BT_WWS2_Error, invalid-value=Invalid_WWS2_Error_XIX_WWS2s_01_XIX_E3V_SAM_LIN1:1, compu {0=Cx0_normal (CM_WWS2_Error_Cx0_normal), 1=Cx1_Fehler (CM_WWS2_Error_Cx1_Fehler)}, range raw 0..1, transfer-property=PENDING, to SAM(timeout 3.5 s)  # Signalisiert den Fehlerzustand "Steuergerät defekt" --> Wischermotor 2 muss getauscht werden.
            signal WWS2_Ueberlast_XIX_WWS2s_01_XIX_E3V_SAM_LIN1: start 25, 1 bit, little-endian, data-type-policy=OVERRIDE, i-signal-type=PRIMITIVE, init-value=0, base-type=BT_WWS2_Ueberlast, invalid-value=Invalid_WWS2_Ueberlast_XIX_WWS2s_01_XIX_E3V_SAM_LIN1:1, compu {0=Cx0_normal (CM_WWS2_Ueberlast_Cx0_normal), 1=Cx1_Fehler (CM_WWS2_Ueberlast_Cx1_Fehler)}, range raw 0..1, transfer-property=PENDING, to SAM(timeout 3.5 s)  # Wischer 2 Überlasterkennung
            signal WWS2_ErrorGueltigkeit_XIX_WWS2s_01_XIX_E3V_SAM_LIN1: start 26, 1 bit, little-endian, data-type-policy=OVERRIDE, i-signal-type=PRIMITIVE, init-value=0, base-type=BT_WWS2_ErrorGueltigkeit, compu {0=Cx0_Fehler_passiv_Fehlerpfad_nicht_durchlaufen (CM_WWS2_ErrorGueltigkeit_Cx0_Fehler_passiv_Fehlerpfad_nicht_durchlaufen) (Fehler_passiv__Fehlerpfad_nicht_durchlaufen), 1=Cx1_Fehler_gueltig_Fehlerpfad_durchlaufen (CM_WWS2_ErrorGueltigkeit_Cx1_Fehler_gueltig_Fehlerpfad_durchlaufen) (Fehler_gueltig__Fehlerpfad_durchlaufen)}, range raw 0..1, transfer-property=PENDING, to SAM(timeout 3.5 s)  # Wischer 2 Error Gültigkeit
            signal WWS2_ResponseError_XIX_WWS2s_01_XIX_E3V_SAM_LIN1: start 31, 1 bit, little-endian, data-type-policy=OVERRIDE, i-signal-type=PRIMITIVE, init-value=0, base-type=BT_WWS2_ResponseError, invalid-value=Invalid_WWS2_ResponseError_XIX_WWS2s_01_XIX_E3V_SAM_LIN1:1, compu {0=Cx0_normal (CM_WWS2_ResponseError_Cx0_normal), 1=Cx1_Fehler (CM_WWS2_ResponseError_Cx1_Fehler)}, range raw 0..1, transfer-property=PENDING, to SAM(timeout 3.5 s)  # siehe LIN2.0-Specification (Darf nicht über ein Fehlergueltigkeitsbit abgesichtert werden!)
            signal WWS2_Position_Wischerarm_XIX_WWS2s_01_XIX_E3V_SAM_LIN1: start 40, 8 bit, little-endian, data-type-policy=OVERRIDE, i-signal-type=PRIMITIVE, init-value=254, base-type=BT_WWS2_Position_Wischerarm, invalid-value=Invalid_WWS2_Position_Wischerarm_XIX_WWS2s_01_XIX_E3V_SAM_LIN1:255, compu {phys=raw*0.5 for raw 0..250, 254=Cxfe_Init (CM_WWS2_Position_Wischerarm_Cxfe_Init), 255=Cxff_Fehler (CM_WWS2_Position_Wischerarm_Cxff_Fehler); unit Unit_DegreOfArc}, range phys 0..125 Unit_DegreOfArc, raw 0..255, unit=Unit_DegreOfArc, transfer-property=PENDING, to SAM(timeout 3.5 s)  # 1 Byte Signal mit dem der LIN Frontwischer 2 die aktuelle Position der Wischerarme auf der Frontscheibe signalisiert.
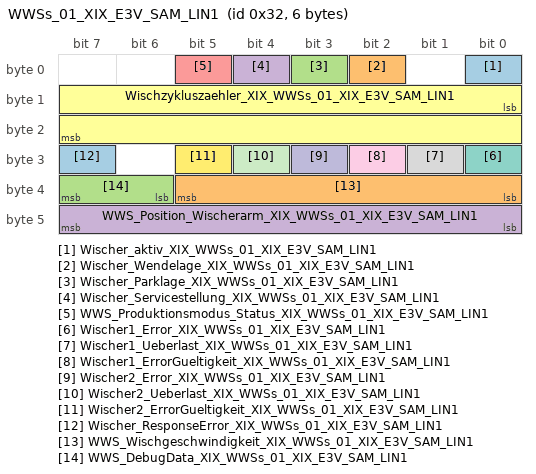
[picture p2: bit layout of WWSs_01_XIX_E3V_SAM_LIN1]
        frame WWSs_01_XIX_E3V_SAM_LIN1: id 0x32, to SAM, frame-length=6, lin-checksum=ENHANCED
          pdu WWSs_01_XIX_E3V_SAM_LIN1: length=6, unused-bit-pattern=0
            signal Wischer_aktiv_XIX_WWSs_01_XIX_E3V_SAM_LIN1: start 0, 1 bit, little-endian, data-type-policy=OVERRIDE, i-signal-type=PRIMITIVE, init-value=0, base-type=BT_Wischer_aktiv, compu {0=Cx0_inaktiv (CM_Wischer_aktiv_Cx0_inaktiv), 1=Cx1_aktiv (CM_Wischer_aktiv_Cx1_aktiv)}, range raw 0..1, transfer-property=PENDING, to SAM(timeout 3.5 s)  # Frontwischermotor aktiv
            signal Wischer_Wendelage_XIX_WWSs_01_XIX_E3V_SAM_LIN1: start 2, 1 bit, little-endian, data-type-policy=OVERRIDE, i-signal-type=PRIMITIVE, init-value=0, base-type=BT_Wischer_Wendelage, compu {0=Cx0_inaktiv (CM_Wischer_Wendelage_Cx0_inaktiv), 1=Cx1_aktiv (CM_Wischer_Wendelage_Cx1_aktiv)}, range raw 0..1, transfer-property=PENDING, to SAM(timeout 3.5 s)  # Status Frontwischermotor Wendelage (zwei Wendelagen vorhanden)
            signal Wischer_Parklage_XIX_WWSs_01_XIX_E3V_SAM_LIN1: start 3, 1 bit, little-endian, data-type-policy=OVERRIDE, i-signal-type=PRIMITIVE, init-value=0, base-type=BT_Wischer_Parklage, compu {0=Cx0_inaktiv (CM_Wischer_Parklage_Cx0_inaktiv), 1=Cx1_aktiv (CM_Wischer_Parklage_Cx1_aktiv)}, range raw 0..1, transfer-property=PENDING, to SAM(timeout 3.5 s)  # Status Frontwischermotor Parklage
            signal Wischer_Servicestellung_XIX_WWSs_01_XIX_E3V_SAM_LIN1: start 4, 1 bit, little-endian, data-type-policy=OVERRIDE, i-signal-type=PRIMITIVE, init-value=0, base-type=BT_Wischer_Servicestellung, compu {0=Cx0_inaktiv (CM_Wischer_Servicestellung_Cx0_inaktiv), 1=Cx1_aktiv (CM_Wischer_Servicestellung_Cx1_aktiv)}, range raw 0..1, transfer-property=PENDING, to SAM(timeout 3.5 s)  # Status Frontwischermotor Serviceposition
            signal WWS_Produktionsmodus_Status_XIX_WWSs_01_XIX_E3V_SAM_LIN1: start 5, 1 bit, little-endian, data-type-policy=OVERRIDE, i-signal-type=PRIMITIVE, base-type=BT_WWS_Produktionsmodus_Status, compu {0=Cx0_Produktionsmodus_inaktiv (CM_WWS_Produktionsmodus_Status_Cx0_Produktionsmodus_inaktiv) (Produktionsmodus inaktiv), 1=Cx1_Produktionsmodus_aktiv (CM_WWS_Produktionsmodus_Status_Cx1_Produktionsmodus_aktiv) (Produktionsmodus aktiv)}, range raw 0..1, transfer-property=PENDING, to SAM(timeout 3.5 s)  # Sendesignal WWS auf LIN1 an Empfänger BCM: Dieses Signal soll in die Slave Response Botschaft LIN1::WWS::WWSs_01 inegriert werden. Mit diesem Signal quittiert der LIN Frontwischer die erfolgreiche Aktivierung des Produktionsmodus über Diagnose/ BCM bzw. meldet den aktuellen Status des Produktionsmodus zurück.
            signal Wischzykluszaehler_XIX_WWSs_01_XIX_E3V_SAM_LIN1: start 8, 16 bit, little-endian, data-type-policy=OVERRIDE, i-signal-type=PRIMITIVE, init-value=0, base-type=BT_Wischzykluszaehler, invalid-value=Invalid_Wischzykluszaehler_XIX_WWSs_01_XIX_E3V_SAM_LIN1:65535, compu {phys=raw*100 for raw 0..65534, 65535=Cxffff_Fehler (CM_Wischzykluszaehler_Cxffff_Fehler); unit Unit_None}, range phys 0..6553400 Unit_None, raw 0..65535, unit=Unit_None, transfer-property=PENDING, to SAM(timeout 3.5 s)
            signal Wischer1_Error_XIX_WWSs_01_XIX_E3V_SAM_LIN1: start 24, 1 bit, little-endian, data-type-policy=OVERRIDE, i-signal-type=PRIMITIVE, init-value=0, base-type=BT_Wischer1_Error, invalid-value=Invalid_Wischer1_Error_XIX_WWSs_01_XIX_E3V_SAM_LIN1:1, compu {0=Cx0_normal (CM_Wischer1_Error_Cx0_normal), 1=Cx1_Fehler (CM_Wischer1_Error_Cx1_Fehler)}, range raw 0..1, transfer-property=PENDING, to SAM(timeout 3.5 s)  # Frontwischermotor 1 Fehler
            signal Wischer1_Ueberlast_XIX_WWSs_01_XIX_E3V_SAM_LIN1: start 25, 1 bit, little-endian, data-type-policy=OVERRIDE, i-signal-type=PRIMITIVE, init-value=0, base-type=BT_Wischer1_Ueberlast, invalid-value=Invalid_Wischer1_Ueberlast_XIX_WWSs_01_XIX_E3V_SAM_LIN1:1, compu {0=Cx0_normal (CM_Wischer1_Ueberlast_Cx0_normal), 1=Cx1_Fehler (CM_Wischer1_Ueberlast_Cx1_Fehler)}, range raw 0..1, transfer-property=PENDING, to SAM(timeout 3.5 s)  # Frontwischermotor 1 Mechanische Überlast
            signal Wischer1_ErrorGueltigkeit_XIX_WWSs_01_XIX_E3V_SAM_LIN1: start 26, 1 bit, little-endian, data-type-policy=OVERRIDE, i-signal-type=PRIMITIVE, init-value=0, base-type=BT_Wischer1_ErrorGueltigkeit, compu {0=Cx0_Fehler_passiv_Fehlerpfad_nicht_durchlaufen (CM_Wischer1_ErrorGueltigkeit_Cx0_Fehler_passiv_Fehlerpfad_nicht_durchlaufen) (Fehler_passiv__Fehlerpfad_nicht_durchlaufen), 1=Cx1_Fehler_gueltig_Fehlerpfad_durchlaufen (CM_Wischer1_ErrorGueltigkeit_Cx1_Fehler_gueltig_Fehlerpfad_durchlaufen) (Fehler_gueltig__Fehlerpfad_durchlaufen)}, range raw 0..1, transfer-property=PENDING, to SAM(timeout 3.5 s)
            signal Wischer2_Error_XIX_WWSs_01_XIX_E3V_SAM_LIN1: start 27, 1 bit, little-endian, data-type-policy=OVERRIDE, i-signal-type=PRIMITIVE, init-value=0, base-type=BT_Wischer2_Error, invalid-value=Invalid_Wischer2_Error_XIX_WWSs_01_XIX_E3V_SAM_LIN1:1, compu {0=Cx0_normal (CM_Wischer2_Error_Cx0_normal), 1=Cx1_Fehler (CM_Wischer2_Error_Cx1_Fehler)}, range raw 0..1, transfer-property=PENDING, to SAM(timeout 3.5 s)  # Frontwischermotor 1 Fehler
            signal Wischer2_Ueberlast_XIX_WWSs_01_XIX_E3V_SAM_LIN1: start 28, 1 bit, little-endian, data-type-policy=OVERRIDE, i-signal-type=PRIMITIVE, init-value=0, base-type=BT_Wischer2_Ueberlast, invalid-value=Invalid_Wischer2_Ueberlast_XIX_WWSs_01_XIX_E3V_SAM_LIN1:1, compu {0=Cx0_normal (CM_Wischer2_Ueberlast_Cx0_normal), 1=Cx1_Fehler (CM_Wischer2_Ueberlast_Cx1_Fehler)}, range raw 0..1, transfer-property=PENDING, to SAM(timeout 3.5 s)  # Frontwischermotor 2 Mechanische Überlast
            signal Wischer2_ErrorGueltigkeit_XIX_WWSs_01_XIX_E3V_SAM_LIN1: start 29, 1 bit, little-endian, data-type-policy=OVERRIDE, i-signal-type=PRIMITIVE, init-value=0, base-type=BT_Wischer2_ErrorGueltigkeit, compu {0=Cx0_Fehler_passiv_Fehlerpfad_nicht_durchlaufen (CM_Wischer2_ErrorGueltigkeit_Cx0_Fehler_passiv_Fehlerpfad_nicht_durchlaufen) (Fehler_passiv__Fehlerpfad_nicht_durchlaufen), 1=Cx1_Fehler_gueltig_Fehlerpfad_durchlaufen (CM_Wischer2_ErrorGueltigkeit_Cx1_Fehler_gueltig_Fehlerpfad_durchlaufen) (Fehler_gueltig__Fehlerpfad_durchlaufen)}, range raw 0..1, transfer-property=PENDING, to SAM(timeout 3.5 s)
            signal Wischer_ResponseError_XIX_WWSs_01_XIX_E3V_SAM_LIN1: start 31, 1 bit, little-endian, data-type-policy=OVERRIDE, i-signal-type=PRIMITIVE, init-value=0, base-type=BT_Wischer_ResponseError, invalid-value=Invalid_Wischer_ResponseError_XIX_WWSs_01_XIX_E3V_SAM_LIN1:1, compu {0=Cx0_normal (CM_Wischer_ResponseError_Cx0_normal), 1=Cx1_Fehler (CM_Wischer_ResponseError_Cx1_Fehler)}, range raw 0..1, transfer-property=PENDING, to SAM(timeout 3.5 s)  # siehe LIN2.0-Specification (Darf nicht über ein Fehlergueltigkeitsbit abgesichtert werden!)
            signal WWS_Wischgeschwindigkeit_XIX_WWSs_01_XIX_E3V_SAM_LIN1: start 32, 6 bit, little-endian, data-type-policy=OVERRIDE, i-signal-type=PRIMITIVE, init-value=62, base-type=BT_WWS_Wischgeschwindigkeit, invalid-value=Invalid_WWS_Wischgeschwindigkeit_XIX_WWSs_01_XIX_E3V_SAM_LIN1:63, compu {0=Cx0_Null_Zyklen_pro_min (CM_WWS_Wischgeschwindigkeit_Cx0_Null_Zyklen_pro_min), phys=raw+9 for raw 1..61, 62=Cx3e_Init (CM_WWS_Wischgeschwindigkeit_Cx3e_Init), 63=Cx3f_Fehler (CM_WWS_Wischgeschwindigkeit_Cx3f_Fehler); unit Unit_MinutInver}, range phys 10..70 Unit_MinutInver, raw 0..63, unit=Unit_MinutInver, transfer-property=PENDING, to SAM(timeout 3.5 s)  # aktuelle, durch Wischer vorgegebene Wischgeschwindigkeit in Zyklen / Minute
            signal WWS_DebugData_XIX_WWSs_01_XIX_E3V_SAM_LIN1: start 38, 2 bit, little-endian, data-type-policy=OVERRIDE, i-signal-type=PRIMITIVE, init-value=0, base-type=BT_WWS_DebugData, compu {0=Cx0_Init (CM_WWS_DebugData_Cx0_Init)}, range raw 0, transfer-property=PENDING, to SAM(timeout 3.5 s)  # Debug-Bits zur besseren Fehlerauswertung
            signal WWS_Position_Wischerarm_XIX_WWSs_01_XIX_E3V_SAM_LIN1: start 40, 8 bit, little-endian, data-type-policy=OVERRIDE, i-signal-type=PRIMITIVE, init-value=254, base-type=BT_WWS_Position_Wischerarm, invalid-value=Invalid_WWS_Position_Wischerarm_XIX_WWSs_01_XIX_E3V_SAM_LIN1:255, compu {phys=raw*0.5 for raw 0..250, 254=Cxfe_Init (CM_WWS_Position_Wischerarm_Cxfe_Init), 255=Cxff_Fehler (CM_WWS_Position_Wischerarm_Cxff_Fehler); unit Unit_DegreOfArc}, range phys 0..125 Unit_DegreOfArc, raw 0..255, unit=Unit_DegreOfArc, transfer-property=PENDING, to SAM(timeout 3.5 s)  # 1 Byte Signal mit dem der LIN Frontwischer die aktuelle Position der Wischerarme auf der Frontscheibe signalisiert.
        pdu triggering PT_E3V_SAM_LIN1_XIX_TPCHType_LIN_Diagnose_XIX_0x0_XIX_0x2_XIX_Physical: pdu=DCM_E3V_SAM_LIN1_XIX_TPCHType_LIN_Diagnose_XIX_0x0_XIX_0x2_XIX_Physical, from SAM
        pdu triggering PT_E3V_SAM_LIN1_XIX_TPCHType_LIN_Diagnose_XIX_0x0_XIX_0x59_XIX_Physical: pdu=DCM_E3V_SAM_LIN1_XIX_TPCHType_LIN_Diagnose_XIX_0x0_XIX_0x59_XIX_Physical, from SAM
        pdu triggering PT_E3V_SAM_LIN1_XIX_TPCHType_LIN_Diagnose_XIX_0x0_XIX_0xB_XIX_Physical: pdu=DCM_E3V_SAM_LIN1_XIX_TPCHType_LIN_Diagnose_XIX_0x0_XIX_0xB_XIX_Physical, from SAM
        pdu triggering PT_E3V_SAM_LIN1_XIX_TPCHType_LIN_Diagnose_XIX_0x2_XIX_0x0_XIX_Physical: pdu=DCM_E3V_SAM_LIN1_XIX_TPCHType_LIN_Diagnose_XIX_0x2_XIX_0x0_XIX_Physical, to SAM
        pdu triggering PT_E3V_SAM_LIN1_XIX_TPCHType_LIN_Diagnose_XIX_0x59_XIX_0x0_XIX_Physical: pdu=DCM_E3V_SAM_LIN1_XIX_TPCHType_LIN_Diagnose_XIX_0x59_XIX_0x0_XIX_Physical, to SAM
        pdu triggering PT_E3V_SAM_LIN1_XIX_TPCHType_LIN_Diagnose_XIX_0xB_XIX_0x0_XIX_Physical: pdu=DCM_E3V_SAM_LIN1_XIX_TPCHType_LIN_Diagnose_XIX_0xB_XIX_0x0_XIX_Physical, to SAM
        5 x lin schedule table, all with resume-position=CONTINUE-AT-IT-POSITION:
          DiagRequest: run-mode=RUN-ONCE, application-entry{delay=0.01, position-in-table=0, frame-triggering=CHNL/FT_MasterReq}
          DiagResponse: run-mode=RUN-ONCE, application-entry{delay=0.01, position-in-table=0, frame-triggering=CHNL/FT_SlaveResp}
          FlashRequest: run-mode=RUN-ONCE, application-entry{delay=0.01, position-in-table=0, frame-triggering=CHNL/FT_MasterReq}
          FlashResponse: run-mode=RUN-CONTINUOUS, application-entry{delay=0.01, position-in-table=0, frame-triggering=CHNL/FT_SlaveResp}
          st_main: run-mode=RUN-CONTINUOUS
            table-entrys:
              delay=0.01, position-in-table=0, frame-triggering=FT_BCM1_LIN1_01
              delay=0.02, position-in-table=1, frame-triggering=FT_WWSs_01
              delay=0.02, position-in-table=2, frame-triggering=FT_RLSs_01
              delay=0.01, position-in-table=3, frame-triggering=FT_WWS2s_01
              delay=0.02, position-in-table=4, frame-triggering=CHNL/FT_FSs_01
              delay=0.01, position-in-table=5, frame-triggering=FT_BCM1_LIN1_01
              delay=0.02, position-in-table=6, frame-triggering=FT_WWSs_01
              delay=0.02, position-in-table=7, frame-triggering=FT_RLSs_01
              delay=0.01, position-in-table=8, frame-triggering=FT_WWS2s_01
              delay=0.02, position-in-table=9, frame-triggering=FT_SoSes_01
    E3V_SAM_LIN6
      lin physical channel CHNL: comm-connectors=CN_E3V_SAM_LIN6
        frame GRA_ACCs_01_XIX_E3V_SAM_LIN6: id 0xF, to SAM, frame-length=8, lin-checksum=ENHANCED
          pdu GRA_ACCs_01_XIX_E3V_SAM_LIN6: length=8, unused-bit-pattern=0
            signal GRA_ACC_01_CRC_XIX_GRA_ACCs_01_XIX_E3V_SAM_LIN6: start 0, 8 bit, little-endian, data-type-policy=OVERRIDE, i-signal-type=PRIMITIVE, base-type=BT_GRA_ACC_01_CRC, compu {phys=raw for raw 0..255}, range phys 0..255, raw 0..255, transfer-property=PENDING  # Für MLB: "Berechnung siehe Lastenheft "Kommunikationsabsicherung für FlexRay und CAN"" Ab MQB und MLBevo: "Berechnung siehe Lastenheft "End-to-End Kommunikationsabsicherung"" Endwerte siehe Begleitdokument "S-PDU Kennungsfolgen"
            signal GRA_ACC_01_BZ_XIX_GRA_ACCs_01_XIX_E3V_SAM_LIN6: start 8, 4 bit, little-endian, data-type-policy=OVERRIDE, i-signal-type=PRIMITIVE, base-type=BT_GRA_ACC_01_BZ, compu {phys=raw for raw 0..15}, range phys 0..15, raw 0..15, transfer-property=PENDING  # 4bit Botschaftszaehler, wird mit jeder Sendebotschaft inkrementiert
            signal GRA_Hauptschalter_XIX_GRA_ACCs_01_XIX_E3V_SAM_LIN6: start 12, 1 bit, little-endian, data-type-policy=OVERRIDE, i-signal-type=PRIMITIVE, init-value=0, base-type=BT_GRA_Hauptschalter, compu {0=Cx0_Aus_Taster_nicht_betaetigt (CM_GRA_Hauptschalter_Cx0_Aus_Taster_nicht_betaetigt), 1=Cx1_Ein_Taster_betaetigt (CM_GRA_Hauptschalter_Cx1_Ein_Taster_betaetigt)}, range raw 0..1, transfer-property=PENDING  # Stellung des GRA/ACC-Hauptschalters: Bei gerastetem Hauptschalter: 0: Hauptschalter aus 1: Hauptschalter ein Bei getastetem Hauptschalter: 0: Taster nicht betätigt 1: Taster betätigt
            signal GRA_Abbrechen_XIX_GRA_ACCs_01_XIX_E3V_SAM_LIN6: start 13, 1 bit, little-endian, data-type-policy=OVERRIDE, i-signal-type=PRIMITIVE, init-value=0, base-type=BT_GRA_Abbrechen, compu {0=Cx0_nicht_betaetigt (CM_GRA_Abbrechen_Cx0_nicht_betaetigt), 1=Cx1_betaetigt (CM_GRA_Abbrechen_Cx1_betaetigt)}, range raw 0..1, transfer-property=PENDING  # GRA : aus mit speichern ACC : Soft aus
            signal GRA_Typ_Hauptschalter_XIX_GRA_ACCs_01_XIX_E3V_SAM_LIN6: start 14, 1 bit, little-endian, data-type-policy=OVERRIDE, i-signal-type=PRIMITIVE, base-type=BT_GRA_Typ_Hauptschalter, compu {0=Cx0_gerasteter_Lenkstockschalter (CM_GRA_Typ_Hauptschalter_Cx0_gerasteter_Lenkstockschalter), 1=Cx1_getasteter_Lenkstockschalter (CM_GRA_Typ_Hauptschalter_Cx1_getasteter_Lenkstockschalter)}, range raw 0..1, transfer-property=PENDING  # Variante des GRA/ACC-Hauptschalters: 0: gerasteter Hauptschalter (bzw. Taster mit Speicherung des Status im SMLS (PAG)) 1: getasteter Hauptschalter, keine Speicherung des Status im SMLS
            signal GRA_Limiter_XIX_GRA_ACCs_01_XIX_E3V_SAM_LIN6: start 15, 1 bit, little-endian, data-type-policy=OVERRIDE, i-signal-type=PRIMITIVE, init-value=0, base-type=BT_GRA_Limiter, compu {0=Cx0_nicht_betaetigt (CM_GRA_Limiter_Cx0_nicht_betaetigt), 1=Cx1_betaetigt (CM_GRA_Limiter_Cx1_betaetigt)}, range raw 0..1, transfer-property=PENDING  # Stellung des Limiter-Tasters
            signal GRA_Tip_Setzen_XIX_GRA_ACCs_01_XIX_E3V_SAM_LIN6: start 16, 1 bit, little-endian, data-type-policy=OVERRIDE, i-signal-type=PRIMITIVE, init-value=0, base-type=BT_GRA_Tip_Setzen, compu {0=Cx0_nicht_betaetigt (CM_GRA_Tip_Setzen_Cx0_nicht_betaetigt), 1=Cx1_betaetigt (CM_GRA_Tip_Setzen_Cx1_betaetigt)}, range raw 0..1, transfer-property=PENDING  # Tippschalter Set
            signal GRA_Tip_Hoch_XIX_GRA_ACCs_01_XIX_E3V_SAM_LIN6: start 17, 1 bit, little-endian, data-type-policy=OVERRIDE, i-signal-type=PRIMITIVE, init-value=0, base-type=BT_GRA_Tip_Hoch, compu {0=Cx0_nicht_betaetigt (CM_GRA_Tip_Hoch_Cx0_nicht_betaetigt), 1=Cx1_betaetigt (CM_GRA_Tip_Hoch_Cx1_betaetigt)}, range raw 0..1, transfer-property=PENDING  # Tippschalter Tip Up / Geschwindigkeit erhöhen
            signal GRA_Tip_Runter_XIX_GRA_ACCs_01_XIX_E3V_SAM_LIN6: start 18, 1 bit, little-endian, data-type-policy=OVERRIDE, i-signal-type=PRIMITIVE, init-value=0, base-type=BT_GRA_Tip_Runter, compu {0=Cx0_nicht_betaetigt (CM_GRA_Tip_Runter_Cx0_nicht_betaetigt), 1=Cx1_betaetigt (CM_GRA_Tip_Runter_Cx1_betaetigt)}, range raw 0..1, transfer-property=PENDING  # Tippschalter Tip Down / Geschwindigkeit reduzieren
            signal GRA_Tip_Wiederaufnahme_XIX_GRA_ACCs_01_XIX_E3V_SAM_LIN6: start 19, 1 bit, little-endian, data-type-policy=OVERRIDE, i-signal-type=PRIMITIVE, init-value=0, base-type=BT_GRA_Tip_Wiederaufnahme, compu {0=Cx0_nicht_betaetigt (CM_GRA_Tip_Wiederaufnahme_Cx0_nicht_betaetigt), 1=Cx1_betaetigt (CM_GRA_Tip_Wiederaufnahme_Cx1_betaetigt)}, range raw 0..1, transfer-property=PENDING  # Tippschalter Wiederaufnahme
            signal GRA_Verstellung_Zeitluecke_XIX_GRA_ACCs_01_XIX_E3V_SAM_LIN6: start 20, 2 bit, little-endian, data-type-policy=OVERRIDE, i-signal-type=PRIMITIVE, init-value=0, base-type=BT_GRA_Verstellung_Zeitluecke, compu {0=Cx0_Taste_nicht_betaetigt (CM_GRA_Verstellung_Zeitluecke_Cx0_Taste_nicht_betaetigt), 1=Cx1_Dist_minus_1 (CM_GRA_Verstellung_Zeitluecke_Cx1_Dist_minus_1), 2=Cx2_Dist_plus_1 (CM_GRA_Verstellung_Zeitluecke_Cx2_Dist_plus_1), 3=Cx3_Dist_Toggle (CM_GRA_Verstellung_Zeitluecke_Cx3_Dist_Toggle)}, range raw 0..3, transfer-property=PENDING  # Verstellung der Zeitlücke für ACC DIST -1 = Zeitluecke um 1 Stufe kleiner DIST +1 = Zeitluecke um 1 Stufe groeßer DIST Toggle = Zeitlücke um 1 Stufe kleiner, von kleinster Stufe auf größte Stufe
            signal GRA_Codierung_XIX_GRA_ACCs_01_XIX_E3V_SAM_LIN6: start 22, 2 bit, little-endian, data-type-policy=OVERRIDE, i-signal-type=PRIMITIVE, init-value=0, base-type=BT_GRA_Codierung, compu {0=Cx0_kein_Hebel (CM_GRA_Codierung_Cx0_kein_Hebel), 1=Cx1_GRA_Hebel (CM_GRA_Codierung_Cx1_GRA_Hebel), 2=Cx2_ACC_Hebel (CM_GRA_Codierung_Cx2_ACC_Hebel), 3=Cx3_Limiter_Only (CM_GRA_Codierung_Cx3_Limiter_Only)}, range raw 0..3, transfer-property=PENDING  # Das Signal zeigt an, ob das Sende-SG (SMLS/MFL) auf GRA- oder ACC-Bedienteil codiert ist: 0: kein GRA- oder ACC Bedienteil 1: GRA-Bedienteil 2: ACC-Bedienteil 3: Limiter_Only-Bedienteil
            signal GRA_Fehler_XIX_GRA_ACCs_01_XIX_E3V_SAM_LIN6: start 24, 1 bit, little-endian, data-type-policy=OVERRIDE, i-signal-type=PRIMITIVE, init-value=0, base-type=BT_GRA_Fehler, invalid-value=Invalid_GRA_Fehler_XIX_GRA_ACCs_01_XIX_E3V_SAM_LIN6:1, compu {0=Cx0_kein_Fehler (CM_GRA_Fehler_Cx0_kein_Fehler), 1=Cx1_Fehler (CM_GRA_Fehler_Cx1_Fehler)}, range raw 0..1, transfer-property=PENDING  # Das Signal zeigt an, dass das Sende-SG (SMLS/MFG) einen Defekt des GRA-Bedienteils erkannt hat und hierzu ein FSPE abgelegt wurde.
            signal GRA_LIM_Taste_verfuegbar_XIX_GRA_ACCs_01_XIX_E3V_SAM_LIN6: start 25, 1 bit, little-endian, data-type-policy=OVERRIDE, i-signal-type=PRIMITIVE, base-type=BT_GRA_LIM_Taste_verfuegbar, compu {0=Cx0_Limiter_Taste_nicht_vorhanden (CM_GRA_LIM_Taste_verfuegbar_Cx0_Limiter_Taste_nicht_vorhanden), 1=Cx1_Limiter_Taste_vorhanden (CM_GRA_LIM_Taste_verfuegbar_Cx1_Limiter_Taste_vorhanden)}, range raw 0..1, transfer-property=PENDING  # Das Signal zeigt an, ob eine Limiter-Umschalttaste am jeweiligen GRA/ACC-Bedienelement vorhanden ist.
            signal GRA_Tip_Stufe_2_XIX_GRA_ACCs_01_XIX_E3V_SAM_LIN6: start 26, 1 bit, little-endian, data-type-policy=OVERRIDE, i-signal-type=PRIMITIVE, init-value=0, base-type=BT_GRA_Tip_Stufe_2, compu {0=Cx0_Tip_Stufe_1_keine_Betaetigung (CM_GRA_Tip_Stufe_2_Cx0_Tip_Stufe_1_keine_Betaetigung), 1=Cx1_Tip_Stufe_2 (CM_GRA_Tip_Stufe_2_Cx1_Tip_Stufe_2)}, range raw 0..1, transfer-property=PENDING  # Signal zeigt an, dass der zweistufige GRA/ACC-Hebel (8_Positions_Bedienteil) in der 2. Tip-Stufe betätigt wird. Das Signal wird nur gleichzeitig mit dem Signal GRA_Tip_Hoch oder GRA_Tip_Runter gesetzt, wobei die Bits GRA_Tip_Hoch bzw. GRA_Tip_Runter die Richtung der Hebelbetätigung anzeigen und der Status von GRA_Tip_Stufe_2 kennzeichnet, ob die Betätigung in der ersten oder zweiten Tip-Stufe erfolgt. 0 = Tip_Stufe_1 oder keine Betätigung 1 = Tip_Stufe_2
            signal GRA_Typ_Bedienteil_XIX_GRA_ACCs_01_XIX_E3V_SAM_LIN6: start 27, 3 bit, little-endian, data-type-policy=OVERRIDE, i-signal-type=PRIMITIVE, init-value=0, base-type=BT_GRA_Typ_Bedienteil, compu {0=Cx0_Init (CM_GRA_Typ_Bedienteil_Cx0_Init), 1=Cx1_4_Positions_Bedienteil (CM_GRA_Typ_Bedienteil_Cx1_4_Positions_Bedienteil), 2=Cx2_6_Positions_Bedienteil (CM_GRA_Typ_Bedienteil_Cx2_6_Positions_Bedienteil), 3=Cx3_8_Positions_Bedienteil (CM_GRA_Typ_Bedienteil_Cx3_8_Positions_Bedienteil), 4=Cx4_PAG_5_Positions_Bedienteil (CM_GRA_Typ_Bedienteil_Cx4_PAG_5_Positions_Bedienteil), 5=Cx5_VW_MFL_Gen2 (CM_GRA_Typ_Bedienteil_Cx5_VW_MFL_Gen2), 6=Cx6_VW_MFL_Gen3 (CM_GRA_Typ_Bedienteil_Cx6_VW_MFL_Gen3), 7=Cx7_PAG_DX1_Bedienteil (CM_GRA_Typ_Bedienteil_Cx7_PAG_DX1_Bedienteil)}, range raw 0..7, transfer-property=PENDING  # Das Signal kennzeichnet die Variante des GRA/ACC-Bedienteils: 0: Init 1: 4-Positionen-Bedienteil (z.B. GRA im Blinkerhebel) 2: 6-Positionen-Bedienteil (GRA/ACC-Bedienteil mit separaten Stellungen für Set/Resume/TipUp/TipDown) 3: 8-Positionen-Bedienteil: wie 6-Positionen-Bedienteil, jedoch mit zweistufiger TipUp- und TipDown-Position 4: Porsche 5-Positionen Bedienteil (ohne Setzen-Taste) 5: VW MFL Generation 2 6: VW MFL Generation 3 (zweistufige Geschwindigkeitsverstellung) 7: Porsche DX1.0 Bedienteil (GRA/ACC-Bedienteil ohne separate Set-Taste, ohne Hauptschalter, mit zweistufige TipUp-/TipDown-Position)
            signal GRA_TravelAssist_XIX_GRA_ACCs_01_XIX_E3V_SAM_LIN6: start 30, 1 bit, little-endian, data-type-policy=OVERRIDE, i-signal-type=PRIMITIVE, init-value=0, base-type=BT_GRA_TravelAssist, compu {0=Cx0_nicht_betaetigt (CM_GRA_TravelAssist_Cx0_nicht_betaetigt), 1=Cx1_betaetigt (CM_GRA_TravelAssist_Cx1_betaetigt)}, range raw 0..1, transfer-property=PENDING  # Taste für TravelAssist
            signal GRA_PIT_Limiter_XIX_GRA_ACCs_01_XIX_E3V_SAM_LIN6: start 31, 1 bit, little-endian, data-type-policy=OVERRIDE, i-signal-type=PRIMITIVE, init-value=0, base-type=BT_GRA_PIT_Limiter, compu {0=Cx0_nicht_betaetigt (CM_GRA_PIT_Limiter_Cx0_nicht_betaetigt), 1=Cx1_betaetigt (CM_GRA_PIT_Limiter_Cx1_betaetigt)}, range raw 0..1, transfer-property=PENDING  # Stellung der Taste PIT-Speed-Limiter
            signal GRA_Typ_Bedienteil_erw_XIX_GRA_ACCs_01_XIX_E3V_SAM_LIN6: start 32, 3 bit, little-endian, data-type-policy=OVERRIDE, i-signal-type=PRIMITIVE, init-value=0, base-type=BT_GRA_Typ_Bedienteil_erw, compu {0=Cx0_Init (CM_GRA_Typ_Bedienteil_erw_Cx0_Init), 1=Cx1_MFL_KIS (CM_GRA_Typ_Bedienteil_erw_Cx1_MFL_KIS), 2=Cx2_MFL_KIS_USA (CM_GRA_Typ_Bedienteil_erw_Cx2_MFL_KIS_USA)}, range raw 0..2, transfer-property=PENDING  # Das Signal kennzeichnet die Variante des GRA/ACC-Bedienteils als erweiterte Bedienvariante: "KIS" (Kip IT Simple) Zusätzlich zu dem Signal "GRA_Typ_Bedienteil"
            signal GRA_reserveByte5_3_XIX_GRA_ACCs_01_XIX_E3V_SAM_LIN6: start 35, 5 bit, little-endian, data-type-policy=OVERRIDE, i-signal-type=PRIMITIVE, init-value=0, base-type=BT_GRA_reserveByte5_3, transfer-property=PENDING  # Zweck: Befüllen der reservierten Bitpositionen mit 0 (wg. LIN-Teilnehmer MFL)
            signal GRA_reserveByte6_XIX_GRA_ACCs_01_XIX_E3V_SAM_LIN6: start 40, 8 bit, little-endian, data-type-policy=OVERRIDE, i-signal-type=PRIMITIVE, init-value=0, base-type=BT_GRA_reserveByte6, transfer-property=PENDING  # Zweck: Befüllen der reservierten Bitpositionen mit 0 (wg. LIN-Teilnehmer MFL)
            signal GRA_reserveByte7_XIX_GRA_ACCs_01_XIX_E3V_SAM_LIN6: start 48, 8 bit, little-endian, data-type-policy=OVERRIDE, i-signal-type=PRIMITIVE, init-value=0, base-type=BT_GRA_reserveByte7, transfer-property=PENDING  # Zweck: Befüllen der reservierten Bitpositionen mit 0 (wg. LIN-Teilnehmer MFL)
            signal GRA_reserveByte8_XIX_GRA_ACCs_01_XIX_E3V_SAM_LIN6: start 56, 8 bit, little-endian, data-type-policy=OVERRIDE, i-signal-type=PRIMITIVE, init-value=0, base-type=BT_GRA_reserveByte8, transfer-property=PENDING  # Zweck: Befüllen der reservierten Bitpositionen mit 0 (wg. LIN-Teilnehmer MFL)
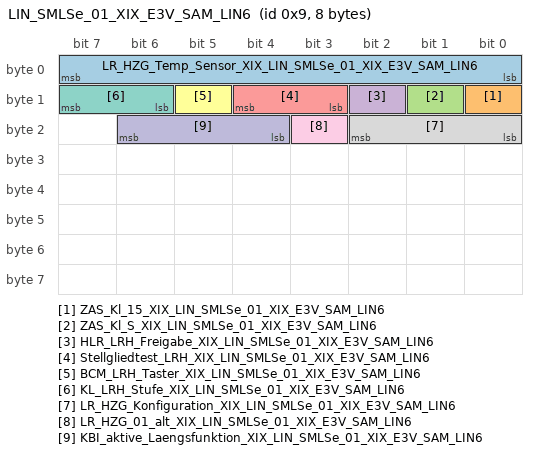
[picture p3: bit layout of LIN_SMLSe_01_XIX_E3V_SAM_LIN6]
        frame LIN_SMLSe_01_XIX_E3V_SAM_LIN6: id 0x9, from SAM, frame-length=8, lin-checksum=ENHANCED
          pdu LIN_SMLSe_01_XIX_E3V_SAM_LIN6: length=8, unused-bit-pattern=0
            signal LR_HZG_Temp_Sensor_XIX_LIN_SMLSe_01_XIX_E3V_SAM_LIN6: start 0, 8 bit, little-endian, data-type-policy=OVERRIDE, i-signal-type=PRIMITIVE, init-value=254, base-type=BT_LR_HZG_Temp_Sensor, compu {phys=raw-50 for raw 0..154, 253=Cxfd_KS_Plus_Unterbrechung (CM_LR_HZG_Temp_Sensor_Cxfd_KS_Plus_Unterbrechung) (KS_Plus__Unterbrechung), 254=Cxfe_Init (CM_LR_HZG_Temp_Sensor_Cxfe_Init), 255=Cxff_Tempsensor_fehlerhaft_KS_GND (CM_LR_HZG_Temp_Sensor_Cxff_Tempsensor_fehlerhaft_KS_GND) (Tempsensor_fehlerhaft__KS_GND); unit Unit_DegreCelsi}, range phys -50..104 Unit_DegreCelsi, raw 0..255, unit=Unit_DegreCelsi, transfer-property=PENDING  # Temperaturwert Lenkradheizung
            signal ZAS_Kl_15_XIX_LIN_SMLSe_01_XIX_E3V_SAM_LIN6: start 8, 1 bit, little-endian, data-type-policy=OVERRIDE, i-signal-type=PRIMITIVE, init-value=0, base-type=BT_ZAS_Kl_15, compu {0=Cx0_aus (CM_ZAS_Kl_15_Cx0_aus), 1=Cx1_ein (CM_ZAS_Kl_15_Cx1_ein)}, range raw 0..1, transfer-property=PENDING  # Klemme 15: Zuendung (SW-Kl.15)
            signal ZAS_Kl_S_XIX_LIN_SMLSe_01_XIX_E3V_SAM_LIN6: start 9, 1 bit, little-endian, data-type-policy=OVERRIDE, i-signal-type=PRIMITIVE, init-value=0, base-type=BT_ZAS_Kl_S, compu {0=Cx0_aus (CM_ZAS_Kl_S_Cx0_aus), 1=Cx1_S_Kontakt_ein (CM_ZAS_Kl_S_Cx1_S_Kontakt_ein)}, range raw 0..1, transfer-property=PENDING  # Klemme S: S-Kontakt (Schluessel steckt)
            signal HLR_LRH_Freigabe_XIX_LIN_SMLSe_01_XIX_E3V_SAM_LIN6: start 10, 1 bit, little-endian, data-type-policy=OVERRIDE, i-signal-type=PRIMITIVE, init-value=0, base-type=BT_HLR_LRH_Freigabe, compu {0=Cx0_keine_Freigabe (CM_HLR_LRH_Freigabe_Cx0_keine_Freigabe), 1=Cx1_Freigabe (CM_HLR_LRH_Freigabe_Cx1_Freigabe)}, range raw 0..1, transfer-property=PENDING  # Freigabe für die Lenkradheizung
            signal Stellgliedtest_LRH_XIX_LIN_SMLSe_01_XIX_E3V_SAM_LIN6: start 11, 2 bit, little-endian, data-type-policy=OVERRIDE, i-signal-type=PRIMITIVE, init-value=0, base-type=BT_Stellgliedtest_LRH, compu {0=Cx0_nicht_angefordert (CM_Stellgliedtest_LRH_Cx0_nicht_angefordert), 1=Cx1_angefordert_Stufe_1 (CM_Stellgliedtest_LRH_Cx1_angefordert_Stufe_1), 2=Cx2_angefordert_Stufe_2 (CM_Stellgliedtest_LRH_Cx2_angefordert_Stufe_2), 3=Cx3_angefordert_Stufe_3 (CM_Stellgliedtest_LRH_Cx3_angefordert_Stufe_3)}, range raw 0..3, transfer-property=PENDING  # Anforderung Stellgliedtest Lenkradheizung
            signal BCM_LRH_Taster_XIX_LIN_SMLSe_01_XIX_E3V_SAM_LIN6: start 13, 1 bit, little-endian, data-type-policy=OVERRIDE, i-signal-type=PRIMITIVE, init-value=0, base-type=BT_BCM_LRH_Taster, compu {0=Cx0_nicht_betaetigt (CM_BCM_LRH_Taster_Cx0_nicht_betaetigt), 1=Cx1_betaetigt (CM_BCM_LRH_Taster_Cx1_betaetigt)}, range raw 0..1, transfer-property=PENDING  # Tasterbetätigung Lenkradheizung aller am BCM eingelesenen Tastersignale
            signal KL_LRH_Stufe_XIX_LIN_SMLSe_01_XIX_E3V_SAM_LIN6: start 14, 2 bit, little-endian, data-type-policy=OVERRIDE, i-signal-type=PRIMITIVE, init-value=1, base-type=BT_KL_LRH_Stufe, compu {0=Cx0_Stufe_niedrig (CM_KL_LRH_Stufe_Cx0_Stufe_niedrig), 1=Cx1_Stufe_mittel (CM_KL_LRH_Stufe_Cx1_Stufe_mittel), 2=Cx2_Stufe_hoch (CM_KL_LRH_Stufe_Cx2_Stufe_hoch), 3=Cx3_AUS (CM_KL_LRH_Stufe_Cx3_AUS)}, range raw 0..3, transfer-property=PENDING  # Eingestellte Temperaturstufe der Lenkradheizung
            signal LR_HZG_Konfiguration_XIX_LIN_SMLSe_01_XIX_E3V_SAM_LIN6: start 16, 3 bit, little-endian, data-type-policy=OVERRIDE, i-signal-type=PRIMITIVE, init-value=0, base-type=BT_LR_HZG_Konfiguration, compu {0=Cx0_Init (CM_LR_HZG_Konfiguration_Cx0_Init), 1=Cx1_Parametersatz_1 (CM_LR_HZG_Konfiguration_Cx1_Parametersatz_1), 2=Cx2_Parametersatz_2 (CM_LR_HZG_Konfiguration_Cx2_Parametersatz_2), 3=Cx3_Parametersatz_3 (CM_LR_HZG_Konfiguration_Cx3_Parametersatz_3), 4=Cx4_Parametersatz_4 (CM_LR_HZG_Konfiguration_Cx4_Parametersatz_4), 5=Cx5_Parametersatz_5 (CM_LR_HZG_Konfiguration_Cx5_Parametersatz_5), 6=Cx6_Parametersatz_6 (CM_LR_HZG_Konfiguration_Cx6_Parametersatz_6), 7=Cx7_Parametersatz_7 (CM_LR_HZG_Konfiguration_Cx7_Parametersatz_7)}, range raw 0..7, transfer-property=PENDING  # Konfiguration der Heizmatte der Lenkradheizung
            signal LR_HZG_01_alt_XIX_LIN_SMLSe_01_XIX_E3V_SAM_LIN6: start 19, 1 bit, little-endian, data-type-policy=OVERRIDE, i-signal-type=PRIMITIVE, init-value=1, base-type=BT_LR_HZG_01_alt, compu {0=Cx0_aktuell (CM_LR_HZG_01_alt_Cx0_aktuell), 1=Cx1_veraltet (CM_LR_HZG_01_alt_Cx1_veraltet)}, range raw 0..1, transfer-property=PENDING
            signal KBI_aktive_Laengsfunktion_XIX_LIN_SMLSe_01_XIX_E3V_SAM_LIN6: start 20, 3 bit, little-endian, data-type-policy=OVERRIDE, i-signal-type=PRIMITIVE, init-value=0, base-type=BT_KBI_aktive_Laengsfunktion, compu {0=Cx0_Init (CM_KBI_aktive_Laengsfunktion_Cx0_Init), 1=Cx1_Speedlimiter (CM_KBI_aktive_Laengsfunktion_Cx1_Speedlimiter), 2=Cx2_GRA_oder_ACC (CM_KBI_aktive_Laengsfunktion_Cx2_GRA_oder_ACC), 3=Cx3_PACCh (CM_KBI_aktive_Laengsfunktion_Cx3_PACCh), 4=Cx4_HDC (CM_KBI_aktive_Laengsfunktion_Cx4_HDC), 5=Cx5_p_GRA (CM_KBI_aktive_Laengsfunktion_Cx5_p_GRA), 6=Cx6_p_Lim (CM_KBI_aktive_Laengsfunktion_Cx6_p_Lim), 7=Cx7_Umschaltung_GRA_Limiter (CM_KBI_aktive_Laengsfunktion_Cx7_Umschaltung_GRA_Limiter)}, range raw 0..7, transfer-property=PENDING  # Auswahl, der vom Fahrer gewünschten Laengsregelfunktion
        frame LIN_SMLSs_01_XIX_E3V_SAM_LIN6: id 0x8, to SAM, frame-length=8, lin-checksum=ENHANCED
          pdu LIN_SMLSs_01_XIX_E3V_SAM_LIN6: length=8, unused-bit-pattern=0
            signal LIN_SMLS_ECU_defekt_XIX_LIN_SMLSs_01_XIX_E3V_SAM_LIN6: start 0, 1 bit, little-endian, data-type-policy=OVERRIDE, i-signal-type=PRIMITIVE, init-value=0, base-type=BT_LIN_SMLS_ECU_defekt, invalid-value=Invalid_LIN_SMLS_ECU_defekt_XIX_LIN_SMLSs_01_XIX_E3V_SAM_LIN6:1, compu {0=Cx0_kein_Fehler (CM_LIN_SMLS_ECU_defekt_Cx0_kein_Fehler), 1=Cx1_Fehler (CM_LIN_SMLS_ECU_defekt_Cx1_Fehler)}, range raw 0..1, transfer-property=PENDING, to SAM(timeout 3.5 s)  # LIN_SMLS ECU defekt
            signal LIN_SMLS_RAM_ROM_Fehler_XIX_LIN_SMLSs_01_XIX_E3V_SAM_LIN6: start 1, 1 bit, little-endian, data-type-policy=OVERRIDE, i-signal-type=PRIMITIVE, init-value=0, base-type=BT_LIN_SMLS_RAM_ROM_Fehler, invalid-value=Invalid_LIN_SMLS_RAM_ROM_Fehler_XIX_LIN_SMLSs_01_XIX_E3V_SAM_LIN6:1, compu {0=Cx0_kein_Fehler (CM_LIN_SMLS_RAM_ROM_Fehler_Cx0_kein_Fehler), 1=Cx1_Fehler (CM_LIN_SMLS_RAM_ROM_Fehler_Cx1_Fehler)}, range raw 0..1, transfer-property=PENDING, to SAM(timeout 3.5 s)  # Im LIN_SMLS liegt ein RAM- oder ROM-Fehler vor.
            signal LIN_SMLS_Ueberspannung_XIX_LIN_SMLSs_01_XIX_E3V_SAM_LIN6: start 2, 1 bit, little-endian, data-type-policy=OVERRIDE, i-signal-type=PRIMITIVE, init-value=0, base-type=BT_LIN_SMLS_Ueberspannung, invalid-value=Invalid_LIN_SMLS_Ueberspannung_XIX_LIN_SMLSs_01_XIX_E3V_SAM_LIN6:1, compu {0=Cx0_kein_Fehler (CM_LIN_SMLS_Ueberspannung_Cx0_kein_Fehler), 1=Cx1_Fehler (CM_LIN_SMLS_Ueberspannung_Cx1_Fehler)}, range raw 0..1, transfer-property=PENDING, to SAM(timeout 3.5 s)  # Funktionseinschränkung im LIN_SMLS durch Überspannung
            signal LIN_SMLS_Unterspannung_XIX_LIN_SMLSs_01_XIX_E3V_SAM_LIN6: start 3, 1 bit, little-endian, data-type-policy=OVERRIDE, i-signal-type=PRIMITIVE, init-value=0, base-type=BT_LIN_SMLS_Unterspannung, invalid-value=Invalid_LIN_SMLS_Unterspannung_XIX_LIN_SMLSs_01_XIX_E3V_SAM_LIN6:1, compu {0=Cx0_kein_Fehler (CM_LIN_SMLS_Unterspannung_Cx0_kein_Fehler), 1=Cx1_Fehler (CM_LIN_SMLS_Unterspannung_Cx1_Fehler)}, range raw 0..1, transfer-property=PENDING, to SAM(timeout 3.5 s)  # Funktionseinschränkung im LIN_SMLS durch Unterspannung
            signal WH_MFA_Fehler_XIX_LIN_SMLSs_01_XIX_E3V_SAM_LIN6: start 4, 1 bit, little-endian, data-type-policy=OVERRIDE, i-signal-type=PRIMITIVE, init-value=0, base-type=BT_WH_MFA_Fehler, invalid-value=Invalid_WH_MFA_Fehler_XIX_LIN_SMLSs_01_XIX_E3V_SAM_LIN6:1, compu {0=Cx0_kein_Fehler (CM_WH_MFA_Fehler_Cx0_kein_Fehler), 1=Cx1_Fehler (CM_WH_MFA_Fehler_Cx1_Fehler)}, range raw 0..1, transfer-property=PENDING, to SAM(timeout 3.5 s)  # Fehlerstatus MFA Tasten
            signal LIN_SMLS_Zaehler_XIX_LIN_SMLSs_01_XIX_E3V_SAM_LIN6: start 8, 4 bit, little-endian, data-type-policy=OVERRIDE, i-signal-type=PRIMITIVE, init-value=0, base-type=BT_LIN_SMLS_Zaehler, compu {phys=raw for raw 0..15; unit Unit_None}, range phys 0..15 Unit_None, raw 0..15, unit=Unit_None, transfer-property=PENDING, to SAM(timeout 3.5 s)  # 4-Bit Aktualisierungszaehler, wird mit jeder Sendebotschaft inkrementiert. (Kommunikationsabsicherung)
            signal BH_Blinker_li_XIX_LIN_SMLSs_01_XIX_E3V_SAM_LIN6: start 12, 1 bit, little-endian, data-type-policy=OVERRIDE, i-signal-type=PRIMITIVE, init-value=0, base-type=BT_BH_Blinker_li, compu {0=Cx0_nicht_betaetigt (CM_BH_Blinker_li_Cx0_nicht_betaetigt), 1=Cx1_Blinkerhebel_Pos_li_betaetigt (CM_BH_Blinker_li_Cx1_Blinkerhebel_Pos_li_betaetigt)}, range raw 0..1, transfer-property=PENDING, to SAM(timeout 3.5 s)  # Blinkerhebel Richtung links
            signal BH_Blinker_re_XIX_LIN_SMLSs_01_XIX_E3V_SAM_LIN6: start 13, 1 bit, little-endian, data-type-policy=OVERRIDE, i-signal-type=PRIMITIVE, init-value=0, base-type=BT_BH_Blinker_re, compu {0=Cx0_nicht_betaetigt (CM_BH_Blinker_re_Cx0_nicht_betaetigt), 1=Cx1_Blinkerhebel_Pos_re_betaetigt (CM_BH_Blinker_re_Cx1_Blinkerhebel_Pos_re_betaetigt)}, range raw 0..1, transfer-property=PENDING, to SAM(timeout 3.5 s)  # Blinkerhebel Richtung rechts
            signal BH_Lichthupe_XIX_LIN_SMLSs_01_XIX_E3V_SAM_LIN6: start 14, 1 bit, little-endian, data-type-policy=OVERRIDE, i-signal-type=PRIMITIVE, init-value=0, base-type=BT_BH_Lichthupe, compu {0=Cx0_nicht_betaetigt (CM_BH_Lichthupe_Cx0_nicht_betaetigt), 1=Cx1_Blinkerhebel_in_Richtung_Lichthupe_betaetigt (CM_BH_Lichthupe_Cx1_Blinkerhebel_in_Richtung_Lichthupe_betaetigt) (Blinkerhebel in Richtung Lichthupe betaetigt)}, range raw 0..1, transfer-property=PENDING, to SAM(timeout 3.5 s)  # Betaetigung Lichthupe
            signal BH_Fernlicht_XIX_LIN_SMLSs_01_XIX_E3V_SAM_LIN6: start 15, 1 bit, little-endian, data-type-policy=OVERRIDE, i-signal-type=PRIMITIVE, init-value=0, base-type=BT_BH_Fernlicht, compu {0=Cx0_nicht_betaetigt (CM_BH_Fernlicht_Cx0_nicht_betaetigt), 1=Cx1_Blinkerhebel_in_Richtung_Fernlicht_betaetigt (CM_BH_Fernlicht_Cx1_Blinkerhebel_in_Richtung_Fernlicht_betaetigt)}, range raw 0..1, transfer-property=PENDING, to SAM(timeout 3.5 s)  # Betaetigung Fernlicht
            signal WH_Tipwischen_XIX_LIN_SMLSs_01_XIX_E3V_SAM_LIN6: start 16, 1 bit, little-endian, data-type-policy=OVERRIDE, i-signal-type=PRIMITIVE, init-value=0, base-type=BT_WH_Tipwischen, compu {0=Cx0_nicht_betaetigt (CM_WH_Tipwischen_Cx0_nicht_betaetigt), 1=Cx1_betaetigt (CM_WH_Tipwischen_Cx1_betaetigt)}, range raw 0..1, transfer-property=PENDING, to SAM(timeout 3.5 s)  # Wischerhebel: Tippwischen MQB A0/ PQ26: Bei Verbau LSS (kein SMLS): gespiegelter Wert zu Signal WH_WischerStufe1
            signal WH_Intervall_XIX_LIN_SMLSs_01_XIX_E3V_SAM_LIN6: start 17, 1 bit, little-endian, data-type-policy=OVERRIDE, i-signal-type=PRIMITIVE, init-value=0, base-type=BT_WH_Intervall, compu {0=Cx0_aus (CM_WH_Intervall_Cx0_aus), 1=Cx1_Wischerhebel_in_Stellung_Intervall (CM_WH_Intervall_Cx1_Wischerhebel_in_Stellung_Intervall) (Wischerhebel in Stellung Intervall)}, range raw 0..1, transfer-property=PENDING, to SAM(timeout 3.5 s)  # Wischerhebel: Stellung Intervall
            signal WH_WischerStufe1_XIX_LIN_SMLSs_01_XIX_E3V_SAM_LIN6: start 18, 1 bit, little-endian, data-type-policy=OVERRIDE, i-signal-type=PRIMITIVE, init-value=0, base-type=BT_WH_WischerStufe1, compu {0=Cx0_aus (CM_WH_WischerStufe1_Cx0_aus), 1=Cx1_Wischerhebel_in_Stufe_Wischen_1 (CM_WH_WischerStufe1_Cx1_Wischerhebel_in_Stufe_Wischen_1) (Wischerhebel in Stufe Wischen 1)}, range raw 0..1, transfer-property=PENDING, to SAM(timeout 3.5 s)  # Wischerhebel: Stufe Wischen 1
            signal WH_WischerStufe2_XIX_LIN_SMLSs_01_XIX_E3V_SAM_LIN6: start 19, 1 bit, little-endian, data-type-policy=OVERRIDE, i-signal-type=PRIMITIVE, init-value=0, base-type=BT_WH_WischerStufe2, compu {0=Cx0_aus (CM_WH_WischerStufe2_Cx0_aus), 1=Cx1_Wischerhebel_in_Stufe_Wischen_2 (CM_WH_WischerStufe2_Cx1_Wischerhebel_in_Stufe_Wischen_2) (Wischerhebel in Stufe Wischen 2)}, range raw 0..1, transfer-property=PENDING, to SAM(timeout 3.5 s)  # Wischerhebel: Stufe Wischen 2
            signal WH_Frontwaschen_XIX_LIN_SMLSs_01_XIX_E3V_SAM_LIN6: start 20, 1 bit, little-endian, data-type-policy=OVERRIDE, i-signal-type=PRIMITIVE, init-value=0, base-type=BT_WH_Frontwaschen, compu {0=Cx0_aus (CM_WH_Frontwaschen_Cx0_aus), 1=Cx1_Wischerhebel_in_Stellung_Wisch_Wasch_vorne (CM_WH_Frontwaschen_Cx1_Wischerhebel_in_Stellung_Wisch_Wasch_vorne) (Wischerhebel in Stellung Wisch Wasch vorne)}, range raw 0..1, transfer-property=PENDING, to SAM(timeout 3.5 s)  # Wischerhebel: Stellung Wisch Wasch vorne
            signal WH_Heckintervall_XIX_LIN_SMLSs_01_XIX_E3V_SAM_LIN6: start 21, 1 bit, little-endian, data-type-policy=OVERRIDE, i-signal-type=PRIMITIVE, init-value=0, base-type=BT_WH_Heckintervall, compu {0=Cx0_nicht_betaetigt (CM_WH_Heckintervall_Cx0_nicht_betaetigt), 1=Cx1_Wischerhebel_in_Stellung_Heckintervall (CM_WH_Heckintervall_Cx1_Wischerhebel_in_Stellung_Heckintervall) (Wischerhebel in Stellung Heckintervall)}, range raw 0..1, transfer-property=PENDING, to SAM(timeout 3.5 s)  # Wischerhebel: Stellung Heckintervall
            signal WH_Heckwaschen_XIX_LIN_SMLSs_01_XIX_E3V_SAM_LIN6: start 22, 1 bit, little-endian, data-type-policy=OVERRIDE, i-signal-type=PRIMITIVE, init-value=0, base-type=BT_WH_Heckwaschen, compu {0=Cx0_nicht_betaetigt (CM_WH_Heckwaschen_Cx0_nicht_betaetigt), 1=Cx1_Wischerhebel_in_Stellung_Wisch_Wasch_hinten (CM_WH_Heckwaschen_Cx1_Wischerhebel_in_Stellung_Wisch_Wasch_hinten) (Wischerhebel in Stellung Wisch Wasch hinten)}, range raw 0..1, transfer-property=PENDING, to SAM(timeout 3.5 s)  # Wischerhebel: Stellung Wisch Wasch hinten
            signal WH_Intervallstufen_XIX_LIN_SMLSs_01_XIX_E3V_SAM_LIN6: start 23, 4 bit, little-endian, data-type-policy=OVERRIDE, i-signal-type=PRIMITIVE, init-value=0, base-type=BT_WH_Intervallstufen, invalid-value=Invalid_WH_Intervallstufen_XIX_LIN_SMLSs_01_XIX_E3V_SAM_LIN6:15, compu {0=Cx0_Init_Default (CM_WH_Intervallstufen_Cx0_Init_Default) (Init / Default), 1=Cx1_Intervallstufe_1 (CM_WH_Intervallstufen_Cx1_Intervallstufe_1) (Intervallstufe 1), 5=Cx5_Intervallstufe_2 (CM_WH_Intervallstufen_Cx5_Intervallstufe_2) (Intervallstufe 2), 9=Cx9_Intervallstufe_3 (CM_WH_Intervallstufen_Cx9_Intervallstufe_3) (Intervallstufe 3), 13=Cxd_Intervallstufe_4 (CM_WH_Intervallstufen_Cxd_Intervallstufe_4) (Intervallstufe 4), 15=Cxf_Fehler (CM_WH_Intervallstufen_Cxf_Fehler)}, range raw 0..15, transfer-property=PENDING, to SAM(timeout 3.5 s)  # Wischerhebel: Stellung Intervallstufen
            signal FAS_Taster_XIX_LIN_SMLSs_01_XIX_E3V_SAM_LIN6: start 27, 1 bit, little-endian, data-type-policy=OVERRIDE, i-signal-type=PRIMITIVE, init-value=0, base-type=BT_FAS_Taster, compu {0=Cx0_nicht_betaetigt (CM_FAS_Taster_Cx0_nicht_betaetigt), 1=Cx1_betaetigt (CM_FAS_Taster_Cx1_betaetigt)}, range raw 0..1, transfer-property=PENDING, to SAM(timeout 3.5 s)  # Betaetigung FAS Taster
            signal FAS_Taster_Fehler_XIX_LIN_SMLSs_01_XIX_E3V_SAM_LIN6: start 28, 1 bit, little-endian, data-type-policy=OVERRIDE, i-signal-type=PRIMITIVE, init-value=0, base-type=BT_FAS_Taster_Fehler, invalid-value=Invalid_FAS_Taster_Fehler_XIX_LIN_SMLSs_01_XIX_E3V_SAM_LIN6:1, compu {0=Cx0_kein_Fehler (CM_FAS_Taster_Fehler_Cx0_kein_Fehler), 1=Cx1_Fehler (CM_FAS_Taster_Fehler_Cx1_Fehler)}, range raw 0..1, transfer-property=PENDING, to SAM(timeout 3.5 s)  # Fehlerstatus FAS Taster
            signal SMLS_Hupe_XIX_LIN_SMLSs_01_XIX_E3V_SAM_LIN6: start 29, 1 bit, little-endian, data-type-policy=OVERRIDE, i-signal-type=PRIMITIVE, init-value=0, base-type=BT_SMLS_Hupe, compu {0=Cx0_nicht_betaetigt (CM_SMLS_Hupe_Cx0_nicht_betaetigt), 1=Cx1_Hupe_gedrueckt (CM_SMLS_Hupe_Cx1_Hupe_gedrueckt)}, range raw 0..1, transfer-property=PENDING, to SAM(timeout 3.5 s)  # Betaetigung Hupe
            signal LRH_On_Off_XIX_LIN_SMLSs_01_XIX_E3V_SAM_LIN6: start 30, 2 bit, little-endian, data-type-policy=OVERRIDE, i-signal-type=PRIMITIVE, init-value=0, base-type=BT_LRH_On_Off, invalid-value=Invalid_LRH_On_Off_XIX_LIN_SMLSs_01_XIX_E3V_SAM_LIN6:3, compu {0=Cx0_LRH_aus_keine_Anzeige (CM_LRH_On_Off_Cx0_LRH_aus_keine_Anzeige) (LRH_aus__keine Anzeige), 1=Cx1_LRH_aus (CM_LRH_On_Off_Cx1_LRH_aus), 2=Cx2_LRH_ein (CM_LRH_On_Off_Cx2_LRH_ein), 3=Cx3_Fehler (CM_LRH_On_Off_Cx3_Fehler)}, range raw 0..3, transfer-property=PENDING, to SAM(timeout 3.5 s)  # Status Lenkradheizung
            signal LSS_Tastencode_XIX_LIN_SMLSs_01_XIX_E3V_SAM_LIN6: start 32, 8 bit, little-endian, data-type-policy=OVERRIDE, i-signal-type=PRIMITIVE, init-value=0, base-type=BT_LSS_Tastencode, compu {0=Cx0_Key_Released_No_Key (CM_LSS_Tastencode_Cx0_Key_Released_No_Key) (Key_Released__No_Key), 4=Cx4_Up (CM_LSS_Tastencode_Cx4_Up), 5=Cx5_Down (CM_LSS_Tastencode_Cx5_Down), 7=Cx7_OK_ThumbWheel_Button (CM_LSS_Tastencode_Cx7_OK_ThumbWheel_Button) (OK__ThumbWheel_Button)}, range raw 0..7, transfer-property=PENDING, to SAM(timeout 3.5 s)  # 0x00 = No key pressed / key released 0x01 = Menu 0x02 = Menu Up / Next Screen 0x03 = Menu Down / Previous Screen 0x04 = Up 0x05 = Down 0x06 = Up / Down ThumbWheel 0x07 = OK (ThumbWheel-Button) 0x08 = Cancel / Escape 0x09..0x0F = reserved for further menu controls 0x10 = Volume Up 0x11 = Volume Down 0x12 = Volume Up / Down ThumbWheel 0x13 = Volume-ThumbWheel-Button 0x14 = Audio Source 0x15 = Arrow A Up / Right 0x16 = Arrow A Down / Left 0x17 = Arrow B Up / Right 0x18 = Arrow B Down / Left 0x19 = PTT (Push To Talk) 0x1A = PTT Cancel 0x1B = Route Info 0x1C = Hook 0x1D = Hang Up 0x1E = Off Hook 0x1F = Light On / Off 0x20 = Mute 0x21 = Joker1 0x22 = Joker2 0x23..0xEF = reserved for further function controls 0xF0 = Startup_Reset
            signal LRH_aktiv_XIX_LIN_SMLSs_01_XIX_E3V_SAM_LIN6: start 40, 1 bit, little-endian, data-type-policy=OVERRIDE, i-signal-type=PRIMITIVE, init-value=0, base-type=BT_LRH_aktiv, compu {0=Cx0_inaktiv (CM_LRH_aktiv_Cx0_inaktiv), 1=Cx1_aktiv (CM_LRH_aktiv_Cx1_aktiv)}, range raw 0..1, transfer-property=PENDING, to SAM(timeout 3.5 s)  # Signal gibt an, ob ein Heizstrom durch die Lenkradheizung fließt. Es dient der Auswertung durch das Energiemanagement.
            signal WH_Wischer_Fehler_XIX_LIN_SMLSs_01_XIX_E3V_SAM_LIN6: start 45, 1 bit, little-endian, data-type-policy=OVERRIDE, i-signal-type=PRIMITIVE, init-value=0, base-type=BT_WH_Wischer_Fehler, invalid-value=Invalid_WH_Wischer_Fehler_XIX_LIN_SMLSs_01_XIX_E3V_SAM_LIN6:1, compu {0=Cx0_kein_Fehler (CM_WH_Wischer_Fehler_Cx0_kein_Fehler), 1=Cx1_Fehler (CM_WH_Wischer_Fehler_Cx1_Fehler)}, range raw 0..1, transfer-property=PENDING, to SAM(timeout 3.5 s)  # Anzeige, ob am Lenkstockschalter ein Fehler anliegt. Notwendig aufgrund ASIL-Einstufung
            signal BH_Blinker_Fehler_XIX_LIN_SMLSs_01_XIX_E3V_SAM_LIN6: start 46, 1 bit, little-endian, data-type-policy=OVERRIDE, i-signal-type=PRIMITIVE, init-value=0, base-type=BT_BH_Blinker_Fehler, invalid-value=Invalid_BH_Blinker_Fehler_XIX_LIN_SMLSs_01_XIX_E3V_SAM_LIN6:1, compu {0=Cx0_kein_Fehler (CM_BH_Blinker_Fehler_Cx0_kein_Fehler), 1=Cx1_Fehler (CM_BH_Blinker_Fehler_Cx1_Fehler)}, range raw 0..1, transfer-property=PENDING, to SAM(timeout 3.5 s)  # Anzeige, ob am Lenkstockschalter ein Fehler anliegt. Notwendig aufgrund ASIL-Einstufung
            signal LRH_Stellglied_aktiv_XIX_LIN_SMLSs_01_XIX_E3V_SAM_LIN6: start 56, 1 bit, little-endian, data-type-policy=OVERRIDE, i-signal-type=PRIMITIVE, init-value=0, base-type=BT_LRH_Stellglied_aktiv, compu {0=Cx0_inaktiv (CM_LRH_Stellglied_aktiv_Cx0_inaktiv), 1=Cx1_aktiv (CM_LRH_Stellglied_aktiv_Cx1_aktiv)}, range raw 0..1, transfer-property=PENDING, to SAM(timeout 3.5 s)  # Rückmeldung Stellglied Lenkradheizung aktiv
            signal LIN_SMLS_ResponseError_XIX_LIN_SMLSs_01_XIX_E3V_SAM_LIN6: start 57, 1 bit, little-endian, data-type-policy=OVERRIDE, i-signal-type=PRIMITIVE, init-value=0, base-type=BT_LIN_SMLS_ResponseError, invalid-value=Invalid_LIN_SMLS_ResponseError_XIX_LIN_SMLSs_01_XIX_E3V_SAM_LIN6:1, compu {0=Cx0_normal (CM_LIN_SMLS_ResponseError_Cx0_normal), 1=Cx1_Fehler (CM_LIN_SMLS_ResponseError_Cx1_Fehler)}, range raw 0..1, transfer-property=PENDING, to SAM(timeout 3.5 s)  # siehe LIN2.0-Specification (Darf nicht über ein Fehlergueltigkeitsbit abgesichtert werden!)
            signal WH_WischerStufe1_invers_XIX_LIN_SMLSs_01_XIX_E3V_SAM_LIN6: start 58, 1 bit, little-endian, data-type-policy=OVERRIDE, i-signal-type=PRIMITIVE, init-value=1, base-type=BT_WH_WischerStufe1_invers, compu {0=Cx0_Wischerhebel_in_Stufe_Wischen_1 (CM_WH_WischerStufe1_invers_Cx0_Wischerhebel_in_Stufe_Wischen_1), 1=Cx1_aus (CM_WH_WischerStufe1_invers_Cx1_aus)}, range raw 0..1, transfer-property=PENDING, to SAM(timeout 3.5 s)  # Inversbit Wischerhebel: Stufe Wischen 1 (Kommunikationsabsicherung)
            signal WH_WischerStufe2_invers_XIX_LIN_SMLSs_01_XIX_E3V_SAM_LIN6: start 59, 1 bit, little-endian, data-type-policy=OVERRIDE, i-signal-type=PRIMITIVE, init-value=1, base-type=BT_WH_WischerStufe2_invers, compu {0=Cx0_Wischerhebel_in_Stufe_Wischen_2 (CM_WH_WischerStufe2_invers_Cx0_Wischerhebel_in_Stufe_Wischen_2), 1=Cx1_aus (CM_WH_WischerStufe2_invers_Cx1_aus)}, range raw 0..1, transfer-property=PENDING, to SAM(timeout 3.5 s)  # Inversbit Wischerhebel: Stufe Wischen 2 (Kommunikationsabsicherung)
            signal BH_Blinker_li_invers_XIX_LIN_SMLSs_01_XIX_E3V_SAM_LIN6: start 60, 1 bit, little-endian, data-type-policy=OVERRIDE, i-signal-type=PRIMITIVE, init-value=1, base-type=BT_BH_Blinker_li_invers, compu {0=Cx0_Blinkerhebel_Richtung_links_betaetigt (CM_BH_Blinker_li_invers_Cx0_Blinkerhebel_Richtung_links_betaetigt), 1=Cx1_nicht_betaetigt (CM_BH_Blinker_li_invers_Cx1_nicht_betaetigt)}, range raw 0..1, transfer-property=PENDING, to SAM(timeout 3.5 s)  # Inversbit Blinkerhebel Richtung links (Kommunikationsabsicherung)
            signal BH_Blinker_re_invers_XIX_LIN_SMLSs_01_XIX_E3V_SAM_LIN6: start 61, 1 bit, little-endian, data-type-policy=OVERRIDE, i-signal-type=PRIMITIVE, init-value=1, base-type=BT_BH_Blinker_re_invers, compu {0=Cx0_Blinkerhebel_Richtung_rechts_betaetigt (CM_BH_Blinker_re_invers_Cx0_Blinkerhebel_Richtung_rechts_betaetigt), 1=Cx1_nicht_betaetigt (CM_BH_Blinker_re_invers_Cx1_nicht_betaetigt)}, range raw 0..1, transfer-property=PENDING, to SAM(timeout 3.5 s)  # Inversbit Blinkerhebel Richtung rechts (Kommunikationsabsicherung)
            signal LIN_SMLS_elektrischer_Fehler_XIX_LIN_SMLSs_01_XIX_E3V_SAM_LIN6: start 62, 1 bit, little-endian, data-type-policy=OVERRIDE, i-signal-type=PRIMITIVE, init-value=0, base-type=BT_LIN_SMLS_elektrischer_Fehler, invalid-value=Invalid_LIN_SMLS_elektrischer_Fehler_XIX_LIN_SMLSs_01_XIX_E3V_SAM_LIN6:1, compu {0=Cx0_kein_Fehler (CM_LIN_SMLS_elektrischer_Fehler_Cx0_kein_Fehler), 1=Cx1_Fehler (CM_LIN_SMLS_elektrischer_Fehler_Cx1_Fehler)}, range raw 0..1, transfer-property=PENDING, to SAM(timeout 3.5 s)  # elektrischer Fehler
            signal LIN_SMLS_mechanischer_Fehler_XIX_LIN_SMLSs_01_XIX_E3V_SAM_LIN6: start 63, 1 bit, little-endian, data-type-policy=OVERRIDE, i-signal-type=PRIMITIVE, init-value=0, base-type=BT_LIN_SMLS_mechanischer_Fehler, invalid-value=Invalid_LIN_SMLS_mechanischer_Fehler_XIX_LIN_SMLSs_01_XIX_E3V_SAM_LIN6:1, compu {0=Cx0_kein_Fehler (CM_LIN_SMLS_mechanischer_Fehler_Cx0_kein_Fehler), 1=Cx1_Fehler (CM_LIN_SMLS_mechanischer_Fehler_Cx1_Fehler)}, range raw 0..1, transfer-property=PENDING, to SAM(timeout 3.5 s)  # mechanischer Fehler
        frame MasterReq_XIX_E3V_SAM_LIN6: id 0x3C, from SAM, frame-length=8, lin-checksum=CLASSIC
          n pdu MasterReq_XIX_E3V_SAM_LIN6: length=8
        frame SlaveResp_XIX_E3V_SAM_LIN6: id 0x3D, to SAM, frame-length=8, lin-checksum=CLASSIC
          n pdu SlaveResp_XIX_E3V_SAM_LIN6: length=8
        pdu triggering PT_E3V_SAM_LIN6_XIX_TPCHType_LIN_Diagnose_XIX_0x0_XIX_0x1C_XIX_Physical: pdu=DCM_E3V_SAM_LIN6_XIX_TPCHType_LIN_Diagnose_XIX_0x0_XIX_0x1C_XIX_Physical, from SAM
        pdu triggering PT_E3V_SAM_LIN6_XIX_TPCHType_LIN_Diagnose_XIX_0x1C_XIX_0x0_XIX_Physical: pdu=DCM_E3V_SAM_LIN6_XIX_TPCHType_LIN_Diagnose_XIX_0x1C_XIX_0x0_XIX_Physical, to SAM
        lin schedule table DiagRequest: resume-position=CONTINUE-AT-IT-POSITION, run-mode=RUN-ONCE, application-entry{delay=0.01, position-in-table=0, frame-triggering=CHNL/FT_MasterReq}
        lin schedule table DiagResponse: resume-position=CONTINUE-AT-IT-POSITION, run-mode=RUN-ONCE, application-entry{delay=0.01, position-in-table=0, frame-triggering=CHNL/FT_SlaveResp}
        lin schedule table st_main: resume-position=CONTINUE-AT-IT-POSITION, run-mode=RUN-CONTINUOUS
          table-entrys:
            delay=0.02, position-in-table=0, frame-triggering=FT_GRA_ACCs_01
            delay=0.01, position-in-table=1, frame-triggering=FT_LIN_SMLSe_01
            delay=0.02, position-in-table=2, frame-triggering=FT_GRA_ACCs_01
            delay=0.01, position-in-table=3, frame-triggering=FT_LIN_SMLSs_01
            delay=0.03, position-in-table=4, frame-triggering=FT_GRA_ACCs_01
            delay=0.02, position-in-table=5, frame-triggering=FT_GRA_ACCs_01
            delay=0.01, position-in-table=6, frame-triggering=FT_LIN_SMLSs_01
